VERSION "HNNBNNNYNNNNNNNNNNNNNNNNNNNNNNNNNNNNNNNNNN/4/%%%/4/'%**4NNN///"

NS_ :

BS_:

BU_: AFS_B8 Airbag_B8 Daempfer_B8 Gateway_B8 Getriebe_AL6000 Getriebe_DL5001 Getriebe_VL3002 LWR_B8 Motor_EDC17_003 Motor_EDC17_004 Motor_MED17_B8 Motor_MED9_B8 Motor_SIMOS8_B8 Motor_Slave_B8 Getriebe_AL1000 Motor_MED17_SIMOS8 Motor_EDC17 Gateway_Routing_PAG Gateway_VW EPB_D4 Motor_EDC17_D4 Motor_MED17_003 Hybrid_MSG Hybrid_DQ200 Motor_ME17_BY Motor_MED17_SIMOS8_D4 Motor_EDC17_B8 Getriebe_AL551_951_D4_C7 Getriebe_AL551_Hybrid_D4_C7 Getriebe_DL501_C7 Getriebe_VL381_C7 Motor_MED17_SIMOS8_D4_Hybrid SCU_D4 Gateway_D4C7 Motor_MED17_Q5_Hybrid Fahrwerk STH_D4 Airbag_D4 Gateway_PAG_002 Gateway_VW_T003 Gateway_D4 LEH_Hybrid SCR_C7 BMS_Hybrid Gateway_App_PAG Getriebe_AL1004 Motor_MED17_006 Getriebe_AL5000

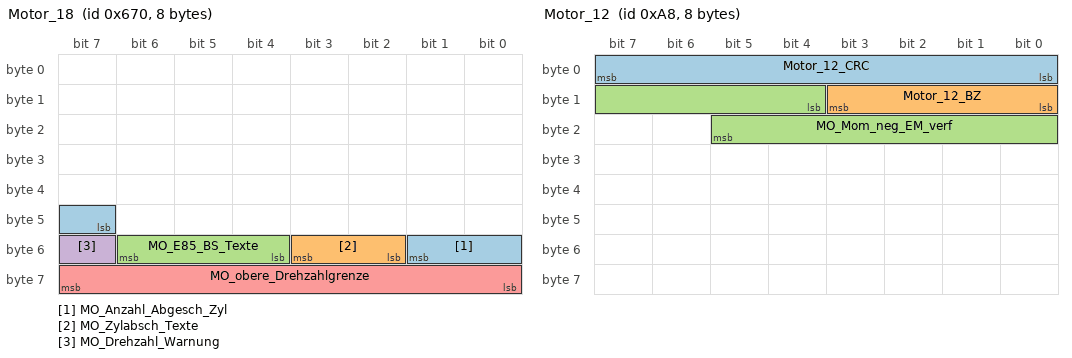
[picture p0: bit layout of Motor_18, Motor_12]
BO_ 1648 Motor_18: 8 Motor_EDC17_D4
 SG_ MO_Anzahl_Abgesch_Zyl : 47|3@1+ (1,0) [0|7] ""  Gateway_D4C7,Getriebe_AL551_951_D4_C7,Getriebe_DL501_C7
 SG_ MO_Zylabsch_Texte : 50|2@1+ (1,0) [0|3] ""  Gateway_D4C7
 SG_ MO_E85_BS_Texte : 52|3@1+ (1,0) [0|7] ""  Gateway_D4C7
 SG_ MO_Drehzahl_Warnung : 55|1@1+ (1,0) [0|1] ""  Gateway_D4C7
 SG_ MO_obere_Drehzahlgrenze : 56|8@1+ (50,0) [50|12750] "Unit_MinutInver"  Gateway_D4C7

BO_ 168 Motor_12: 8 Motor_MED17_Q5_Hybrid
 SG_ Motor_12_CRC : 0|8@1+ (1,0) [0|255] ""  Gateway_B8
 SG_ Motor_12_BZ : 8|4@1+ (1,0) [0|15] ""  Gateway_B8
 SG_ MO_Mom_neg_EM_verf : 12|10@1+ (1,0) [0|1021] "Unit_NewtoMeter"  Gateway_B8

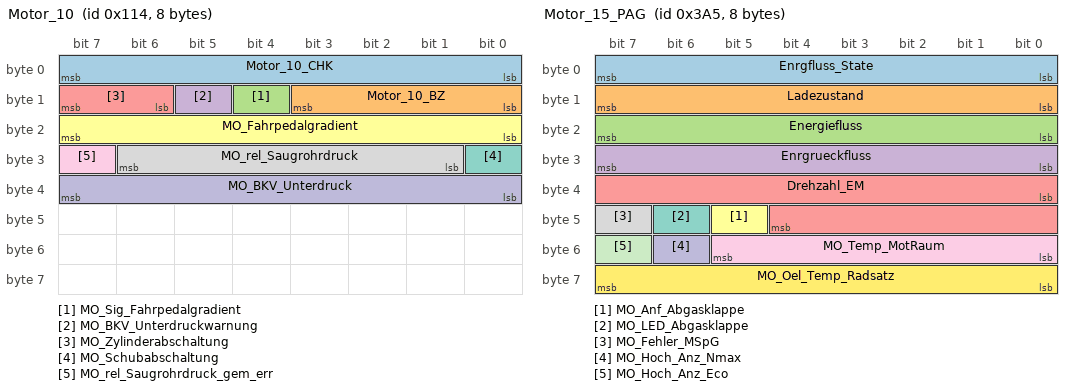
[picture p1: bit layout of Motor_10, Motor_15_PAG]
BO_ 276 Motor_10: 8 Motor_EDC17
 SG_ Motor_10_CHK : 0|8@1+ (1,0) [0|255] ""  Gateway_Routing_PAG,Gateway_VW
 SG_ Motor_10_BZ : 8|4@1+ (1,0) [0|15] ""  Gateway_Routing_PAG,Gateway_VW
 SG_ MO_Sig_Fahrpedalgradient : 12|1@1+ (1,0) [0|1] ""  Gateway_Routing_PAG,Gateway_VW
 SG_ MO_BKV_Unterdruckwarnung : 13|1@1+ (1,0) [0|1] ""  Gateway_Routing_PAG,Gateway_VW
 SG_ MO_Zylinderabschaltung : 14|2@1+ (1,0) [0|3] ""  Gateway_Routing_PAG,Gateway_VW
 SG_ MO_Fahrpedalgradient : 16|8@1+ (25,0) [0|6350] "Unit_PerCentPerSecon"  Gateway_Routing_PAG,Gateway_VW
 SG_ MO_Schubabschaltung : 24|1@1+ (1,0) [0|1] ""  Gateway_Routing_PAG,Gateway_VW
 SG_ MO_rel_Saugrohrdruck : 25|6@1+ (18,0) [0|1116] "Unit_MilliBar"  Gateway_Routing_PAG,Gateway_VW
 SG_ MO_rel_Saugrohrdruck_gem_err : 31|1@1+ (1,0) [0|1] ""  Gateway_Routing_PAG,Gateway_VW
 SG_ MO_BKV_Unterdruck : 32|8@1+ (4,0) [0|1012] "Unit_MilliBar"  Gateway_Routing_PAG,Gateway_VW

BO_ 933 Motor_15_PAG: 8 Motor_EDC17
 SG_ Enrgfluss_State : 0|8@1+ (1,0) [0|254] ""  Gateway_Routing_PAG
 SG_ Ladezustand : 8|8@1+ (1,0) [0|100] "Unit_PerCent"  Gateway_Routing_PAG
 SG_ Energiefluss : 16|8@1+ (1,-128) [-100|100] "Unit_PerCent"  Gateway_Routing_PAG
 SG_ Enrgrueckfluss : 24|8@1+ (0.2,0) [0|50.8] ""  Gateway_Routing_PAG
 SG_ Drehzahl_EM : 32|13@1+ (1,0) [0|8000] ""  Gateway_Routing_PAG
 SG_ MO_Anf_Abgasklappe : 45|1@1+ (1,0) [0|1] ""  Gateway_Routing_PAG
 SG_ MO_LED_Abgasklappe : 46|1@1+ (1,0) [0|1] ""  Gateway_Routing_PAG
 SG_ MO_Fehler_MSpG : 47|1@1+ (1,0) [0|1] ""  Gateway_Routing_PAG
 SG_ MO_Temp_MotRaum : 48|6@1+ (3,-48) [-48|141] "Unit_DegreCelsi"  Gateway_Routing_PAG
 SG_ MO_Hoch_Anz_Nmax : 54|1@1+ (1,0) [0|1] ""  Gateway_Routing_PAG
 SG_ MO_Hoch_Anz_Eco : 55|1@1+ (1,0) [0|1] ""  Gateway_Routing_PAG
 SG_ MO_Oel_Temp_Radsatz : 56|8@1+ (1,-60) [-60|193] "Unit_DegreCelsi"  Gateway_Routing_PAG

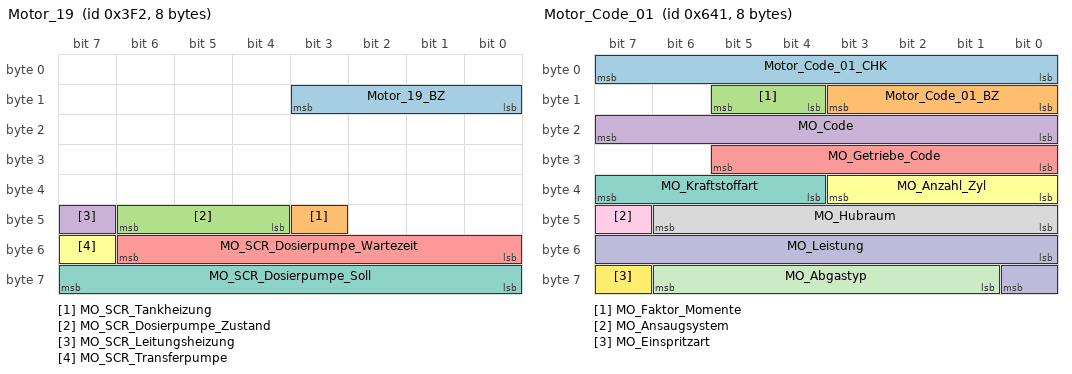
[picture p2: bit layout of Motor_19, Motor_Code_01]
BO_ 1010 Motor_19: 8 Motor_EDC17_D4
 SG_ Motor_19_BZ : 8|4@1+ (1,0) [0|15] ""  SCR_C7
 SG_ MO_SCR_Tankheizung : 43|1@1+ (1,0) [0|1] ""  SCR_C7
 SG_ MO_SCR_Dosierpumpe_Zustand : 44|3@1+ (1,0) [0|7] ""  SCR_C7
 SG_ MO_SCR_Leitungsheizung : 47|1@1+ (1,0) [0|1] ""  SCR_C7
 SG_ MO_SCR_Dosierpumpe_Wartezeit : 48|7@1+ (1,0) [0|120] "Unit_Secon"  SCR_C7
 SG_ MO_SCR_Transferpumpe : 55|1@1+ (1,0) [0|1] ""  SCR_C7
 SG_ MO_SCR_Dosierpumpe_Soll : 56|8@1+ (0.4,0) [0|100] "Unit_PerCent"  SCR_C7

BO_ 1601 Motor_Code_01: 8 Motor_EDC17_003
 SG_ Motor_Code_01_CHK : 0|8@1+ (1,0) [0|255] ""  Daempfer_B8,Gateway_B8,Getriebe_AL6000,Getriebe_DL5001,Getriebe_VL3002
 SG_ Motor_Code_01_BZ : 8|4@1+ (1,0) [0|15] ""  Daempfer_B8,Gateway_B8,Getriebe_AL6000,Getriebe_DL5001,Getriebe_VL3002
 SG_ MO_Faktor_Momente : 12|2@1+ (1,0) [0|3] ""  Daempfer_B8,Gateway_B8,Getriebe_AL6000,Getriebe_DL5001,Getriebe_VL3002
 SG_ MO_Code : 16|8@1+ (1,0) [0|255] ""  Gateway_B8,Getriebe_AL6000,Getriebe_DL5001,Getriebe_VL3002
 SG_ MO_Getriebe_Code : 24|6@1+ (1,0) [0|63] ""  Gateway_B8,Getriebe_AL6000,Getriebe_DL5001,Getriebe_VL3002
 SG_ MO_Anzahl_Zyl : 32|4@1+ (1,0) [0|15] ""  Gateway_B8
 SG_ MO_Kraftstoffart : 36|4@1+ (1,0) [0|15] ""  Gateway_B8
 SG_ MO_Hubraum : 40|7@1+ (0.1,0) [0|12.7] "l"  Gateway_B8
 SG_ MO_Ansaugsystem : 47|1@1+ (1,0) [0|1] ""  Gateway_B8
 SG_ MO_Leistung : 48|9@1+ (1,0) [0|511] "kW"  Gateway_B8
 SG_ MO_Abgastyp : 57|6@1+ (1,0) [0|63] ""  Gateway_B8,Getriebe_AL6000
 SG_ MO_Einspritzart : 63|1@1+ (1,0) [0|1] ""  Gateway_B8

BO_ 157 Motor_Hybrid_01: 8 Motor_MED17_SIMOS8
 SG_ Motor_Hybrid_01_CHK : 0|8@1+ (1,0) [0|255] ""  Getriebe_AL1000
 SG_ Motor_Hybrid_01_BZ : 8|4@1+ (1,0) [0|15] ""  BMS_Hybrid,Getriebe_AL1000
 SG_ MO_HYB_IstStatusK0 : 12|2@1+ (1,0) [0|3] ""  Getriebe_AL1000
 SG_ MO_HYB_max_ind_VM_Mom : 16|10@1+ (1,0) [0|1021] "Unit_NewtoMeter"  Getriebe_AL1000
 SG_ MO_HYB_Zielzustand : 26|3@1+ (1,0) [0|7] ""  BMS_Hybrid,Gateway_App_PAG,Getriebe_AL1000
 SG_ MO_HYB_Startmodus : 29|3@1+ (1,0) [0|7] ""  Getriebe_AL1000
 SG_ MO_HYB_Startmodus_PQ3x : 32|1@1+ (1,0) [0|1] "" Vector__XXX
 SG_ MO_HYB_Stoppmodus : 33|1@1+ (1,0) [0|1] "" Vector__XXX
 SG_ MO_HYB_VM_Mom_oE : 40|10@1+ (1,-100) [-100|922] "Unit_NewtoMeter"  Getriebe_AL1000
 SG_ MO_HYB_VM_aktiv : 50|1@1+ (1,0) [0|1] ""  Gateway_Routing_PAG,Getriebe_AL1000
 SG_ MO_HYB_Schaltverhinderung : 51|1@1+ (1,0) [0|1] ""  Getriebe_AL1000
 SG_ MO_HYB_Selektor_Momverlauf_EM M : 53|3@1+ (1,0) [0|7] ""  Getriebe_AL1000
 SG_ MO_HYB_Momverlauf_Rek m1 : 56|8@1+ (2,0) [0|510] "Unit_NewtoMeter"  Getriebe_AL1000
 SG_ MO_HYB_KnickDZ_Rek m2 : 56|8@1+ (12.5,0) [0|3150] "Unit_MinutInver"  Getriebe_AL1000
 SG_ MO_HYB_Momverlauf_EM m3 : 56|8@1+ (2,0) [0|510] "Unit_NewtoMeter"  Getriebe_AL1000
 SG_ MO_HYB_KnickDZ_EM m4 : 56|8@1+ (12.5,0) [0|3150] "Unit_MinutInver"  Getriebe_AL1000

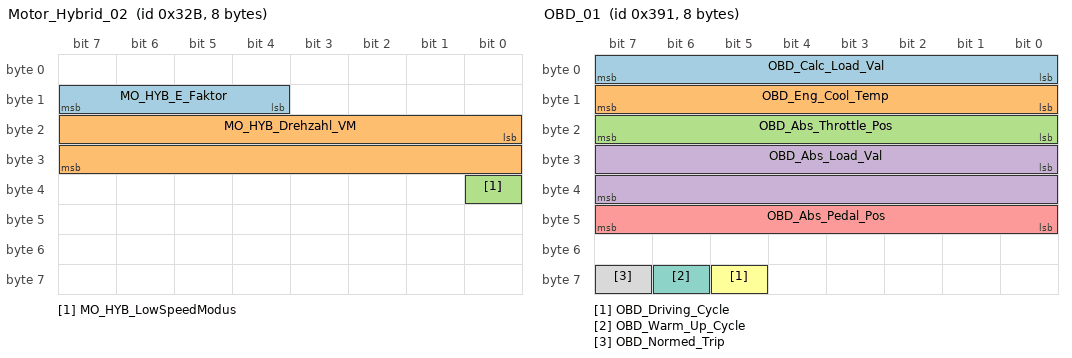
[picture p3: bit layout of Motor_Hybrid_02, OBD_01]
BO_ 811 Motor_Hybrid_02: 8 Motor_MED17_006
 SG_ MO_HYB_E_Faktor : 12|4@1+ (1,0) [0|15] ""  Getriebe_AL1004
 SG_ MO_HYB_Drehzahl_VM : 16|16@1+ (0.25,0) [0|16256] "Unit_MinutInver"  Getriebe_AL1004
 SG_ MO_HYB_LowSpeedModus : 32|1@1+ (1,0) [0|1] ""  Getriebe_AL1004

BO_ 1090 MotorSlave_01: 1 Motor_Slave_B8
 SG_ MOS_KD_Fehler : 0|1@1+ (1,0) [0|1] ""  Gateway_B8

BO_ 1728 NMH_Gateway: 7 Gateway_B8
 SG_ NMH_GW_Start_1 : 0|1@1+ (1,0) [0|1] ""  Getriebe_AL6000,Getriebe_DL5001,Getriebe_VL3002,Motor_EDC17_003,Motor_EDC17_004,Motor_MED17_B8,Motor_MED9_B8,Motor_SIMOS8_B8
 SG_ NMH_GW_Start_2 : 1|1@1+ (1,0) [0|1] "" Vector__XXX
 SG_ NMH_GW_Normal_Mode_1 : 2|1@1+ (1,0) [0|1] "" Vector__XXX
 SG_ NMH_GW_Normal_Mode_2 : 3|1@1+ (1,0) [0|1] "" Vector__XXX
 SG_ NMH_GW_Car_WakeUp : 6|1@1+ (1,0) [0|1] "" Vector__XXX
 SG_ NMH_GW_Per_WakeUp : 8|5@1+ (1,0) [0|31] "" Vector__XXX
 SG_ NMH_GW_Fkt_WakeUp : 13|3@1+ (1,0) [0|7] "" Vector__XXX
 SG_ NMH_GW_NM_aktiv_Klemme_15 : 16|1@1+ (1,0) [0|1] "" Vector__XXX
 SG_ NMH_GW_NM_aktiv_Diagnose : 17|1@1+ (1,0) [0|1] "" Vector__XXX
 SG_ NMH_GW_NM_aktiv_Start : 18|1@1+ (1,0) [0|1] "" Vector__XXX
 SG_ NMH_GW_NM_aktiv_BDM : 19|1@1+ (1,0) [0|1] "" Vector__XXX
 SG_ NMH_GW_NM_aktiv_Warnblinken : 20|1@1+ (1,0) [0|1] "" Vector__XXX
 SG_ NMH_GW_NM_aktiv_ESP : 21|1@1+ (1,0) [0|1] "" Vector__XXX
 SG_ NMH_GW_Abschaltstufe_3 : 24|1@1+ (1,0) [0|1] "" Vector__XXX
 SG_ NMH_GW_SG_Fehlerdauer : 25|1@1+ (1,0) [0|1] "" Vector__XXX
 SG_ NMH_GW_STH_Wakeup : 26|1@1+ (1,0) [0|1] "" Vector__XXX
 SG_ NMH_GW_TimeOut_Fehler : 33|1@1+ (1,0) [0|1] "" Vector__XXX
 SG_ NMH_GW_CAN_Diag_deaktiv : 34|1@1+ (1,0) [0|1] "" Vector__XXX
 SG_ NMH_GW_KompSchutz : 35|1@1+ (1,0) [0|1] "" Vector__XXX
 SG_ NMH_GW_Mute_Mode : 36|1@1+ (1,0) [0|1] "" Vector__XXX
 SG_ NMH_GW_Transport_Mode : 37|1@1+ (1,0) [0|1] "" Vector__XXX
 SG_ NMH_GW_Abschaltstufe_aktiv : 38|1@1+ (1,0) [0|1] "" Vector__XXX
 SG_ NMH_GW_Eindraht_Fehler : 39|1@1+ (1,0) [0|1] "" Vector__XXX
 SG_ NMH_GW_ACAN : 40|1@1+ (1,0) [0|1] "" Vector__XXX
 SG_ NMH_GW_KombiCAN : 41|1@1+ (1,0) [0|1] "" Vector__XXX
 SG_ NMH_GW_KomfortCAN : 42|1@1+ (1,0) [0|1] "" Vector__XXX
 SG_ NMH_GW_Infotainment : 43|1@1+ (1,0) [0|1] "" Vector__XXX
 SG_ NMH_GW_WakeUp_CAN_Bus : 48|3@1+ (1,0) [0|7] "" Vector__XXX

BO_ 1730 NMH_Getriebe: 7 Getriebe_AL6000
 SG_ NMH_GE_Start_1 : 0|1@1+ (1,0) [0|1] ""  Motor_EDC17_003,Motor_EDC17_004,Motor_MED17_B8,Motor_MED9_B8,Motor_SIMOS8_B8
 SG_ NMH_GE_Start_2 : 1|1@1+ (1,0) [0|1] "" Vector__XXX
 SG_ NMH_GE_Normal_Mode_1 : 2|1@1+ (1,0) [0|1] "" Vector__XXX
 SG_ NMH_GE_Normal_Mode_2 : 3|1@1+ (1,0) [0|1] "" Vector__XXX
 SG_ NMH_GE_Car_WakeUp : 6|1@1+ (1,0) [0|1] ""  Gateway_B8
 SG_ NMH_GE_Per_WakeUp : 8|5@1+ (1,0) [0|31] "" Vector__XXX
 SG_ NMH_GE_Fkt_WakeUp : 13|3@1+ (1,0) [0|7] "" Vector__XXX
 SG_ NMH_GE_NM_aktiv_Klemme_15 : 16|1@1+ (1,0) [0|1] "" Vector__XXX
 SG_ NMH_GE_NM_aktiv_Diagnose : 17|1@1+ (1,0) [0|1] "" Vector__XXX
 SG_ NMH_GE_NM_aktiv_Start : 18|1@1+ (1,0) [0|1] "" Vector__XXX
 SG_ NMH_GE_kein_NL : 24|1@1+ (1,0) [0|1] "" Vector__XXX
 SG_ NMH_GE_NL_Daten_EEPROM : 25|1@1+ (1,0) [0|1] "" Vector__XXX
 SG_ NMH_GE_NL_Drucksens : 26|1@1+ (1,0) [0|1] "" Vector__XXX
 SG_ NMH_GE_NL_Abtrieb : 27|1@1+ (1,0) [0|1] "" Vector__XXX
 SG_ NMH_GE_NL_Waehlhebel : 28|1@1+ (1,0) [0|1] "" Vector__XXX
 SG_ NMH_GE_NL_Wegfahrsperre : 29|1@1+ (1,0) [0|1] "" Vector__XXX
 SG_ NMH_GE_TimeOut_Fehler : 33|1@1+ (1,0) [0|1] "" Vector__XXX
 SG_ NMH_GE_CAN_Diag_deaktiv : 34|1@1+ (1,0) [0|1] "" Vector__XXX
 SG_ NMH_GE_KompSchutz : 35|1@1+ (1,0) [0|1] "" Vector__XXX
 SG_ NMH_GE_Mute_Mode : 36|1@1+ (1,0) [0|1] "" Vector__XXX
 SG_ NMH_GE_Transport_Mode : 37|1@1+ (1,0) [0|1] "" Vector__XXX
 SG_ NMH_GE_Abschaltstufe_aktiv : 38|1@1+ (1,0) [0|1] "" Vector__XXX
 SG_ NMH_GE_Eindraht_Fehler : 39|1@1+ (1,0) [0|1] "" Vector__XXX

BO_ 1729 NMH_Motor: 7 Motor_EDC17_B8
 SG_ NMH_MO_Start_1 : 0|1@1+ (1,0) [0|1] ""  Getriebe_AL6000,Getriebe_DL5001,Getriebe_VL3002,Motor_EDC17_B8,Motor_MED17_003,Motor_MED9_B8
 SG_ NMH_MO_Start_2 : 1|1@1+ (1,0) [0|1] "" Vector__XXX
 SG_ NMH_MO_Normal_Mode_1 : 2|1@1+ (1,0) [0|1] "" Vector__XXX
 SG_ NMH_MO_Normal_Mode_2 : 3|1@1+ (1,0) [0|1] "" Vector__XXX
 SG_ NMH_MO_Car_WakeUp : 6|1@1+ (1,0) [0|1] ""  Gateway_B8
 SG_ NMH_MO_Per_WakeUp : 8|5@1+ (1,0) [0|31] "" Vector__XXX
 SG_ NMH_MO_Fkt_WakeUp : 13|3@1+ (1,0) [0|7] "" Vector__XXX
 SG_ NMH_MO_NM_aktiv_Klemme_15 : 16|1@1+ (1,0) [0|1] "" Vector__XXX
 SG_ NMH_MO_NM_aktiv_Diagnose : 17|1@1+ (1,0) [0|1] "" Vector__XXX
 SG_ NMH_MO_NM_aktiv_Start : 18|1@1+ (1,0) [0|1] "" Vector__XXX
 SG_ NMH_MO_NM_aktiv_EKP_Vorlauf : 19|1@1+ (1,0) [0|1] "" Vector__XXX
 SG_ NMH_MO_NM_aktiv_STH_Betrieb : 20|1@1+ (1,0) [0|1] "" Vector__XXX
 SG_ NMH_MO_NM_aktiv_HV_Abschaltung : 21|1@1+ (1,0) [0|1] "" Vector__XXX
 SG_ NMH_MO_kein_NL : 24|1@1+ (1,0) [0|1] "" Vector__XXX
 SG_ NMH_MO_NL_Kuehlerluefter : 25|1@1+ (1,0) [0|1] "" Vector__XXX
 SG_ NMH_MO_NL_Diagnose : 26|1@1+ (1,0) [0|1] "" Vector__XXX
 SG_ NMH_MO_NL_WFS : 27|1@1+ (1,0) [0|1] "" Vector__XXX
 SG_ NMH_MO_NL_EEPROM : 28|1@1+ (1,0) [0|1] "" Vector__XXX
 SG_ NMH_MO_NL_Sonstige : 29|1@1+ (1,0) [0|1] "" Vector__XXX
 SG_ NMH_MO_TimeOut_Fehler : 33|1@1+ (1,0) [0|1] "" Vector__XXX
 SG_ NMH_MO_CAN_Diag_deaktiv : 34|1@1+ (1,0) [0|1] "" Vector__XXX
 SG_ NMH_MO_KompSchutz : 35|1@1+ (1,0) [0|1] "" Vector__XXX
 SG_ NMH_MO_Mute_Mode : 36|1@1+ (1,0) [0|1] "" Vector__XXX
 SG_ NMH_MO_Transport_Mode : 37|1@1+ (1,0) [0|1] "" Vector__XXX
 SG_ NMH_MO_Abschaltstufe_aktiv : 38|1@1+ (1,0) [0|1] "" Vector__XXX
 SG_ NMH_MO_Eindraht_Fehler : 39|1@1+ (1,0) [0|1] "" Vector__XXX
 SG_ NMH_MO_Lokalaktiv : 48|1@1+ (1,0) [0|1] ""  Gateway_B8
 SG_ NMH_MO_Subsystemaktiv : 49|1@1+ (1,0) [0|1] ""  Gateway_B8

BO_ 913 OBD_01: 8 Motor_EDC17_003
 SG_ OBD_Calc_Load_Val : 0|8@1+ (0.39215686275,0) [0|99.6061] "%"  Getriebe_AL6000,Getriebe_DL5001,Getriebe_VL3002
 SG_ OBD_Eng_Cool_Temp : 8|8@1+ (1,-40) [-40|214] "°C"  Getriebe_AL6000,Getriebe_DL5001,Getriebe_VL3002
 SG_ OBD_Abs_Throttle_Pos : 16|8@1+ (0.39215686275,0) [0|99.6061] "%"  Getriebe_AL6000,Getriebe_DL5001,Getriebe_VL3002
 SG_ OBD_Abs_Load_Val : 24|16@1+ (0.39215686275,0) [0|25699.1581] "%"  Getriebe_AL6000,Getriebe_DL5001,Getriebe_VL3002
 SG_ OBD_Abs_Pedal_Pos : 40|8@1+ (0.39215686275,0) [0|99.6061] "%"  Getriebe_AL6000,Getriebe_DL5001,Getriebe_VL3002
 SG_ OBD_Driving_Cycle : 61|1@1+ (1,0) [0|1] ""  Getriebe_AL6000,Getriebe_DL5001,Getriebe_VL3002
 SG_ OBD_Warm_Up_Cycle : 62|1@1+ (1,0) [0|1] ""  Gateway_B8,Getriebe_AL6000,Getriebe_DL5001,Getriebe_VL3002
 SG_ OBD_Normed_Trip : 63|1@1+ (1,0) [0|1] ""  Getriebe_AL6000,Getriebe_DL5001,Getriebe_VL3002

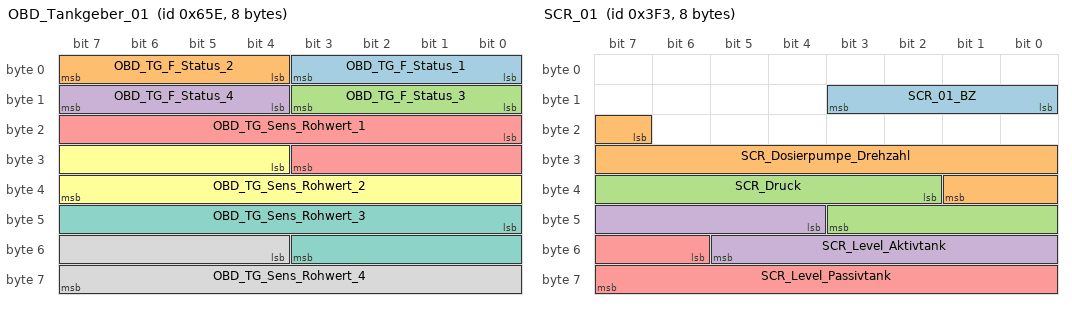
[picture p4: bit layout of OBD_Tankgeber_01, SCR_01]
BO_ 1630 OBD_Tankgeber_01: 8 Gateway_B8
 SG_ OBD_TG_F_Status_1 : 0|4@1+ (1,0) [0|15] ""  Motor_EDC17_003,Motor_EDC17_004,Motor_MED17_B8,Motor_MED9_B8,Motor_SIMOS8_B8
 SG_ OBD_TG_F_Status_2 : 4|4@1+ (1,0) [0|15] ""  Motor_EDC17_003,Motor_EDC17_004,Motor_MED17_B8,Motor_MED9_B8,Motor_SIMOS8_B8
 SG_ OBD_TG_F_Status_3 : 8|4@1+ (1,0) [0|15] ""  Motor_EDC17_003,Motor_EDC17_004,Motor_MED17_B8,Motor_MED9_B8,Motor_SIMOS8_B8
 SG_ OBD_TG_F_Status_4 : 12|4@1+ (1,0) [0|15] ""  Motor_EDC17_003,Motor_EDC17_004,Motor_MED17_B8,Motor_MED9_B8,Motor_SIMOS8_B8
 SG_ OBD_TG_Sens_Rohwert_1 : 16|12@1+ (0.5,0) [0|2047.5] "Ohm"  Motor_EDC17_003,Motor_EDC17_004,Motor_MED17_B8,Motor_MED9_B8,Motor_SIMOS8_B8
 SG_ OBD_TG_Sens_Rohwert_2 : 28|12@1+ (0.5,0) [0|2047.5] "Ohm"  Motor_EDC17_003,Motor_EDC17_004,Motor_MED17_B8,Motor_MED9_B8,Motor_SIMOS8_B8
 SG_ OBD_TG_Sens_Rohwert_3 : 40|12@1+ (0.5,0) [0|2047.5] "Ohm"  Motor_EDC17_003,Motor_EDC17_004,Motor_MED17_B8,Motor_MED9_B8,Motor_SIMOS8_B8
 SG_ OBD_TG_Sens_Rohwert_4 : 52|12@1+ (0.5,0) [0|2047.5] "Ohm"  Motor_EDC17_003,Motor_EDC17_004,Motor_MED17_B8,Motor_MED9_B8,Motor_SIMOS8_B8

BO_ 1011 SCR_01: 8 SCR_C7
 SG_ SCR_01_BZ : 8|4@1+ (1,0) [0|15] ""  Motor_EDC17_D4
 SG_ SCR_Dosierpumpe_Drehzahl : 23|11@1+ (4,-4080) [-4080|4100] "Unit_MinutInver"  Motor_EDC17_D4
 SG_ SCR_Druck : 34|10@1+ (5,0) [0|5000] "Unit_MilliVolt"  Motor_EDC17_D4
 SG_ SCR_Level_Aktivtank : 44|10@1+ (5,0) [0|5000] "Unit_MilliVolt"  Motor_EDC17_D4
 SG_ SCR_Level_Passivtank : 54|10@1+ (5,0) [0|5000] "Unit_MilliVolt"  Motor_EDC17_D4

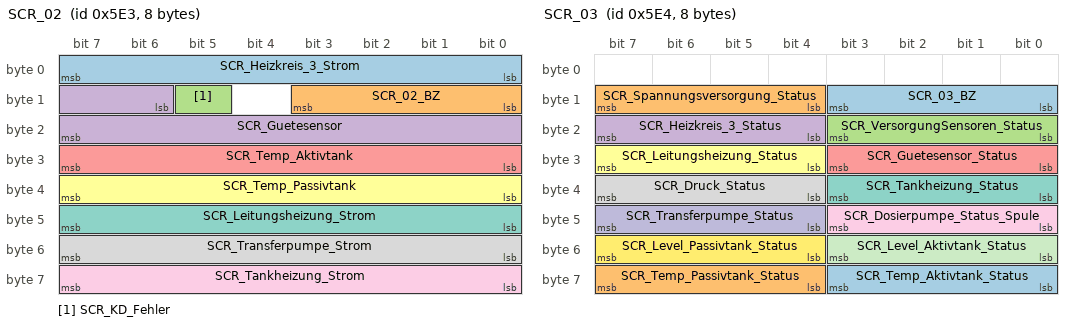
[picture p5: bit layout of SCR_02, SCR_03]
BO_ 1507 SCR_02: 8 SCR_C7
 SG_ SCR_Heizkreis_3_Strom : 0|8@1+ (0.1,0) [0|14] "Unit_Amper"  Motor_EDC17_D4
 SG_ SCR_02_BZ : 8|4@1+ (1,0) [0|15] ""  Motor_EDC17_D4
 SG_ SCR_KD_Fehler : 13|1@1+ (1,0) [0|1] ""  Gateway_D4C7
 SG_ SCR_Guetesensor : 14|10@1+ (5,0) [0|5000] "Unit_MilliVolt"  Motor_EDC17_D4
 SG_ SCR_Temp_Aktivtank : 24|8@1+ (20,0) [0|5000] "Unit_MilliVolt"  Motor_EDC17_D4
 SG_ SCR_Temp_Passivtank : 32|8@1+ (20,0) [0|5000] "Unit_MilliVolt"  Motor_EDC17_D4
 SG_ SCR_Leitungsheizung_Strom : 40|8@1+ (0.1,0) [0|14] "Unit_Amper"  Motor_EDC17_D4
 SG_ SCR_Transferpumpe_Strom : 48|8@1+ (0.1,0) [0|14] "Unit_Amper"  Motor_EDC17_D4
 SG_ SCR_Tankheizung_Strom : 56|8@1+ (0.1,0) [0|14] "Unit_Amper"  Motor_EDC17_D4

BO_ 1508 SCR_03: 8 SCR_C7
 SG_ SCR_03_BZ : 8|4@1+ (1,0) [0|15] ""  Motor_EDC17_D4
 SG_ SCR_Spannungsversorgung_Status : 12|4@1+ (1,0) [0|15] ""  Motor_EDC17_D4
 SG_ SCR_VersorgungSensoren_Status : 16|4@1+ (1,0) [0|15] ""  Motor_EDC17_D4
 SG_ SCR_Heizkreis_3_Status : 20|4@1+ (1,0) [0|15] ""  Motor_EDC17_D4
 SG_ SCR_Guetesensor_Status : 24|4@1+ (1,0) [0|15] ""  Motor_EDC17_D4
 SG_ SCR_Leitungsheizung_Status : 28|4@1+ (1,0) [0|15] ""  Motor_EDC17_D4
 SG_ SCR_Tankheizung_Status : 32|4@1+ (1,0) [0|15] ""  Motor_EDC17_D4
 SG_ SCR_Druck_Status : 36|4@1+ (1,0) [0|15] ""  Motor_EDC17_D4
 SG_ SCR_Dosierpumpe_Status_Spule : 40|4@1+ (1,0) [0|15] ""  Motor_EDC17_D4
 SG_ SCR_Transferpumpe_Status : 44|4@1+ (1,0) [0|15] ""  Motor_EDC17_D4
 SG_ SCR_Level_Aktivtank_Status : 48|4@1+ (1,0) [0|15] ""  Motor_EDC17_D4
 SG_ SCR_Level_Passivtank_Status : 52|4@1+ (1,0) [0|15] ""  Motor_EDC17_D4
 SG_ SCR_Temp_Aktivtank_Status : 56|4@1+ (1,0) [0|15] ""  Motor_EDC17_D4
 SG_ SCR_Temp_Passivtank_Status : 60|4@1+ (1,0) [0|15] ""  Motor_EDC17_D4

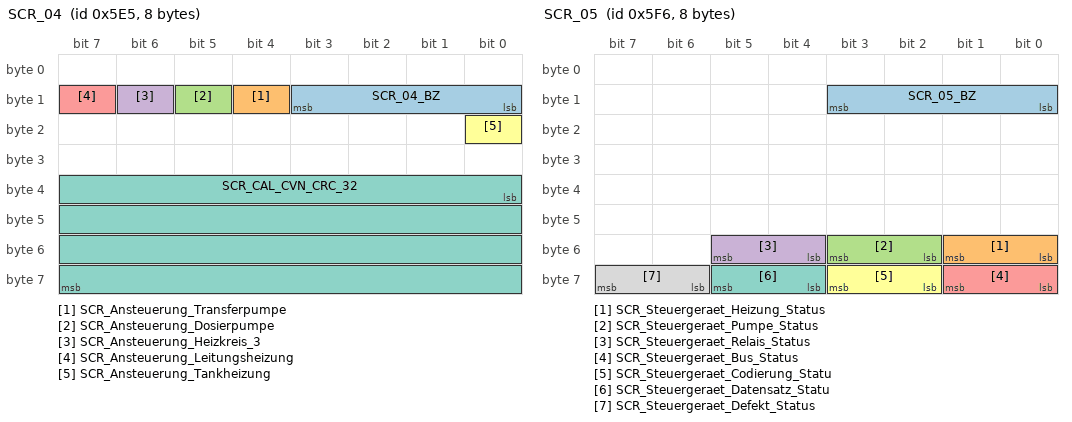
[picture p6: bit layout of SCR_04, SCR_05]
BO_ 1509 SCR_04: 8 SCR_C7
 SG_ SCR_04_BZ : 8|4@1+ (1,0) [0|15] ""  Motor_EDC17_D4
 SG_ SCR_Ansteuerung_Transferpumpe : 12|1@1+ (1,0) [0|1] ""  Motor_EDC17_D4
 SG_ SCR_Ansteuerung_Dosierpumpe : 13|1@1+ (1,0) [0|1] ""  Motor_EDC17_D4
 SG_ SCR_Ansteuerung_Heizkreis_3 : 14|1@1+ (1,0) [0|1] ""  Motor_EDC17_D4
 SG_ SCR_Ansteuerung_Leitungsheizung : 15|1@1+ (1,0) [0|1] ""  Motor_EDC17_D4
 SG_ SCR_Ansteuerung_Tankheizung : 16|1@1+ (1,0) [0|1] ""  Motor_EDC17_D4
 SG_ SCR_CAL_CVN_CRC_32 : 32|32@1+ (1,0) [0|4294967295] ""  Motor_EDC17_D4

BO_ 1526 SCR_05: 8 SCR_C7
 SG_ SCR_05_BZ : 8|4@1+ (1,0) [0|15] ""  Motor_EDC17_D4
 SG_ SCR_Steuergeraet_Heizung_Status : 48|2@1+ (1,0) [0|3] ""  Motor_EDC17_D4
 SG_ SCR_Steuergeraet_Pumpe_Status : 50|2@1+ (1,0) [0|3] ""  Motor_EDC17_D4
 SG_ SCR_Steuergeraet_Relais_Status : 52|2@1+ (1,0) [0|3] ""  Motor_EDC17_D4
 SG_ SCR_Steuergeraet_Bus_Status : 56|2@1+ (1,0) [0|3] ""  Motor_EDC17_D4
 SG_ SCR_Steuergeraet_Codierung_Statu : 58|2@1+ (1,0) [0|3] ""  Motor_EDC17_D4
 SG_ SCR_Steuergeraet_Datensatz_Statu : 60|2@1+ (1,0) [0|3] ""  Motor_EDC17_D4
 SG_ SCR_Steuergeraet_Defekt_Status : 62|2@1+ (1,0) [0|3] ""  Motor_EDC17_D4

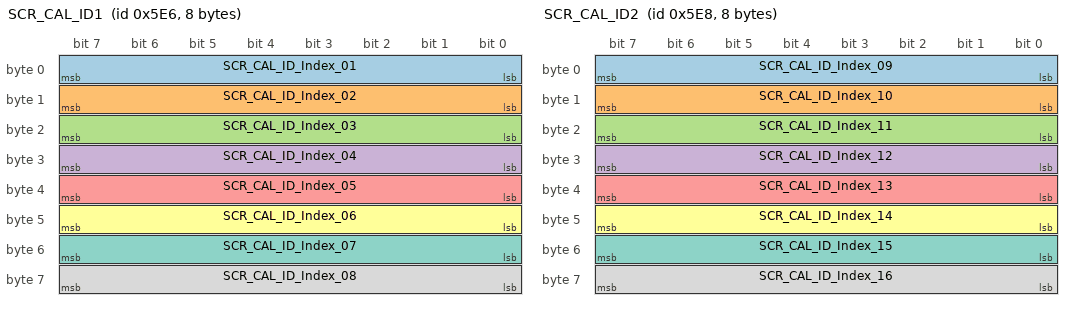
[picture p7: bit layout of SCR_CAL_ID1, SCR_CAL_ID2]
BO_ 1510 SCR_CAL_ID1: 8 SCR_C7
 SG_ SCR_CAL_ID_Index_01 : 0|8@1+ (1,0) [0|255] ""  Motor_EDC17_D4
 SG_ SCR_CAL_ID_Index_02 : 8|8@1+ (1,0) [0|255] ""  Motor_EDC17_D4
 SG_ SCR_CAL_ID_Index_03 : 16|8@1+ (1,0) [0|255] ""  Motor_EDC17_D4
 SG_ SCR_CAL_ID_Index_04 : 24|8@1+ (1,0) [0|255] ""  Motor_EDC17_D4
 SG_ SCR_CAL_ID_Index_05 : 32|8@1+ (1,0) [0|255] ""  Motor_EDC17_D4
 SG_ SCR_CAL_ID_Index_06 : 40|8@1+ (1,0) [0|255] ""  Motor_EDC17_D4
 SG_ SCR_CAL_ID_Index_07 : 48|8@1+ (1,0) [0|255] ""  Motor_EDC17_D4
 SG_ SCR_CAL_ID_Index_08 : 56|8@1+ (1,0) [0|255] ""  Motor_EDC17_D4

BO_ 1512 SCR_CAL_ID2: 8 SCR_C7
 SG_ SCR_CAL_ID_Index_09 : 0|8@1+ (1,0) [0|255] ""  Motor_EDC17_D4
 SG_ SCR_CAL_ID_Index_10 : 8|8@1+ (1,0) [0|255] ""  Motor_EDC17_D4
 SG_ SCR_CAL_ID_Index_11 : 16|8@1+ (1,0) [0|255] ""  Motor_EDC17_D4
 SG_ SCR_CAL_ID_Index_12 : 24|8@1+ (1,0) [0|255] ""  Motor_EDC17_D4
 SG_ SCR_CAL_ID_Index_13 : 32|8@1+ (1,0) [0|255] ""  Motor_EDC17_D4
 SG_ SCR_CAL_ID_Index_14 : 40|8@1+ (1,0) [0|255] ""  Motor_EDC17_D4
 SG_ SCR_CAL_ID_Index_15 : 48|8@1+ (1,0) [0|255] ""  Motor_EDC17_D4
 SG_ SCR_CAL_ID_Index_16 : 56|8@1+ (1,0) [0|255] ""  Motor_EDC17_D4

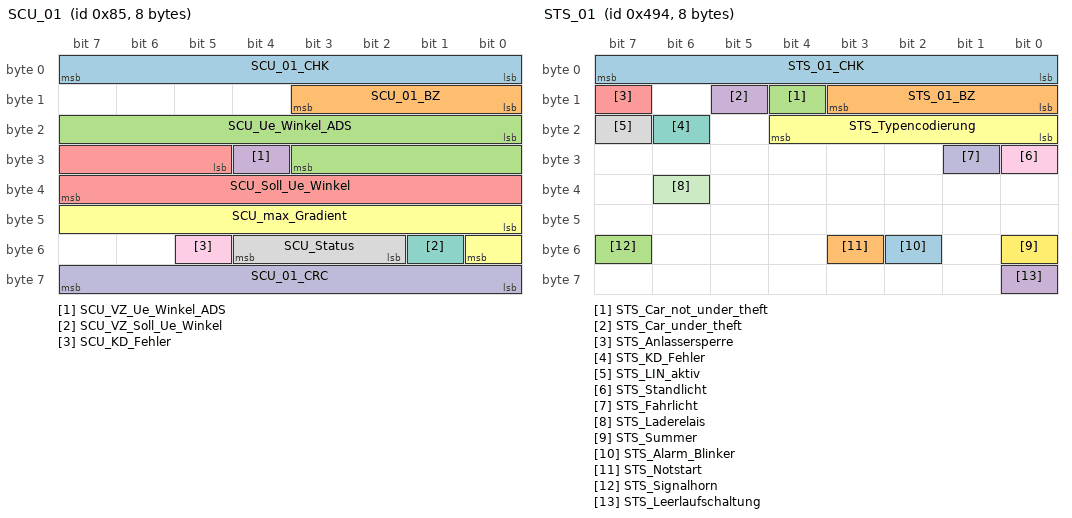
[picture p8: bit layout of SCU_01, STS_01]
BO_ 133 SCU_01: 8 Gateway_B8
 SG_ SCU_01_CHK : 0|8@1+ (1,0) [0|255] ""  Daempfer_B8,Motor_EDC17_003,Motor_EDC17_004,Motor_MED17_B8,Motor_MED9_B8,Motor_SIMOS8_B8
 SG_ SCU_01_BZ : 8|4@1+ (1,0) [0|15] ""  Daempfer_B8,Motor_EDC17_003,Motor_EDC17_004,Motor_MED17_B8,Motor_MED9_B8,Motor_SIMOS8_B8
 SG_ SCU_Ue_Winkel_ADS : 16|12@1+ (0.1,0) [0|409.3] "Grad"  AFS_B8,Daempfer_B8,Motor_EDC17_003,Motor_EDC17_004,Motor_MED17_B8,Motor_MED9_B8,Motor_SIMOS8_B8
 SG_ SCU_VZ_Ue_Winkel_ADS : 28|1@1+ (1,0) [0|1] ""  AFS_B8,Daempfer_B8,Motor_EDC17_003,Motor_EDC17_004,Motor_MED17_B8,Motor_MED9_B8,Motor_SIMOS8_B8
 SG_ SCU_Soll_Ue_Winkel : 29|11@1+ (0.1,0) [0|204.5] "Grad"  AFS_B8
 SG_ SCU_max_Gradient : 40|9@1+ (1,0) [0|510] "" Vector__XXX
 SG_ SCU_VZ_Soll_Ue_Winkel : 49|1@1+ (1,0) [0|1] ""  AFS_B8
 SG_ SCU_Status : 50|3@1+ (1,0) [0|7] ""  AFS_B8,Daempfer_B8,Motor_EDC17_003,Motor_EDC17_004,Motor_MED17_B8,Motor_MED9_B8,Motor_SIMOS8_B8
 SG_ SCU_KD_Fehler : 53|1@1+ (1,0) [0|1] "" Vector__XXX
 SG_ SCU_01_CRC : 56|8@1+ (1,0) [0|255] "" Vector__XXX

BO_ 1313 STH_01: 8 Gateway_B8
 SG_ STH_Funk_ein : 0|1@1+ (1,0) [0|1] "" Vector__XXX
 SG_ STH_Funk_aus : 1|1@1+ (1,0) [0|1] "" Vector__XXX
 SG_ STH_Zusatzheizung : 2|1@1+ (1,0) [0|1] "" Vector__XXX
 SG_ STH_LED : 3|1@1+ (1,0) [0|1] "" Vector__XXX
 SG_ STH_Pumpe_ein : 4|1@1+ (1,0) [0|1] "" Vector__XXX
 SG_ STH_Geblaese : 5|1@1+ (1,0) [0|1] "" Vector__XXX
 SG_ STH_EKP_Anst : 6|1@1+ (1,0) [0|1] ""  Motor_EDC17_003,Motor_EDC17_004,Motor_MED17_B8,Motor_SIMOS8_B8
 SG_ STH_Ventiloeffnungszeit : 8|6@1+ (1,0) [0|63] "min"  Motor_EDC17_003,Motor_EDC17_004,Motor_MED17_B8,Motor_SIMOS8_B8
 SG_ STH_Ventil_Status : 14|1@1+ (1,0) [0|1] "" Vector__XXX
 SG_ STH_Fehler_ElWaPu : 15|1@1+ (1,0) [0|1] ""  Motor_EDC17_D4,Motor_ME17_BY,Motor_MED17_SIMOS8_D4,Motor_MED17_SIMOS8_D4_Hybrid
 SG_ STH_Waermeeintrag : 16|6@1+ (1,0) [0|63] ""  Motor_EDC17_003,Motor_EDC17_004,Motor_MED17_B8,Motor_SIMOS8_B8
 SG_ STH_Pumpen_Anf_extern : 22|1@1+ (1,0) [0|1] "" Vector__XXX
 SG_ STH_KVS : 24|13@1+ (1,0) [0|8191] "ml" Vector__XXX
 SG_ STH_Fehlerstatus : 37|3@1+ (1,0) [0|7] "" Vector__XXX
 SG_ STH_Heizleistung : 40|8@1+ (1,0) [0|255] "" Vector__XXX
 SG_ STH_Wassertemp : 48|8@1+ (0.75,-40) [-40|142.25] "°C" Vector__XXX
 SG_ STH_Motorvorwaermung : 59|1@1+ (1,0) [0|1] ""  Motor_EDC17_003,Motor_EDC17_004,Motor_MED17_B8,Motor_SIMOS8_B8
 SG_ STH_Servicemode : 60|1@1+ (1,0) [0|1] "" Vector__XXX
 SG_ STH_war_aktiv : 61|1@1+ (1,0) [0|1] ""  Motor_EDC17_003,Motor_EDC17_004,Motor_MED17_B8,Motor_SIMOS8_B8
 SG_ STH_KVS_Ueberlauf : 62|1@1+ (1,0) [0|1] "" Vector__XXX
 SG_ STH_KD_Fehler : 63|1@1+ (1,0) [0|1] "" Vector__XXX

BO_ 1172 STS_01: 8 Gateway_D4
 SG_ STS_01_CHK : 0|8@1+ (1,0) [0|255] ""  Motor_EDC17_D4,Motor_MED17_SIMOS8_D4
 SG_ STS_01_BZ : 8|4@1+ (1,0) [0|15] ""  Motor_EDC17_D4,Motor_MED17_SIMOS8_D4
 SG_ STS_Car_not_under_theft : 12|1@1+ (1,0) [0|1] "" Vector__XXX
 SG_ STS_Car_under_theft : 13|1@1+ (1,0) [0|1] "" Vector__XXX
 SG_ STS_Anlassersperre : 15|1@1+ (1,0) [0|1] "" Vector__XXX
 SG_ STS_Typencodierung : 16|5@1+ (1,0) [0|31] "" Vector__XXX
 SG_ STS_KD_Fehler : 22|1@1+ (1,0) [0|1] "" Vector__XXX
 SG_ STS_LIN_aktiv : 23|1@1+ (1,0) [0|1] "" Vector__XXX
 SG_ STS_Standlicht : 24|1@1+ (1,0) [0|1] "" Vector__XXX
 SG_ STS_Fahrlicht : 25|1@1+ (1,0) [0|1] "" Vector__XXX
 SG_ STS_Laderelais : 38|1@1+ (1,0) [0|1] "" Vector__XXX
 SG_ STS_Summer : 48|1@1+ (1,0) [0|1] "" Vector__XXX
 SG_ STS_Alarm_Blinker : 50|1@1+ (1,0) [0|1] "" Vector__XXX
 SG_ STS_Notstart : 51|1@1+ (1,0) [0|1] "" Vector__XXX
 SG_ STS_Signalhorn : 55|1@1+ (1,0) [0|1] "" Vector__XXX
 SG_ STS_Leerlaufschaltung : 56|1@1+ (1,0) [0|1] ""  Motor_EDC17_D4,Motor_MED17_SIMOS8_D4

BO_ 1413 Systeminfo_01: 8 Gateway_B8
 SG_ SI_Int_CAN_gespiegelt : 0|1@1+ (1,0) [0|1] "" Vector__XXX
 SG_ SI_CAN_Komfort_Sleep : 1|1@1+ (1,0) [0|1] "" Vector__XXX
 SG_ SI_CAN_Dashboard_Sleep : 2|1@1+ (1,0) [0|1] "" Vector__XXX
 SG_ SI_CAN_Antrieb_Sleep : 3|1@1+ (1,0) [0|1] "" Vector__XXX
 SG_ SI_Infotainment_Sleep : 4|1@1+ (1,0) [0|1] "" Vector__XXX
 SG_ SI_CAN_Extended_Sleep : 5|1@1+ (1,0) [0|1] "" Vector__XXX
 SG_ SI_Fahrwerk_Sleep : 6|1@1+ (1,0) [0|1] "" Vector__XXX
 SG_ SI_Diagnose_Aktiv : 7|1@1+ (1,0) [0|1] "" Vector__XXX
 SG_ SI_QRS_Mode : 8|1@1+ (1,0) [0|1] ""  Getriebe_AL551_951_D4_C7
 SG_ SI_T_Mode : 9|1@1+ (1,0) [0|1] ""  Getriebe_AL551_951_D4_C7,Motor_EDC17_D4,Motor_ME17_BY,Motor_MED17_SIMOS8_D4
 SG_ SI_NWDF : 10|1@1+ (1,0) [0|1] "" Vector__XXX
 SG_ SI_NWDF_gueltig : 11|1@1+ (1,0) [0|1] "" Vector__XXX
 SG_ SI_Sammelfehler : 12|1@1+ (1,0) [0|1] "" Vector__XXX
 SG_ GW_KD_Fehler : 13|1@1+ (1,0) [0|1] "" Vector__XXX
 SG_ SI_CAN_Fahrwerk_Sleep : 14|1@1+ (1,0) [0|1] "" Vector__XXX
 SG_ SI_MOST_Status : 15|1@1+ (1,0) [0|1] "" Vector__XXX
 SG_ SI_Sammel_SG_Fehler : 56|6@1+ (1,0) [0|60] "" Vector__XXX
 SG_ SI_MO_WU : 63|1@1+ (1,0) [0|1] "" Vector__XXX

BO_ 1300 TPD_Airbag_02: 8 Gateway_B8
 SG_ TPD_Airbag_Data_2 : 0|64@1+ (1,0) [0|1] ""  Airbag_B8

BO_ 1196 TPD_Daempfer_01: 8 Gateway_B8
 SG_ TPD_Daempfer_Data_1 : 0|64@1+ (1,0) [0|1] ""  Daempfer_B8

BO_ 1215 TPD_Gateway_01: 8 Airbag_B8
 SG_ TPD_Gateway_Data_1 : 0|64@1+ (1,0) [0|1] ""  Gateway_B8

BO_ 1303 TPD_Gateway_02: 8 Airbag_B8
 SG_ TPD_Gateway_Data_2 : 0|64@1+ (1,0) [0|1] ""  Gateway_B8

BO_ 1186 TPD_Getriebe_01: 8 Gateway_B8
 SG_ TPD_Getriebe_Data_1 : 0|64@1+ (1,0) [0|1] ""  Getriebe_AL6000,Getriebe_DL5001,Getriebe_VL3002

BO_ 1190 TPD_LWR_AFS_01: 8 Gateway_B8
 SG_ TPD_LWR_AFS_Data_1 : 0|64@1+ (1,0) [0|1] ""  AFS_B8,LWR_B8

BO_ 1185 TPD_Motor_01: 8 Gateway_B8
 SG_ TPD_Motor_Data_1 : 0|64@1+ (1,0) [0|1] ""  Motor_EDC17_003,Motor_EDC17_004,Motor_MED17_B8,Motor_MED9_B8,Motor_SIMOS8_B8

BO_ 1205 TPD_MotorS_01: 8 Gateway_B8
 SG_ TPD_MotorS_Data_1 : 0|64@1+ (1,0) [0|1] ""  Motor_Slave_B8

BO_ 768 TPD_Tester_01: 8 AFS_B8
 SG_ TPD_Tester_Data_1 : 0|64@1+ (1,0) [0|1] ""  Gateway_B8

BO_ 769 TPD_Tester_02: 8 AFS_B8
 SG_ TPD_Tester_Data_2 : 0|64@1+ (1,0) [0|1] ""  Gateway_B8

BO_ 770 TPD_Tester_03: 8 AFS_B8
 SG_ TPD_Tester_Data_3 : 0|64@1+ (1,0) [0|1] ""  Gateway_B8

BO_ 771 TPD_Tester_04: 8 AFS_B8
 SG_ TPD_Tester_Data_4 : 0|64@1+ (1,0) [0|1] ""  Gateway_B8

BO_ 772 TPD_Tester_05: 8 AFS_B8
 SG_ TPD_Tester_Data_5 : 0|64@1+ (1,0) [0|1] ""  Gateway_B8

BO_ 773 TPD_Tester_06: 8 AFS_B8
 SG_ TPD_Tester_Data_6 : 0|64@1+ (1,0) [0|1] ""  Gateway_B8

BO_ 774 TPD_Tester_07: 8 AFS_B8
 SG_ TPD_Tester_Data_7 : 0|64@1+ (1,0) [0|1] ""  Gateway_B8

BO_ 775 TPD_Tester_08: 8 AFS_B8
 SG_ TPD_Tester_Data_8 : 0|64@1+ (1,0) [0|1] ""  Gateway_B8

BO_ 517 TPS_Airbag: 7 Airbag_B8
 SG_ TPS_Airbag_Data : 0|56@1+ (1,0) [0|1] ""  Gateway_B8

BO_ 524 TPS_Daempfer: 7 Daempfer_B8
 SG_ TPS_Daempfer_Data : 0|56@1+ (1,0) [0|1] ""  Gateway_B8

BO_ 543 TPS_Gateway: 7 Gateway_B8
 SG_ TPS_Gateway_Data : 0|56@1+ (1,0) [0|1] ""  Airbag_B8

BO_ 514 TPS_Getriebe: 7 Getriebe_AL6000
 SG_ TPS_Getriebe_Data : 0|56@1+ (1,0) [0|1] ""  Gateway_B8

BO_ 518 TPS_LWR_AFS: 7 AFS_B8
 SG_ TPS_LWR_AFS_Data : 0|56@1+ (1,0) [0|1] ""  Gateway_B8

BO_ 513 TPS_Motor: 7 Motor_EDC17_003
 SG_ TPS_Motor_Data : 0|56@1+ (1,0) [0|1] ""  Gateway_B8

BO_ 533 TPS_MotorS: 7 Motor_Slave_B8
 SG_ TPS_MotorS_Data : 0|56@1+ (1,0) [0|1] ""  Gateway_B8

BO_ 512 TPS_Tester: 7 Gateway_B8
 SG_ TPS_Tester_Data : 0|56@1+ (1,0) [0|1] ""  AFS_B8,Airbag_B8,Daempfer_B8,Getriebe_AL6000,Getriebe_DL5001,Getriebe_VL3002,LWR_B8,Motor_EDC17_003,Motor_EDC17_004,Motor_MED17_B8,Motor_MED9_B8,Motor_SIMOS8_B8,Motor_Slave_B8

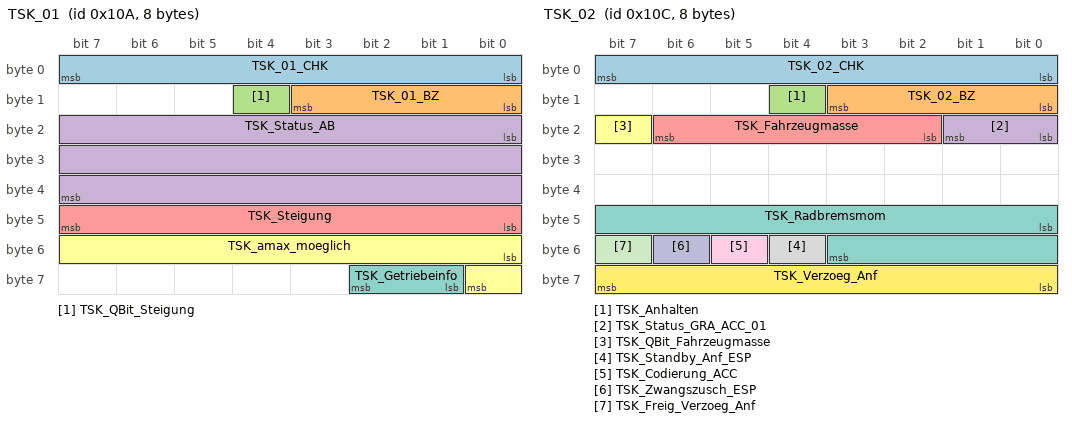
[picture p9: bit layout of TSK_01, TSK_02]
BO_ 266 TSK_01: 8 Motor_EDC17_003
 SG_ TSK_01_CHK : 0|8@1+ (1,0) [0|255] ""  Gateway_B8,Getriebe_AL6000,Getriebe_DL5001,Getriebe_VL3002
 SG_ TSK_01_BZ : 8|4@1+ (1,0) [0|15] ""  Gateway_B8,Getriebe_AL6000,Getriebe_DL5001,Getriebe_VL3002
 SG_ TSK_QBit_Steigung : 12|1@1+ (1,0) [0|1] ""  Gateway_B8,Getriebe_AL6000,Getriebe_DL5001,Getriebe_VL3002
 SG_ TSK_Status_AB : 16|24@1+ (1,0) [0|16777215] ""  Gateway_B8
 SG_ TSK_Steigung : 40|8@1+ (0.8,-101.6) [-101.6|101.6] "%"  Gateway_B8,Getriebe_AL6000,Getriebe_DL5001,Getriebe_VL3002
 SG_ TSK_amax_moeglich : 48|9@1+ (0.024,-2.016) [-2.01601|10.22399] "m/s2"  Gateway_B8
 SG_ TSK_Getriebeinfo : 57|2@1+ (1,0) [0|3] ""  Gateway_B8

BO_ 268 TSK_02: 8 Motor_EDC17_003
 SG_ TSK_02_CHK : 0|8@1+ (1,0) [0|255] ""  Daempfer_B8,Gateway_B8,Getriebe_AL6000,Getriebe_DL5001,Getriebe_VL3002
 SG_ TSK_02_BZ : 8|4@1+ (1,0) [0|15] ""  Daempfer_B8,Gateway_B8,Getriebe_AL6000,Getriebe_DL5001,Getriebe_VL3002
 SG_ TSK_Anhalten : 12|1@1+ (1,0) [0|1] ""  Gateway_B8
 SG_ TSK_Status_GRA_ACC_01 : 16|2@1+ (1,0) [0|3] ""  Gateway_B8
 SG_ TSK_Fahrzeugmasse : 18|5@1+ (200,500) [500|6500] "kg"  Gateway_B8,Getriebe_AL6000,Getriebe_DL5001,Getriebe_VL3002
 SG_ TSK_QBit_Fahrzeugmasse : 23|1@1+ (1,0) [0|1] ""  Gateway_B8,Getriebe_AL6000,Getriebe_DL5001,Getriebe_VL3002
 SG_ TSK_Radbremsmom : 40|12@1+ (8,0) [0|32752] "Nm"  Gateway_B8
 SG_ TSK_Standby_Anf_ESP : 52|1@1+ (1,0) [0|1] ""  Gateway_B8
 SG_ TSK_Codierung_ACC : 53|1@1+ (1,0) [0|1] ""  Gateway_B8
 SG_ TSK_Zwangszusch_ESP : 54|1@1+ (1,0) [0|1] ""  Gateway_B8
 SG_ TSK_Freig_Verzoeg_Anf : 55|1@1+ (1,0) [0|1] ""  Daempfer_B8,Gateway_B8,Getriebe_VL3002
 SG_ TSK_Verzoeg_Anf : 56|8@1+ (0.024,-3.984) [-3.984|2.112] "m/s2"  Daempfer_B8,Gateway_B8

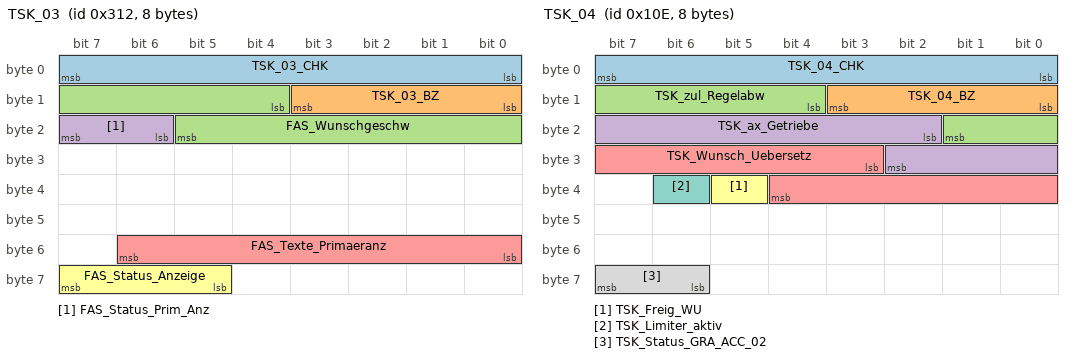
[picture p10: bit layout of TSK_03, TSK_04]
BO_ 786 TSK_03: 8 Motor_EDC17_003
 SG_ TSK_03_CHK : 0|8@1+ (1,0) [0|255] ""  Gateway_B8
 SG_ TSK_03_BZ : 8|4@1+ (1,0) [0|15] ""  Gateway_B8
 SG_ FAS_Wunschgeschw : 12|10@1+ (0.32,0) [0|326.72] "km/h"  Gateway_B8
 SG_ FAS_Status_Prim_Anz : 22|2@1+ (1,0) [0|3] ""  Gateway_B8
 SG_ FAS_Texte_Primaeranz : 48|7@1+ (1,0) [0|127] ""  Gateway_B8
 SG_ FAS_Status_Anzeige : 61|3@1+ (1,0) [0|7] ""  Gateway_B8

BO_ 270 TSK_04: 8 Motor_EDC17_D4
 SG_ TSK_04_CHK : 0|8@1+ (1,0) [0|255] ""  Getriebe_AL5000,Getriebe_DL5001,Getriebe_VL3002
 SG_ TSK_04_BZ : 8|4@1+ (1,0) [0|15] ""  Getriebe_AL5000,Getriebe_DL5001,Getriebe_VL3002
 SG_ TSK_zul_Regelabw : 12|6@1+ (0.024,0) [0|1.512] "Unit_MeterPerSeconSquar"  Getriebe_AL5000,Getriebe_DL5001,Getriebe_VL3002
 SG_ TSK_ax_Getriebe : 18|9@1+ (0.024,-2.016) [-2.016|10.224] "Unit_MeterPerSeconSquar"  Getriebe_AL5000,Getriebe_DL5001,Getriebe_VL3002
 SG_ TSK_Wunsch_Uebersetz : 27|10@1+ (0.0245,0) [0.0245|25.0635] ""  Getriebe_AL5000,Getriebe_DL5001,Getriebe_VL3002
 SG_ TSK_Freig_WU : 37|1@1+ (1,0) [0|1] ""  Getriebe_AL5000,Getriebe_DL5001,Getriebe_VL3002
 SG_ TSK_Limiter_aktiv : 38|1@1+ (1,0) [0|1] ""  Getriebe_AL5000,Getriebe_DL5001,Getriebe_VL3002
 SG_ TSK_Status_GRA_ACC_02 : 62|2@1+ (1,0) [0|3] ""  Getriebe_AL5000,Getriebe_DL5001,Getriebe_VL3002

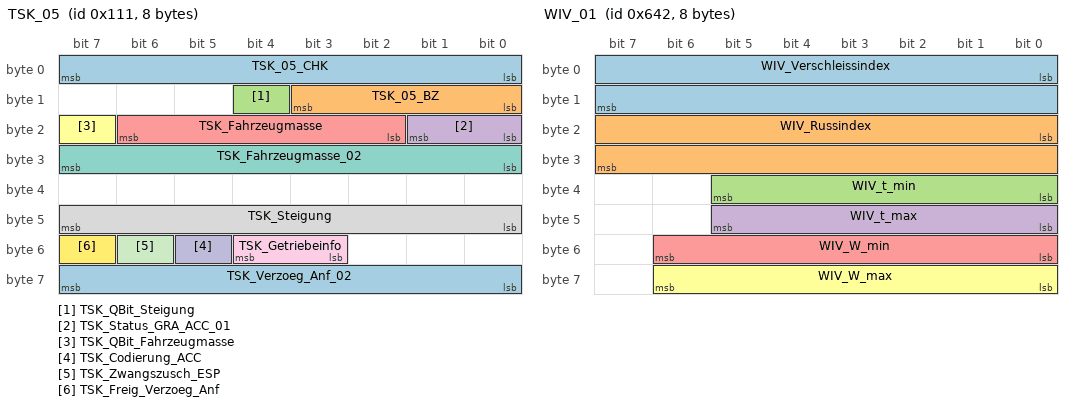
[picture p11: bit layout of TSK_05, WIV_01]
BO_ 273 TSK_05: 8 Motor_EDC17_D4
 SG_ TSK_05_CHK : 0|8@1+ (1,0) [0|255] ""  EPB_D4,Gateway_D4,Getriebe_AL5000,Getriebe_DL5001,Getriebe_VL3002
 SG_ TSK_05_BZ : 8|4@1+ (1,0) [0|15] ""  EPB_D4,Gateway_D4,Getriebe_AL5000,Getriebe_DL5001,Getriebe_VL3002
 SG_ TSK_QBit_Steigung : 12|1@1+ (1,0) [0|1] ""  Gateway_D4,Getriebe_AL5000,Getriebe_DL5001,Getriebe_VL3002
 SG_ TSK_Status_GRA_ACC_01 : 16|2@1+ (1,0) [0|3] ""  Gateway_D4
 SG_ TSK_Fahrzeugmasse : 18|5@1+ (200,500) [500|6500] "Unit_KiloGram"  Gateway_D4
 SG_ TSK_QBit_Fahrzeugmasse : 23|1@1+ (1,0) [0|1] ""  Gateway_D4,Getriebe_AL5000,Getriebe_DL5001,Getriebe_VL3002
 SG_ TSK_Fahrzeugmasse_02 : 24|8@1+ (32,0) [0|8128] "Unit_KiloGram"  Gateway_D4,Getriebe_AL5000,Getriebe_DL5001,Getriebe_VL3002
 SG_ TSK_Steigung : 40|8@1+ (0.8,-101.6) [-101.6|101.6] "Unit_PerCent"  Gateway_D4,Getriebe_AL5000,Getriebe_DL5001,Getriebe_VL3002
 SG_ TSK_Getriebeinfo : 51|2@1+ (1,0) [0|3] ""  Gateway_D4
 SG_ TSK_Codierung_ACC : 53|1@1+ (1,0) [0|1] ""  EPB_D4,Gateway_D4,Getriebe_AL5000,Getriebe_DL5001,Getriebe_VL3002
 SG_ TSK_Zwangszusch_ESP : 54|1@1+ (1,0) [0|1] ""  Gateway_D4
 SG_ TSK_Freig_Verzoeg_Anf : 55|1@1+ (1,0) [0|1] ""  Gateway_D4,Getriebe_AL5000,Getriebe_DL5001,Getriebe_VL3002
 SG_ TSK_Verzoeg_Anf_02 : 56|8@1+ (0.024,-3.984) [-3.984|2.136] "Unit_MeterPerSeconSquar"  Gateway_D4

BO_ 1716 VIN_01: 8 Gateway_B8
 SG_ VIN_01_MUX M : 0|2@1+ (1,0) [0|3] ""  Airbag_B8,Daempfer_B8
 SG_ KS_Geheimnis_1 m0 : 8|8@1+ (1,0) [0|255] ""  Airbag_B8
 SG_ VIN_4 m1 : 8|8@1+ (1,0) [0|255] ""  Airbag_B8,Daempfer_B8
 SG_ VIN_11 m2 : 8|8@1+ (1,0) [0|255] ""  Airbag_B8,Daempfer_B8
 SG_ KS_Geheimnis_2 m0 : 16|8@1+ (1,0) [0|255] ""  Airbag_B8
 SG_ VIN_5 m1 : 16|8@1+ (1,0) [0|255] ""  Airbag_B8,Daempfer_B8
 SG_ VIN_12 m2 : 16|8@1+ (1,0) [0|255] ""  Airbag_B8,Daempfer_B8
 SG_ KS_Geheimnis_3 m0 : 24|8@1+ (1,0) [0|255] ""  Airbag_B8
 SG_ VIN_6 m1 : 24|8@1+ (1,0) [0|255] ""  Airbag_B8,Daempfer_B8
 SG_ VIN_13 m2 : 24|8@1+ (1,0) [0|255] ""  Airbag_B8,Daempfer_B8
 SG_ KS_Geheimnis_4 m0 : 32|8@1+ (1,0) [0|255] ""  Airbag_B8
 SG_ VIN_7 m1 : 32|8@1+ (1,0) [0|255] ""  Airbag_B8,Daempfer_B8
 SG_ VIN_14 m2 : 32|8@1+ (1,0) [0|255] ""  Airbag_B8,Daempfer_B8
 SG_ VIN_1 m0 : 40|8@1+ (1,0) [0|255] ""  Airbag_B8,Daempfer_B8
 SG_ VIN_8 m1 : 40|8@1+ (1,0) [0|255] ""  Airbag_B8,Daempfer_B8
 SG_ VIN_15 m2 : 40|8@1+ (1,0) [0|255] ""  Airbag_B8,Daempfer_B8
 SG_ VIN_2 m0 : 48|8@1+ (1,0) [0|255] ""  Airbag_B8,Daempfer_B8
 SG_ VIN_9 m1 : 48|8@1+ (1,0) [0|255] ""  Airbag_B8,Daempfer_B8
 SG_ VIN_16 m2 : 48|8@1+ (1,0) [0|255] ""  Airbag_B8,Daempfer_B8
 SG_ VIN_3 m0 : 56|8@1+ (1,0) [0|255] ""  Airbag_B8,Daempfer_B8
 SG_ VIN_10 m1 : 56|8@1+ (1,0) [0|255] ""  Airbag_B8,Daempfer_B8
 SG_ VIN_17 m2 : 56|8@1+ (1,0) [0|255] ""  Airbag_B8,Daempfer_B8

BO_ 912 WBA_01: 4 Getriebe_AL6000
 SG_ WBA_Senderkennung M : 0|1@1+ (1,0) [0|1] ""  Gateway_B8
 SG_ WBA_Effizienzmodus : 5|1@1+ (1,0) [0|1] ""  Gateway_D4C7
 SG_ WBA_Getriebevariante : 1|4@1+ (1,0) [0|15] ""  Gateway_B8
 SG_ WBA_Fahrstufe m0 : 8|4@1+ (1,0) [0|15] ""  Gateway_B8
 SG_ WBA_Istgang m1 : 8|4@1+ (1,0) [0|15] ""  Gateway_B8
 SG_ WBA_eing_Gang m0 : 12|4@1+ (1,0) [0|15] ""  Gateway_B8
 SG_ WBA_Sollgang m1 : 12|4@1+ (1,0) [0|15] ""  Gateway_B8
 SG_ WBA_Blinken : 16|1@1+ (1,0) [0|1] ""  Gateway_B8
 SG_ WBA_Lampe_Shift_Lock m0 : 17|1@1+ (1,0) [0|1] ""  Gateway_B8
 SG_ WBA_Schaltempf_verfbar m1 : 18|1@1+ (1,0) [0|1] ""  Gateway_B8

BO_ 915 WBA_02: 8 Getriebe_AL551_951_D4_C7
 SG_ WBA_02_CHK : 0|8@1+ (1,0) [0|255] ""  Gateway_D4C7
 SG_ WBA_02_BZ : 8|4@1+ (1,0) [0|15] ""  Gateway_D4C7
 SG_ WBA_Senderkennung M : 12|1@1+ (1,0) [0|1] ""  Gateway_D4C7
 SG_ WBA_Lampe_Shift_Lock m0 : 13|1@1+ (1,0) [0|1] ""  Gateway_D4C7
 SG_ WBA_Schaltempf_verfbar m1 : 13|1@1+ (1,0) [0|1] ""  Gateway_D4C7
 SG_ WBA_Effizienzmodus : 14|1@1+ (1,0) [0|1] ""  Gateway_D4C7
 SG_ WBA_Blinken m0 : 16|1@1+ (1,0) [0|1] ""  Gateway_D4C7
 SG_ WBA_Getriebevariante m0 : 17|4@1+ (1,0) [0|15] ""  Gateway_D4C7
 SG_ WBA_GE_Warnung m0 : 21|3@1+ (1,0) [0|7] ""  Gateway_D4C7
 SG_ WBA_Fahrstufe m0 : 24|4@1+ (1,0) [0|15] ""  Gateway_D4C7
 SG_ WBA_Istgang m1 : 24|4@1+ (1,0) [0|15] ""  Gateway_D4C7
 SG_ WBA_eing_Gang m0 : 28|4@1+ (1,0) [0|15] ""  Gateway_D4C7
 SG_ WBA_Sollgang m1 : 28|4@1+ (1,0) [0|15] ""  Gateway_D4C7
 SG_ WBA_GE_Texte m0 : 32|3@1+ (1,0) [0|7] ""  Gateway_D4C7
 SG_ WBA_Schaltschema_Aktiv m0 : 35|1@1+ (1,0) [0|1] ""  Gateway_D4C7
 SG_ WH_Warnung m0 : 36|3@1+ (1,0) [0|7] ""  Gateway_D4C7

BO_ 1602 WIV_01: 8 Motor_EDC17_003
 SG_ WIV_Verschleissindex : 0|16@1+ (2E-008,0) [0|0] ""  Gateway_B8
 SG_ WIV_Russindex : 16|16@1+ (2E-008,0) [0|0] ""  Gateway_B8
 SG_ WIV_t_min : 32|6@1+ (1,0) [0|63] "month"  Gateway_B8
 SG_ WIV_t_max : 40|6@1+ (1,0) [0|63] "month"  Gateway_B8
 SG_ WIV_W_min : 48|7@1+ (1000,0) [0|127000] "km"  Gateway_B8
 SG_ WIV_W_max : 56|7@1+ (1000,0) [0|127000] "km"  Gateway_B8

BO_ 2617009149 XCP_Daempfer_CRO_01: 8 Vector__XXX
 SG_ XCP_Daempfer_CRO_01_Data : 0|64@1+ (1,0) [0|4294967295] ""  Daempfer_B8

BO_ 2617009150 XCP_Daempfer_DTO_01: 8 Daempfer_B8
 SG_ XCP_Daempfer_DTO_01_Data : 0|64@1+ (1,0) [0|4294967295] "" Vector__XXX

BO_TX_BU_ 1601 : Motor_EDC17_003,Motor_EDC17_004,Motor_MED17_B8,Motor_MED9_B8,Motor_SIMOS8_B8;
BO_TX_BU_ 1730 : Getriebe_AL6000,Getriebe_DL5001,Getriebe_VL3002;
BO_TX_BU_ 1729 : Motor_EDC17_003,Motor_EDC17_004,Motor_MED17_B8,Motor_MED9_B8,Motor_SIMOS8_B8;
BO_TX_BU_ 913 : Motor_EDC17_003,Motor_EDC17_004,Motor_MED17_B8,Motor_MED9_B8,Motor_SIMOS8_B8;
BO_TX_BU_ 768 : AFS_B8,Airbag_B8,Daempfer_B8,Getriebe_AL6000,Getriebe_DL5001,Getriebe_VL3002,LWR_B8,Motor_EDC17_003,Motor_EDC17_004,Motor_MED17_B8,Motor_MED9_B8,Motor_SIMOS8_B8,Motor_Slave_B8;
BO_TX_BU_ 769 : AFS_B8,Airbag_B8,Daempfer_B8,Getriebe_AL6000,Getriebe_DL5001,Getriebe_VL3002,LWR_B8,Motor_EDC17_003,Motor_EDC17_004,Motor_MED17_B8,Motor_MED9_B8,Motor_SIMOS8_B8,Motor_Slave_B8;
BO_TX_BU_ 770 : AFS_B8,Airbag_B8,Daempfer_B8,Getriebe_AL6000,Getriebe_DL5001,Getriebe_VL3002,LWR_B8,Motor_EDC17_003,Motor_EDC17_004,Motor_MED17_B8,Motor_MED9_B8,Motor_SIMOS8_B8,Motor_Slave_B8;
BO_TX_BU_ 771 : AFS_B8,Airbag_B8,Daempfer_B8,Getriebe_AL6000,Getriebe_DL5001,Getriebe_VL3002,LWR_B8,Motor_EDC17_003,Motor_EDC17_004,Motor_MED17_B8,Motor_MED9_B8,Motor_SIMOS8_B8,Motor_Slave_B8;
BO_TX_BU_ 772 : AFS_B8,Airbag_B8,Daempfer_B8,Getriebe_AL6000,Getriebe_DL5001,Getriebe_VL3002,LWR_B8,Motor_EDC17_003,Motor_EDC17_004,Motor_MED17_B8,Motor_MED9_B8,Motor_SIMOS8_B8,Motor_Slave_B8;
BO_TX_BU_ 773 : AFS_B8,Airbag_B8,Daempfer_B8,Getriebe_AL6000,Getriebe_DL5001,Getriebe_VL3002,LWR_B8,Motor_EDC17_003,Motor_EDC17_004,Motor_MED17_B8,Motor_MED9_B8,Motor_SIMOS8_B8,Motor_Slave_B8;
BO_TX_BU_ 774 : AFS_B8,Airbag_B8,Daempfer_B8,Getriebe_AL6000,Getriebe_DL5001,Getriebe_VL3002,LWR_B8,Motor_EDC17_003,Motor_EDC17_004,Motor_MED17_B8,Motor_MED9_B8,Motor_SIMOS8_B8,Motor_Slave_B8;
BO_TX_BU_ 775 : AFS_B8,Airbag_B8,Daempfer_B8,Getriebe_AL6000,Getriebe_DL5001,Getriebe_VL3002,LWR_B8,Motor_EDC17_003,Motor_EDC17_004,Motor_MED17_B8,Motor_MED9_B8,Motor_SIMOS8_B8,Motor_Slave_B8;
BO_TX_BU_ 514 : Getriebe_AL6000,Getriebe_DL5001,Getriebe_VL3002;
BO_TX_BU_ 518 : AFS_B8,LWR_B8;
BO_TX_BU_ 513 : Motor_EDC17_003,Motor_EDC17_004,Motor_MED17_B8,Motor_MED9_B8,Motor_SIMOS8_B8;
BO_TX_BU_ 266 : Motor_EDC17_003,Motor_EDC17_004,Motor_MED17_B8,Motor_MED9_B8,Motor_SIMOS8_B8;
BO_TX_BU_ 268 : Motor_EDC17_003,Motor_EDC17_004,Motor_MED17_B8,Motor_MED9_B8,Motor_SIMOS8_B8;
BO_TX_BU_ 786 : Motor_EDC17_003,Motor_EDC17_004,Motor_MED17_B8,Motor_MED9_B8,Motor_SIMOS8_B8;
BO_TX_BU_ 270 : Motor_EDC17_003,Motor_EDC17_004,Motor_MED17_B8,Motor_MED9_B8,Motor_SIMOS8_B8;
BO_TX_BU_ 912 : Getriebe_AL6000,Getriebe_DL5001,Getriebe_VL3002,Motor_EDC17_003,Motor_EDC17_004,Motor_MED17_B8,Motor_MED9_B8,Motor_SIMOS8_B8;
BO_TX_BU_ 1602 : Motor_EDC17_003,Motor_EDC17_004,Motor_MED17_B8,Motor_MED9_B8,Motor_SIMOS8_B8;
CM_ SG_ 1601 Motor_Code_01_CHK "Bildung der CHK:

XOR Byte2 XOR Byte 3 ... XOR Byte n  XOR CHK-Endwert  = CHK

Ab B8 ist CHK-Endwert abhängig vom CAN-ID: CHK-Endwert = MSB XOR LSB
MSB: High-Byte des Identifiers der CAN-Botschaft
LSB: Low-Byte des Identifiers der CAN-Botschaft

";
CM_ SG_ 1601 MO_Faktor_Momente "Dieses Bit schaltet den Wertebereich aller Momente vom Motor, Getriebe, TSK, ESP ... um! Die Momente besitzen somit einen variablen Wertebereich, weil sich durch den Faktor die Momente sowohl in Auflösung als auch Maximalwerten ändert.

Defaultwert ist ";
CM_ SG_ 1601 MO_Code "Motorcodierinformation für Getriebe. Überwachung auf Falschverbau.






";
CM_ SG_ 1601 MO_Getriebe_Code "Getriebecodierung des Motors

0x0 - 0x1 = tbd.
0x3 = tbd.
0x5 - 0x9 = tbd.
0xB - 0xE = tbd.
0x10 - 3F =tbd.";
CM_ SG_ 1601 MO_Kraftstoffart "0x5 - 0xF = tbd. ";
CM_ SG_ 1601 MO_Abgastyp "Bit 0:

0x0 = kein EOBD
0x1 = EOBD

Bit 1:

0x0 = kein OBD (US-Norm)
0x1 = OBD (US-Norm)

0x4 -0x3f=tdb.
";
CM_ SG_ 1728 NMH_GW_Start_1 "Zustand Start (<--Sleep)";
CM_ SG_ 1728 NMH_GW_Start_2 "Zustand Start (<--Prepare to Sleep)";
CM_ SG_ 1728 NMH_GW_Normal_Mode_1 "Zustand Normal Mode (<-- Start)";
CM_ SG_ 1728 NMH_GW_Normal_Mode_2 "Zustand Normal Mode (<-- Ready to Sleep)";
CM_ SG_ 1728 NMH_GW_Car_WakeUp "Car WakeUp optional";
CM_ SG_ 1728 NMH_GW_Per_WakeUp "Weckursache Peripherie
";
CM_ SG_ 1728 NMH_GW_Fkt_WakeUp "Weckursache Funktion (Softwarefunktion hat geweckt)
0 = wenn Peripheriewakeup
1 = BDM BEM
2 = Car Wakeup empfangen: Das Bussegment wurde aufgrund einer CarWakeup Anforderung geweckt. Das GW hat zuvor eine NWM-Botschaft auf einem Bus mit aktiviertem Car";
CM_ SG_ 1728 NMH_GW_NM_aktiv_Klemme_15 "Kl.15 EIN (Nachlaufursache, nicht 'Ready To Sleep')";
CM_ SG_ 1728 NMH_GW_NM_aktiv_Diagnose "Diagnose bei Kl 15 aus (Nachlaufursache, nicht 'Ready To Sleep')";
CM_ SG_ 1728 NMH_GW_NM_aktiv_Start "Mindestaktivzeit Zustand 'Start' (Nachlaufursache, nicht 'Ready To Sleep')";
CM_ SG_ 1728 NMH_GW_NM_aktiv_BDM "BDM-Kommunikation (Nachlaufursache, nicht 'Ready To Sleep')
";
CM_ SG_ 1728 NMH_GW_NM_aktiv_Warnblinken "Warnblinken (NM-Nachlaufursache, nicht 'Ready To Sleep')
";
CM_ SG_ 1728 NMH_GW_NM_aktiv_ESP "ESP aktiv (Wakeup/Sleep-Konzept)
(NM-Nachlaufursache, nicht 'Ready To Sleep')
";
CM_ SG_ 1728 NMH_GW_Abschaltstufe_3 "Abschaltstufe 3 (BEM)
(SG-interner Nachlauf vor CAN-Wakeup)
";
CM_ SG_ 1728 NMH_GW_SG_Fehlerdauer "Steuergeraetefehlerdauer (BEM)
(SG-interner Nachlauf vor CAN-Wakeup)
";
CM_ SG_ 1728 NMH_GW_STH_Wakeup "Standheizungswakeup (BEM)
(SG-interner Nachlauf vor CAN-Wakeup)";
CM_ SG_ 1728 NMH_GW_TimeOut_Fehler "Aktiver Timeout Fehlerspeichereintrag";
CM_ SG_ 1728 NMH_GW_CAN_Diag_deaktiv "CAN Bus bezogene Eigendiagnose deaktiviert (Überspannung, Unterspannung, Hochlaufphase, ...) ";
CM_ SG_ 1728 NMH_GW_KompSchutz "Funktionseinschränung aufgrund Komponentenschutz aktiv";
CM_ SG_ 1728 NMH_GW_Mute_Mode "Funktionseinschränung aufgrund Mute Mode aktiv, nur VW";
CM_ SG_ 1728 NMH_GW_Transport_Mode "Funktionseinschränung aufgrund Transport Mode aktiv";
CM_ SG_ 1728 NMH_GW_Abschaltstufe_aktiv "Funktionsabschaltung wegen Abschaltschaltstufe";
CM_ SG_ 1728 NMH_GW_Eindraht_Fehler "Erkennung Eindrahtfehler";
CM_ SG_ 1728 NMH_GW_ACAN "Antriebs-CAN aktiv (Wakeup/Sleep Konzept)
(NM-Nachlaufursache, nicht 'Ready To Sleep')
";
CM_ SG_ 1728 NMH_GW_KombiCAN "Kombi/Fahrwerks-CAN aktiv (Wakeup/Sleep Konzept)
(NM-Nachlaufursache, nicht 'Ready To Sleep')
";
CM_ SG_ 1728 NMH_GW_KomfortCAN "Komfort-CAN aktiv (Wakeup/Sleep Konzept)
(NM-Nachlaufursache, nicht 'Ready To Sleep')

";
CM_ SG_ 1728 NMH_GW_Infotainment "Infotainment aktiv (CAN oder MOST), Wakeup/Sleep-Konzept
(NM-Nachlaufursache, nicht 'Ready To Sleep')
";
CM_ SG_ 1728 NMH_GW_WakeUp_CAN_Bus "Weckendes Bussegment (Welcher CAN hat geweckt bzw. CarWakeup angefordert?)

";
CM_ SG_ 1730 NMH_GE_Start_1 "Zustand Start (<--Sleep)";
CM_ SG_ 1730 NMH_GE_Start_2 "Zustand Start (<--Prepare to Sleep)";
CM_ SG_ 1730 NMH_GE_Normal_Mode_1 "Zustand Normal Mode (<-- Start)";
CM_ SG_ 1730 NMH_GE_Normal_Mode_2 "Zustand Normal Mode (<-- Ready to Sleep)";
CM_ SG_ 1730 NMH_GE_Car_WakeUp "Car WakeUp optional";
CM_ SG_ 1730 NMH_GE_Per_WakeUp "Weckurasche Peripherie
";
CM_ SG_ 1730 NMH_GE_Fkt_WakeUp "Weckursache Funktion

";
CM_ SG_ 1730 NMH_GE_NM_aktiv_Klemme_15 "Klemme 15 ein (NM-Nachlaufursache, nicht 'Ready To Sleep')
";
CM_ SG_ 1730 NMH_GE_NM_aktiv_Diagnose "Diagnose bei Kl 15 aus (Nachlaufursache, nicht 'Ready To Sleep')";
CM_ SG_ 1730 NMH_GE_NM_aktiv_Start "Mindestaktivzeit Zustand 'Start' (Nachlaufursache, nicht 'Ready To Sleep')";
CM_ SG_ 1730 NMH_GE_kein_NL "kein lokaler / SG interner Nachlauf vor Wakeup";
CM_ SG_ 1730 NMH_GE_NL_Daten_EEPROM "EEPROM Datenspeicherung (lokaler / SG interner Nachlauf vor Wakeup)";
CM_ SG_ 1730 NMH_GE_NL_Drucksens "lokaler / SG interner Nachlauf: Wird gesetzt falls Druck auf einer der beiden Drucksensoren über applizierbarer Schwelle (bedeutet Motor läuft) vor CAN-Wakeup - nur VL Getriebe";
CM_ SG_ 1730 NMH_GE_NL_Abtrieb "lokaler / SG interner Nachlauf: Wird gesetzt falls Abtriebsdrehzahl größer applizierbarer Schwelle (bedeutet Fahrzeug bewegt sich) vor CAN-Wakeup - nicht DL Getriebe";
CM_ SG_ 1730 NMH_GE_NL_Waehlhebel "lokaler / SG interner Nachlauf: Wird gesetzt falls Wählhebel nicht in P oder N vor CAN-Wakeup - nur AL Getriebe";
CM_ SG_ 1730 NMH_GE_NL_Wegfahrsperre "lokaler / SG interner Nachlauf: Wird gesetzt falls Wegfahrsperre Nachlauf vor CAN-Wakeup aktiv - nur AL Getriebe";
CM_ SG_ 1730 NMH_GE_TimeOut_Fehler "Aktiver Timeout Fehlerspeichereintrag  ";
CM_ SG_ 1730 NMH_GE_CAN_Diag_deaktiv "CAN Bus bezogene Eigendiagnose deaktiviert (Überspannung, Unterspannung, Hochlaufphase, ...) ";
CM_ SG_ 1730 NMH_GE_KompSchutz "Funktionseinschränung aufgrund Komponentenschutz aktiv";
CM_ SG_ 1730 NMH_GE_Mute_Mode "Funktionseinschränung aufgrund Mute Mode aktiv, nur VW";
CM_ SG_ 1730 NMH_GE_Transport_Mode "Funktionseinschränung aufgrund Transport Mode aktiv";
CM_ SG_ 1730 NMH_GE_Abschaltstufe_aktiv "Funktionsabschaltung wegen Abschaltschaltstufe";
CM_ SG_ 1730 NMH_GE_Eindraht_Fehler "Erkennung Eindrahtfehler";
CM_ SG_ 1729 NMH_MO_Start_1 "Zustand Start (<--Sleep)";
CM_ SG_ 1729 NMH_MO_Start_2 "Zustand Start (<--Prepare to Sleep)";
CM_ SG_ 1729 NMH_MO_Normal_Mode_1 "Zustand Normal Mode (<-- Start)";
CM_ SG_ 1729 NMH_MO_Normal_Mode_2 "Zustand Normal Mode (<-- Ready to Sleep)";
CM_ SG_ 1729 NMH_MO_Car_WakeUp "Car WakeUp optional";
CM_ SG_ 1729 NMH_MO_Per_WakeUp "Weckursache Peripherie
";
CM_ SG_ 1729 NMH_MO_Fkt_WakeUp "Weckursache Funktion
";
CM_ SG_ 1729 NMH_MO_NM_aktiv_Klemme_15 "Klemme 15 ein (NM-Nachlaufursache, nicht 'Ready To Sleep')";
CM_ SG_ 1729 NMH_MO_NM_aktiv_Diagnose "Diagnose bei Kl 15 aus (NM-Nachlaufursache, nicht 'Ready To Sleep')
";
CM_ SG_ 1729 NMH_MO_NM_aktiv_Start "Mindestaktivzeit Zustand 'Start' (NM-Nachlaufursache, nicht 'Ready To Sleep')";
CM_ SG_ 1729 NMH_MO_NM_aktiv_EKP_Vorlauf "EKP-Vorlauf (z. Zt. nicht bei Diesel)
(NM-Nachlaufursache, nicht 'Ready To Sleep')
";
CM_ SG_ 1729 NMH_MO_NM_aktiv_STH_Betrieb "STH-Betrieb (NM-Nachlaufursache, nicht 'Ready To Sleep')
";
CM_ SG_ 1729 NMH_MO_NM_aktiv_HV_Abschaltung "Hybrid-Manager deaktiviert alle Hochvolt-Verbraucher für stromloses Öffnen der Batterieschütze
(Nachlaufursache, nicht 'Ready To Sleep')";
CM_ SG_ 1729 NMH_MO_kein_NL "kein lokaler / SG interner Nachlauf vor Wakeup";
CM_ SG_ 1729 NMH_MO_NL_Kuehlerluefter "Kühlerlüfter Steuerung / Zusatzwasserpumpe (lokaler / SG interner Nachlauf vor Wakeup)";
CM_ SG_ 1729 NMH_MO_NL_Diagnose "Diagnosefunktionen (lokaler / SG interner Nachlauf vor Wakeup)";
CM_ SG_ 1729 NMH_MO_NL_WFS "Wegfahrsperre (lokaler / SG interner Nachlauf vor Wakeup)";
CM_ SG_ 1729 NMH_MO_NL_EEPROM "EEPROM Zugriffe RAM/ROM Tests (lokaler / SG interner Nachlauf vor Wakeup)";
CM_ SG_ 1729 NMH_MO_NL_Sonstige "Sonstige lokale / SG interne Nachläufe vor Wakeup";
CM_ SG_ 1729 NMH_MO_TimeOut_Fehler "Aktiver Timeout Fehlerspeichereintrag  ";
CM_ SG_ 1729 NMH_MO_CAN_Diag_deaktiv "CAN Bus bezogene Eigendiagnose deaktiviert (Überspannung, Unterspannung, Hochlaufphase, ...) ";
CM_ SG_ 1729 NMH_MO_KompSchutz "Funktionseinschränung aufgrund Komponentenschutz aktiv";
CM_ SG_ 1729 NMH_MO_Mute_Mode "Funktionseinschränung aufgrund Mute Mode aktiv, nur VW";
CM_ SG_ 1729 NMH_MO_Transport_Mode "1 = Funktionseinschränung aufgrund Transport Mode aktiv";
CM_ SG_ 1729 NMH_MO_Abschaltstufe_aktiv "Funktionsabschaltung wegen Abschaltschaltstufe";
CM_ SG_ 1729 NMH_MO_Eindraht_Fehler "Erkennung Eindrahtfehler";
CM_ SG_ 913 OBD_Calc_Load_Val "Calculated Load Value

Übertragung von Meßgrößen an das Getriebesteuergerät für Freeze Frame Abspeicherung bei Getriebefehlern

PID $04 Calculated Load Value; 0 .. 100% mit 100/255 % per bit
";
CM_ SG_ 913 OBD_Eng_Cool_Temp "Engine Coolant Temperature

Übertragung von Meßgrößen an das Getriebesteuergerät für Freeze Frame Abspeicherung bei Getriebefehlern

PID $05 Engine Coolant Temperature; -40 .. +215°C mit 1°C/bit und 40°C Offset";
CM_ SG_ 913 OBD_Abs_Throttle_Pos "Absolute Throttle Position

Übertragung von Meßgrößen an das Getriebesteuergerät für Freeze Frame Abspeicherung bei Getriebefehlern

PID $11 Absolute Throttle Position; 0 .. 100% mit 100/255 %/bit";
CM_ SG_ 913 OBD_Abs_Load_Val "Absolute Load Value

Übertragung von Meßgrößen an das Getriebesteuergerät für Freeze Frame Abspeicherung bei Getriebefehlern

PID $43 Absolute Load Value; 0 .. 25700%  mit 100/255 %/bit";
CM_ SG_ 913 OBD_Abs_Pedal_Pos "Absolute Pedal Position

Übertragung von Meßgrößen an das Getriebesteuergerät für Freeze Frame Abspeicherung bei Getriebefehlern

PID $49 Accelerator Pedal Position D; 0 .. 100% mit 100/255 %/bit";
CM_ SG_ 913 OBD_Warm_Up_Cycle "Mit dem Warm-Up-Cycle wird der zentrale Verlernzähler vom Gateway inkrementiert";
CM_ SG_ 913 OBD_Normed_Trip "Gesetzlich definierte 'Normed Condition' erfüllt, 'General Denominator' darf erhöht werden";
CM_ SG_ 1630 OBD_TG_F_Status_1 "Fehlerstatus Tankfüllstandsgeber (OBD relevanter Sensor für Tankleckdiagnose)";
CM_ SG_ 1630 OBD_TG_F_Status_2 "Fehlerstatus Tankfüllstandsgeber (OBD relevanter Sensor für Tankleckdiagnose)

0x00 = kein Fehler / Init / nicht verbaut
0x01 = KS-
0x02 = KS+ (B8: nicht bedient)
0x03 = OC (Leitungsunterbrechung) (B8: nicht bedient)
0x04 = OOR+ (out of range high) ";
CM_ SG_ 1630 OBD_TG_F_Status_3 "Fehlerstatus Tankfüllstandsgeber (OBD relevanter Sensor für Tankleckdiagnose)

0x00 = kein Fehler / Init / nicht verbaut
0x01 = KS-
0x02 = KS+ (B8: nicht bedient)
0x03 = OC (Leitungsunterbrechung) (B8: nicht bedient)
0x04 = OOR+ (out of range high) ";
CM_ SG_ 1630 OBD_TG_F_Status_4 "Fehlerstatus Tankfüllstandsgeber (OBD relevanter Sensor für Tankleckdiagnose)

0x00 = kein Fehler / Init / nicht verbaut
0x01 = KS-
0x02 = KS+ (B8: nicht bedient)
0x03 = OC (Leitungsunterbrechung) (B8: nicht bedient)
0x04 = OOR+ (out of range high) ";
CM_ SG_ 1630 OBD_TG_Sens_Rohwert_1 "Rohwert des Tankgebers, nur gefiltert (gleitender Mittelwert), Ausgabe im 500ms-Raster";
CM_ SG_ 1630 OBD_TG_Sens_Rohwert_2 "Rohwert des Tankgebers, nur gefiltert (gleitender Mittelwert), Ausgabe im 500ms-Raster";
CM_ SG_ 1630 OBD_TG_Sens_Rohwert_3 "Rohwert des Tankgebers, nur gefiltert (gleitender Mittelwert), Ausgabe im 500ms-Raster";
CM_ SG_ 1630 OBD_TG_Sens_Rohwert_4 "Rohwert des Tankgebers, nur gefiltert (gleitender Mittelwert), Ausgabe im 500ms-Raster";
CM_ SG_ 133 SCU_01_CHK "Bildung der CHK:

XOR Byte2 XOR Byte 3 ... XOR Byte n  XOR CHK-Endwert  = CHK

Ab B8 ist CHK-Endwert abhängig vom CAN-ID: CHK-Endwert = MSB XOR LSB
MSB: High-Byte des Identifiers der CAN-Botschaft
LSB: Low-Byte des Identifiers der CAN-Botschaft";
CM_ SG_ 133 SCU_Ue_Winkel_ADS "Gesamt-Überlagerungs-/ Motorwinkel bezogen auf Ritzelebene";
CM_ SG_ 133 SCU_VZ_Ue_Winkel_ADS "Vorzeichen des Gesamt-Überlagerungswinkels ";
CM_ SG_ 133 SCU_Soll_Ue_Winkel "Teil-Sollwinkel der SCU-Funktionen (variable Lenkübersetzung) bezogen auf das Ritzel";
CM_ SG_ 133 SCU_max_Gradient "Von der Fahrgeschwindigkeit abhängige maximaler Zustellgradient der ESP-Stabilisierungsfunktionen bezogen auf Ritzelebene.
";
CM_ SG_ 133 SCU_VZ_Soll_Ue_Winkel "Vorzeichen des SCU-Teil-Sollwinkels";
CM_ SG_ 133 SCU_Status "Status der SCU

0x5 - 0xF = tbd.
";
CM_ SG_ 133 SCU_01_CRC "CRC8 nach Polynom C2";
CM_ SG_ 1313 STH_LED "Funktionslampe";
CM_ SG_ 1313 STH_EKP_Anst "STH sendet die Anforderung zur Ansteuerung der EKP an den Motor, um Kraftstoffbehälter der STH zu befüllen.";
CM_ SG_ 1313 STH_Ventiloeffnungszeit "Die Standheizung sendet an den Motor die Information darüber wie lange das Magnetventil die Wasserkreisläufe von 'klein' aus 'gross' geschaltet hat. ";
CM_ SG_ 1313 STH_Waermeeintrag "Signal enthält die Brenndauer in 1min-Schritten, über welche die Standheizung gelaufen ist";
CM_ SG_ 1313 STH_KVS "Kraftstoffverbrauch";
CM_ SG_ 1313 STH_Fehlerstatus "0x5 - 0x7 = nicht definiert";
CM_ SG_ 1313 STH_Heizleistung "Heizleistung in %";
CM_ SG_ 1313 STH_Motorvorwaermung "Info an der Motor, dass der Aufheizvorgang mit Motorvorwärmung erfolgt ist";
CM_ SG_ 1313 STH_war_aktiv "Bit beeinhaltet die Info, dass die Standheizung während der letzten halbe Stunde aktiv war.";
CM_ SG_ 1413 SI_Int_CAN_gespiegelt "Nutzdaten eines internen CAN-Netzwerks (z. B. Antrieb) werden  auf den Diagnose-CAN gespiegelt (Mirror-Mode aktiviert)";
CM_ SG_ 1413 SI_CAN_Antrieb_Sleep "CAN-Antrieb-Netzwerk (ACAN) schläft (Status des NM)
";
CM_ SG_ 266 TSK_01_CHK "Bildung der CHK:

XOR Byte2 XOR Byte 3 ... XOR Byte n  XOR CHK-Endwert  = CHK

Ab B8 ist CHK-Endwert abhängig vom CAN-ID: CHK-Endwert = MSB XOR LSB
MSB: High-Byte des Identifiers der CAN-Botschaft
LSB: Low-Byte des Identifiers der CAN-Botschaft";
CM_ SG_ 266 TSK_Status_AB "Aktueller Betriebs-/Fehlerstatus des Antriebsstrangs bzw. der Bremse wird über eine Bitleiste dem ACC mitgeteilt. Abhängig vom gesetzten Bit in diesem Signal wird im ACC bestimmte Reaktion bzgl. Abschaltung, FSP-Eintrag, Kombi-Anzeige und Deaktivierung vo";
CM_ SG_ 266 TSK_Steigung "Steigung in % Berg. Das Signal dient der Anpassung der Sollbeschleunigung vom ACC

Positive Werte > bergauf;
Negative Werte < bergab

Fehler: Die Steigung aufgrund eines Fehlers (mit KD-Fehlereintrag) nicht mehr berechnet werden";
CM_ SG_ 266 TSK_amax_moeglich "Fzg mit Stufenautomat: Maximale mögliche Beschleunigung bei der jetzigen Übersetzung (Übertragungsfunktion), bezogen auf Begrenzungsmoment, Fahrzeugmasse, Fahrwiderstandsindex und Motor Stressfaktor

Fzg mit stufenlosem Getriebe: Maximale mögliche Besch";
CM_ SG_ 268 TSK_02_CHK "Bildung der CHK:

XOR Byte2 XOR Byte 3 ... XOR Byte n  XOR CHK-Endwert  = CHK

Ab B8 ist CHK-Endwert abhängig vom CAN-ID: CHK-Endwert = MSB XOR LSB
MSB: High-Byte des Identifiers der CAN-Botschaft
LSB: Low-Byte des Identifiers der CAN-Botschaft";
CM_ SG_ 268 TSK_Anhalten "Im Falle eines gesetzten Bits wird vom TSK ein Anhalten bis in den Stand gewünscht. Das Bit wird vom ACC nur unterhalb einer applizierbaren Geschwindigkeitsschwelle gesetzt, und vom TSK weitergeleitet. Notwendig für die ACCplus-Funktionalität. Vorhalt für";
CM_ SG_ 268 TSK_Status_GRA_ACC_01 "Die Zustände 0x1 und 0x2 werden vom Motor auch bei ACC gesetzt, wegen Umsetzung des Triebsstrangkoordinators im Motor. ";
CM_ SG_ 268 TSK_Fahrzeugmasse "Fahrzeugmasse in kg. Das Signal dient der Anpassung der Sollbeschleunigung vom ACC

Init (entspricht phys. 500kg)
";
CM_ SG_ 268 TSK_Radbremsmom "Bei der Schnittstelle vom TSK zum ESP soll in Folgeprojekten des B8 und insbesondere bei VW-Projekten die Ansteuerung der Bremse nicht über Sollbeschleunigung sondern Bremsmoment erfolgen.  Es handelt sich genauer um das Summenradbremsmoment, welches die ";
CM_ SG_ 268 TSK_Standby_Anf_ESP "Mit diesem Bit wird das aktive Bremssystem auf eine anstehende TSK-Verzögerungsanforderung vorbereitet (Überfahren Leerweg, Anlegen Bremsbeläge)

Vorhalt für VW, keine Verwendung bei AUDI";
CM_ SG_ 268 TSK_Codierung_ACC "Information über den plausibilisierten Codierungszustand des Triebstrangskoordinators auf ACC.
Nutzung im ESP: Aktivierung der Timeout Überwachung auf ACC_01-Botschaft und Überwachung der zusätzlichen Drucksensoren bei gesetztem Bit.";
CM_ SG_ 268 TSK_Zwangszusch_ESP "Mit diesem Bit wird das ESP/ASR zwangsweise aktiviert. Bei gesetztem Bit ist ein ausgetastetes ESP (oder ASR) wieder aktiviert bzw. wird die Austastung verhindert.";
CM_ SG_ 268 TSK_Freig_Verzoeg_Anf "Freigabe der Verzögerungsanforderung der ACC oder ggf. GRA+ Funktion für ECD Regelung im ESP";
CM_ SG_ 268 TSK_Verzoeg_Anf "Verzögerungsanforderung der ACC oder ggf. GRA+ Funktion für ECD Regelung im ESP";
CM_ SG_ 786 TSK_03_CHK "Bildung der CHK:

XOR Byte2 XOR Byte 3 ... XOR Byte n  XOR CHK-Endwert  = CHK

Ab B8 ist CHK-Endwert abhängig vom CAN-ID: CHK-Endwert = MSB XOR LSB
MSB: High-Byte des Identifiers der CAN-Botschaft
LSB: Low-Byte des Identifiers der CAN-Botschaft";
CM_ SG_ 786 FAS_Wunschgeschw "Zur Anzeige der Wunschgeschwindigkeit im Kombiinstrument";
CM_ SG_ 786 FAS_Status_Prim_Anz "Ansteuerung einer primären Statusanzeige für ACC/GRA in verschiedenen Farben";
CM_ SG_ 786 FAS_Texte_Primaeranz "Weitere Textdefinitionen im DBC-File!

0x43-7F = tbd.";
CM_ SG_ 786 FAS_Status_Anzeige "Analog zum Status nur zur Defintion von Anzeige im Kombi. Hinweis: Wird für die spez. VW-Anzeige (überlappende Anzeigebereiche) verwendet. Vom AUDI-ACC im Rahmen der Modulstrategie zu bedienen.
";
CM_ SG_ 270 TSK_04_CHK "Bildung der CHK:

XOR Byte2 XOR Byte 3 ... XOR Byte n  XOR CHK-Endwert  = CHK

Ab B8 ist CHK-Endwert abhängig vom CAN-ID: CHK-Endwert = MSB XOR LSB
MSB: High-Byte des Identifiers der CAN-Botschaft
LSB: Low-Byte des Identifiers der CAN-Botschaft";
CM_ SG_ 270 TSK_zul_Regelabw "Anforderung der zulässigen Regelabweichung vom Triebstrangkoordinator. Zulässiger Betrag der Abweichung zwischen angeforderter 'TSK_Sollbeschleunigung_Getriebe' und umzusetzender Sollbeschleunigung  im Getriebe. Im TSK wird, abhängig vom Arbeitspunkt die ";
CM_ SG_ 270 TSK_ax_Getriebe "Beschleunigungsanforderung des Beschleunigungsreglers (u. a. für ACC, GRA, Speed Limiter). Das Signal wird vom Getriebe benutzt, um die von GRA/ACC geforderte Sollbeschleunigung in dem verbrauchsgünstigsten Gang einzustellen.";
CM_ SG_ 270 TSK_Wunsch_Uebersetz "Bei ACC/GRA Betrieb bergab teilt der TSK dem Getriebe mit, dass eine Drehzahlerhöhung erwünscht ist, um mehr Schleppmoment und damit verbunden die nötige Verzögerung zu erzeugen, um die Geschwindigkeit konstant zu halten.

Nutzung im VL: das Getriebe v";
CM_ SG_ 270 TSK_Freig_WU "Freigabe des TSK_Übersetzungswunsches bei ACC/GRA Betrieb bergab für die Verstellung nach kurz bzw. Rückschaltung im Getriebe.";
CM_ SG_ 270 TSK_Limiter_aktiv "Information, ob der Höchstgeschwindigkeitsbegrenzer aktiv ist. Beim gesetzten Bit kann das Getriebe hochschalten, unabhängig vom Fahrpedal";
CM_ SG_ 270 TSK_Status_GRA_ACC_02 "Signal redundant zu 'TSK_Status_GRA_ACC_01' in TSK_02, um für das Getriebe die einzulesenden Botschaften zu definieren.

Die Zustände 0x1 und 0x2 werden vom Motor auch bei ACC gesetzt, wegen Umsetzung des Triebsstrangkoordinators im Motor. ";
CM_ SG_ 1716 VIN_01_MUX "Achtung:
Die Botschaft ist nicht linear gemultiplext!!!
Sondern 0,1,0,2,0, usw.";
CM_ SG_ 912 WBA_Senderkennung "Die Botschaft WBA_01 wird vom Automatgetriebe gesendet, bei Handschaltern alternativ vom Motor. Das Getriebe stellt damit die Wählbereichsanzeige dar, der Motor beim Handschalter die Hochschaltaufforderung für den Fahrer im Kombi. Zur Unterscheidung des S";
CM_ SG_ 912 WBA_Getriebevariante "Verwendete Getriebe-Variante im Fahrzeug, Kombi stellt entsprechende WBA dar (bspw. PRNDS). Nur falls WBA_Senderkennung = 00 (GSG).
";
CM_ SG_ 912 WBA_Fahrstufe "Bei Automatgetrieben wird in diesem Signal die aktuelle Fahrstufe (=Wählhebelposition) ausgegeben. Nur falls WBA_Senderkennung = 00 (GSG):

Im Automatik-Betrieb:

0x0 = Zwischenstellung, keine Position  (Normaldarstellung aller Fahrstufen)
0x1 = Getr";
CM_ SG_ 912 WBA_Istgang "Wenn Motor die WBA-Botschaft sendet wird in diesem Signal der aktuelle Gang ausgegeben (= Istgang des Schaltgetriebes). Nur falls WBA_Senderkennung = 01 (MSG).

0x7 - 0xF = tbd.

Anzeige im Kombi:
Sollgang == Istgang         ==> Anzeige Istgang
Soll";
CM_ SG_ 912 WBA_eing_Gang "Das Automatgetriebe gibt den aktuell eingelegten Gang aus. Nur falls WBA_Senderkennung = 00 (GSG)

0xB - 0xF = tbd.

Weiter sind Empfängerseitig mit nächstem SW-Release zu bedienen:
0x9 = 8.Gang
0xA = 9.Gang
Der Sender stellt noch nicht um.
Nach I";
CM_ SG_ 912 WBA_Sollgang "Motor sendet den Sollgang in den der Fahrer schalten soll. Wird im Kombi als Hochschaltempfehlung hervorgehoben. Nur falls WBA_Senderkennung = 01 (MSG)

0x7 - 0xF = tbd.

Anzeige im Kombi:
Sollgang == Istgang          ==> Anzeige Istgang
Sollgang !=";
CM_ SG_ 912 WBA_Blinken "Dieses Bit steuert die Fehlerlampe an oder wird zum Blinken der WBA-Anzeige genutzt - nur falls WBA_Senderkennung = 00 (GSG)
";
CM_ SG_ 912 WBA_Lampe_Shift_Lock "Im Kombi wird Anzeige im Mitteldisplay geschaltet: 'Zum Einlegen einer Fahrstufe bitte Bremse betätigen' - nur falls WBA_Senderkennung = 00 (GSG)

";
CM_ SG_ 912 WBA_Schaltempf_verfbar "Info, ob Schaltempfehlung im Fzg. verfügbar. Statischer Wert, ändert sich für ein Fzg nicht - nur falls WBA_Senderkennung = 01 (MSG)";
CM_ SG_ 1602 WIV_Verschleissindex "Bei Otto Verbrauch, bei Diesel Verschleiss";
CM_ SG_ 1602 WIV_Russindex "Nur für Diesel, Rußwert, bei Otto Wert = 0";
CM_ SG_ 1602 WIV_t_min "Minimales Wartungsintervall für WIV in Monaten";
CM_ SG_ 1602 WIV_t_max "Maximales Wartungsintervall für WIV in Monaten";
CM_ SG_ 1602 WIV_W_min "Minimales Wartungsintervall für WIV in km";
CM_ SG_ 1602 WIV_W_max "Maximales Wartungsintervall für WIV in km";
BA_DEF_ BO_  "GenMsgAutoGenDsp" ENUM  "No","Yes";
BA_DEF_ BO_  "GenMsgAutoGenSnd" ENUM  "No","Yes";
BA_DEF_ BO_  "GenMsgCycleTime" INT 0 65535;
BA_DEF_ BO_  "GenMsgCycleTimeFast" INT 0 65535;
BA_DEF_ BO_  "GenMsgDelayTime" INT 0 100000;
BA_DEF_ BO_  "GenMsgILSupport" ENUM  "No","Yes";
BA_DEF_ BO_  "GenMsgNrOfRepetition" INT 0 100;
BA_DEF_ BO_  "GenMsgSendType" ENUM  "cyclicX","spontanX","cyclicIfActiveX","spontanWithDelay","cyclicAndSpontanX","cyclicAndSpontanWithDelay","spontanWithRepetition","cyclicIfActiveAndSpontanWD","cyclicIfActiveFast","cyclicWithRepeatOnDemand";
BA_DEF_ BO_  "GenMsgStartDelayTime" INT 0 100000;
BA_DEF_ BO_  "NmMessage" ENUM  "No","Yes";
BA_DEF_ BO_  "NmhMessage" ENUM  "No","Yes";
BA_DEF_ BO_  "NWM-Botschaft" ENUM  "No","Yes";
BA_DEF_ BO_  "VAGTP20_API" HEX 0 255;
BA_DEF_ BO_  "VAGTP20_DynConnection" ENUM  "No","Yes";
BA_DEF_ BO_  "VAGTP20_DynSetup" ENUM  "No","Yes";
BA_DEF_ BO_  "VAGTP20_StatConnection" ENUM  "No","Yes";
BA_DEF_ BO_  "Timeoutzeit" INT 0 1000000;
BA_DEF_ BO_  "akt_Dateninh_NM_Betr" ENUM  "No","Yes";
BA_DEF_ SG_  "GenSigAltSetting" STRING ;
BA_DEF_ SG_  "GenSigAssignSetting" STRING ;
BA_DEF_ SG_  "GenSigAutoGenDsp" ENUM  "No","Yes";
BA_DEF_ SG_  "GenSigAutoGenSnd" ENUM  "No","Yes";
BA_DEF_ SG_  "GenSigConditionalSend" STRING ;
BA_DEF_ SG_  "GenSigEnvVarType" ENUM  "int","float","undef";
BA_DEF_ SG_  "GenSigEVName" STRING ;
BA_DEF_ SG_  "GenSigInactiveValue" INT -2147483648 2147483647;
BA_DEF_ SG_  "GenSigPostIfSetting" STRING ;
BA_DEF_ SG_  "GenSigPostSetting" STRING ;
BA_DEF_ SG_  "GenSigPreIfSetting" STRING ;
BA_DEF_ SG_  "GenSigPreSetting" STRING ;
BA_DEF_ SG_  "GenSigSendType" ENUM  "Cyclic","OnWrite","OnWriteWithRepetition","OnChange","OnChangeWithRepetition","IfActive","IfActiveWithRepetition","NoSigSendType";
BA_DEF_ SG_  "GenSigStartValue" INT -2147483648 2147483647;
BA_DEF_ SG_  "NWM-WakeupAllowed" ENUM  "No","Yes";
BA_DEF_ SG_  "NMH-WakeupAllowed" ENUM  "No","Yes";
BA_DEF_ SG_  "GenSigTimeoutMsg_Motor_EDC17_003" HEX 0 2047;
BA_DEF_ SG_  "GenSigTimeoutMsg_Motor_EDC17_004" HEX 0 2047;
BA_DEF_ SG_  "GenSigTimeoutMsg_Motor_MED17_B8" HEX 0 2047;
BA_DEF_ SG_  "GenSigTimeoutMsg_Motor_MED9_B8" HEX 0 2047;
BA_DEF_ SG_  "GenSigTimeoutMsg_Motor_SIMOS8_B8" HEX 0 2047;
BA_DEF_ SG_  "GenSigTimeoutMsg_Daempfer_B8" HEX 0 2047;
BA_DEF_ SG_  "GenSigTimeoutMsg_Gateway_B8" HEX 0 2047;
BA_DEF_ SG_  "GenSigTimeoutMsg_Getriebe_AL6000" HEX 0 2047;
BA_DEF_ SG_  "GenSigTimeoutMsg_Getriebe_DL5001" HEX 0 2047;
BA_DEF_ SG_  "GenSigTimeoutMsg_Getriebe_VL3002" HEX 0 2047;
BA_DEF_ SG_  "GenSigTimeoutMsg_AFS_B8" HEX 0 2047;
BA_DEF_ SG_  "GenSigTimeoutMsg_Motor_Slave_B8" HEX 0 2047;
BA_DEF_ SG_  "GenSigTimeoutMsg_Airbag_B8" HEX 0 2047;
BA_DEF_ SG_  "GenSigTimeoutMsg_LWR_B8" HEX 0 2047;
BA_DEF_ SG_  "GenSigFuncType" ENUM  "NoFunction","MsgCounter","CRC-8","XOR","XOR-2","DatedBit","SW-Kl15","CHK","Constant","Protocol";
BA_DEF_ SG_  "GenSigSwitchedByIgnition" ENUM  "No","Yes";
BA_DEF_ SG_  "Fehlerwert" HEX 0 2147483647;
BA_DEF_ SG_  "GenSigMissingSourceValue" HEX 0 2147483647;
BA_DEF_ SG_  "SystemSignalLongSymbol" STRING ;
BA_DEF_DEF_  "GenMsgAutoGenDsp" "Yes";
BA_DEF_DEF_  "GenMsgAutoGenSnd" "Yes";
BA_DEF_DEF_  "GenMsgCycleTime" 0;
BA_DEF_DEF_  "GenMsgCycleTimeFast" 0;
BA_DEF_DEF_  "GenMsgDelayTime" 0;
BA_DEF_DEF_  "GenMsgILSupport" "";
BA_DEF_DEF_  "GenMsgNrOfRepetition" 0;
BA_DEF_DEF_  "GenMsgSendType" "cyclicX";
BA_DEF_DEF_  "GenMsgStartDelayTime" 0;
BA_DEF_DEF_  "NmMessage" "No";
BA_DEF_DEF_  "NmhMessage" "No";
BA_DEF_DEF_  "NWM-Botschaft" "No";
BA_DEF_DEF_  "VAGTP20_API" 0;
BA_DEF_DEF_  "VAGTP20_DynConnection" "No";
BA_DEF_DEF_  "VAGTP20_DynSetup" "No";
BA_DEF_DEF_  "VAGTP20_StatConnection" "No";
BA_DEF_DEF_  "Timeoutzeit" 0;
BA_DEF_DEF_  "akt_Dateninh_NM_Betr" "";
BA_DEF_DEF_  "GenSigAltSetting" "";
BA_DEF_DEF_  "GenSigAssignSetting" "";
BA_DEF_DEF_  "GenSigAutoGenDsp" "";
BA_DEF_DEF_  "GenSigAutoGenSnd" "";
BA_DEF_DEF_  "GenSigConditionalSend" "";
BA_DEF_DEF_  "GenSigEnvVarType" "undef";
BA_DEF_DEF_  "GenSigEVName" "";
BA_DEF_DEF_  "GenSigInactiveValue" 0;
BA_DEF_DEF_  "GenSigPostIfSetting" "";
BA_DEF_DEF_  "GenSigPostSetting" "";
BA_DEF_DEF_  "GenSigPreIfSetting" "";
BA_DEF_DEF_  "GenSigPreSetting" "";
BA_DEF_DEF_  "GenSigSendType" "Cyclic";
BA_DEF_DEF_  "GenSigStartValue" 0;
BA_DEF_DEF_  "NWM-WakeupAllowed" "";
BA_DEF_DEF_  "NMH-WakeupAllowed" "";
BA_DEF_DEF_  "GenSigTimeoutMsg_Motor_EDC17_003" 0;
BA_DEF_DEF_  "GenSigTimeoutMsg_Motor_EDC17_004" 0;
BA_DEF_DEF_  "GenSigTimeoutMsg_Motor_MED17_B8" 0;
BA_DEF_DEF_  "GenSigTimeoutMsg_Motor_MED9_B8" 0;
BA_DEF_DEF_  "GenSigTimeoutMsg_Motor_SIMOS8_B8" 0;
BA_DEF_DEF_  "GenSigTimeoutMsg_Daempfer_B8" 0;
BA_DEF_DEF_  "GenSigTimeoutMsg_Gateway_B8" 0;
BA_DEF_DEF_  "GenSigTimeoutMsg_Getriebe_AL6000" 0;
BA_DEF_DEF_  "GenSigTimeoutMsg_Getriebe_DL5001" 0;
BA_DEF_DEF_  "GenSigTimeoutMsg_Getriebe_VL3002" 0;
BA_DEF_DEF_  "GenSigTimeoutMsg_AFS_B8" 0;
BA_DEF_DEF_  "GenSigTimeoutMsg_Motor_Slave_B8" 0;
BA_DEF_DEF_  "GenSigTimeoutMsg_Airbag_B8" 0;
BA_DEF_DEF_  "GenSigTimeoutMsg_LWR_B8" 0;
BA_DEF_DEF_  "GenSigFuncType" "";
BA_DEF_DEF_  "GenSigSwitchedByIgnition" "";
BA_DEF_DEF_  "Fehlerwert" 0;
BA_DEF_DEF_  "GenSigMissingSourceValue" 0;
BA_DEF_DEF_  "SystemSignalLongSymbol" "";
BA_ "GenMsgCycleTime" BO_ 1601 1000;
BA_ "GenMsgILSupport" BO_ 1601 1;
BA_ "akt_Dateninh_NM_Betr" BO_ 1601 1;
BA_ "GenMsgCycleTime" BO_ 1090 100;
BA_ "GenMsgILSupport" BO_ 1090 1;
BA_ "akt_Dateninh_NM_Betr" BO_ 1090 1;
BA_ "GenMsgCycleTime" BO_ 1728 100;
BA_ "GenMsgILSupport" BO_ 1728 0;
BA_ "NmhMessage" BO_ 1728 1;
BA_ "akt_Dateninh_NM_Betr" BO_ 1728 1;
BA_ "GenMsgCycleTime" BO_ 1730 100;
BA_ "GenMsgILSupport" BO_ 1730 0;
BA_ "NmhMessage" BO_ 1730 1;
BA_ "akt_Dateninh_NM_Betr" BO_ 1730 1;
BA_ "GenMsgCycleTime" BO_ 1729 100;
BA_ "GenMsgILSupport" BO_ 1729 0;
BA_ "NmhMessage" BO_ 1729 1;
BA_ "akt_Dateninh_NM_Betr" BO_ 1729 1;
BA_ "GenMsgCycleTime" BO_ 913 100;
BA_ "GenMsgILSupport" BO_ 913 1;
BA_ "akt_Dateninh_NM_Betr" BO_ 913 1;
BA_ "GenMsgCycleTime" BO_ 1630 500;
BA_ "GenMsgILSupport" BO_ 1630 1;
BA_ "akt_Dateninh_NM_Betr" BO_ 1630 1;
BA_ "GenMsgCycleTime" BO_ 133 10;
BA_ "GenMsgILSupport" BO_ 133 1;
BA_ "Timeoutzeit" BO_ 133 500;
BA_ "akt_Dateninh_NM_Betr" BO_ 133 0;
BA_ "GenMsgCycleTime" BO_ 1313 200;
BA_ "GenMsgDelayTime" BO_ 1313 50;
BA_ "GenMsgILSupport" BO_ 1313 1;
BA_ "akt_Dateninh_NM_Betr" BO_ 1313 1;
BA_ "GenMsgCycleTime" BO_ 1413 1000;
BA_ "GenMsgDelayTime" BO_ 1413 200;
BA_ "GenMsgILSupport" BO_ 1413 1;
BA_ "GenMsgSendType" BO_ 1413 5;
BA_ "akt_Dateninh_NM_Betr" BO_ 1413 1;
BA_ "GenMsgCycleTime" BO_ 1300 1;
BA_ "GenMsgILSupport" BO_ 1300 0;
BA_ "GenMsgSendType" BO_ 1300 1;
BA_ "VAGTP20_DynConnection" BO_ 1300 1;
BA_ "akt_Dateninh_NM_Betr" BO_ 1300 1;
BA_ "GenMsgCycleTime" BO_ 1196 1;
BA_ "GenMsgILSupport" BO_ 1196 0;
BA_ "GenMsgSendType" BO_ 1196 1;
BA_ "VAGTP20_DynConnection" BO_ 1196 1;
BA_ "akt_Dateninh_NM_Betr" BO_ 1196 1;
BA_ "GenMsgCycleTime" BO_ 1215 1;
BA_ "GenMsgILSupport" BO_ 1215 0;
BA_ "GenMsgSendType" BO_ 1215 1;
BA_ "VAGTP20_DynConnection" BO_ 1215 1;
BA_ "akt_Dateninh_NM_Betr" BO_ 1215 1;
BA_ "GenMsgCycleTime" BO_ 1303 1;
BA_ "GenMsgILSupport" BO_ 1303 0;
BA_ "GenMsgSendType" BO_ 1303 1;
BA_ "VAGTP20_DynConnection" BO_ 1303 1;
BA_ "akt_Dateninh_NM_Betr" BO_ 1303 1;
BA_ "GenMsgCycleTime" BO_ 1186 1;
BA_ "GenMsgILSupport" BO_ 1186 0;
BA_ "GenMsgSendType" BO_ 1186 1;
BA_ "VAGTP20_DynConnection" BO_ 1186 1;
BA_ "akt_Dateninh_NM_Betr" BO_ 1186 1;
BA_ "GenMsgCycleTime" BO_ 1190 1;
BA_ "GenMsgILSupport" BO_ 1190 0;
BA_ "GenMsgSendType" BO_ 1190 1;
BA_ "VAGTP20_DynConnection" BO_ 1190 1;
BA_ "akt_Dateninh_NM_Betr" BO_ 1190 1;
BA_ "GenMsgCycleTime" BO_ 1185 1;
BA_ "GenMsgILSupport" BO_ 1185 0;
BA_ "GenMsgSendType" BO_ 1185 1;
BA_ "VAGTP20_DynConnection" BO_ 1185 1;
BA_ "akt_Dateninh_NM_Betr" BO_ 1185 1;
BA_ "GenMsgCycleTime" BO_ 1205 1;
BA_ "GenMsgILSupport" BO_ 1205 0;
BA_ "GenMsgSendType" BO_ 1205 1;
BA_ "VAGTP20_DynConnection" BO_ 1205 1;
BA_ "akt_Dateninh_NM_Betr" BO_ 1205 1;
BA_ "GenMsgAutoGenDsp" BO_ 768 0;
BA_ "GenMsgAutoGenSnd" BO_ 768 0;
BA_ "GenMsgCycleTime" BO_ 768 1;
BA_ "GenMsgILSupport" BO_ 768 0;
BA_ "GenMsgSendType" BO_ 768 1;
BA_ "VAGTP20_DynConnection" BO_ 768 1;
BA_ "akt_Dateninh_NM_Betr" BO_ 768 1;
BA_ "GenMsgAutoGenDsp" BO_ 769 0;
BA_ "GenMsgAutoGenSnd" BO_ 769 0;
BA_ "GenMsgCycleTime" BO_ 769 1;
BA_ "GenMsgILSupport" BO_ 769 0;
BA_ "GenMsgSendType" BO_ 769 1;
BA_ "VAGTP20_DynConnection" BO_ 769 1;
BA_ "akt_Dateninh_NM_Betr" BO_ 769 1;
BA_ "GenMsgAutoGenDsp" BO_ 770 0;
BA_ "GenMsgAutoGenSnd" BO_ 770 0;
BA_ "GenMsgCycleTime" BO_ 770 1;
BA_ "GenMsgILSupport" BO_ 770 0;
BA_ "GenMsgSendType" BO_ 770 1;
BA_ "VAGTP20_DynConnection" BO_ 770 1;
BA_ "akt_Dateninh_NM_Betr" BO_ 770 1;
BA_ "GenMsgAutoGenDsp" BO_ 771 0;
BA_ "GenMsgAutoGenSnd" BO_ 771 0;
BA_ "GenMsgCycleTime" BO_ 771 1;
BA_ "GenMsgILSupport" BO_ 771 0;
BA_ "GenMsgSendType" BO_ 771 1;
BA_ "VAGTP20_DynConnection" BO_ 771 1;
BA_ "akt_Dateninh_NM_Betr" BO_ 771 1;
BA_ "GenMsgAutoGenDsp" BO_ 772 0;
BA_ "GenMsgAutoGenSnd" BO_ 772 0;
BA_ "GenMsgCycleTime" BO_ 772 1;
BA_ "GenMsgILSupport" BO_ 772 0;
BA_ "GenMsgSendType" BO_ 772 1;
BA_ "VAGTP20_DynConnection" BO_ 772 1;
BA_ "akt_Dateninh_NM_Betr" BO_ 772 1;
BA_ "GenMsgAutoGenDsp" BO_ 773 0;
BA_ "GenMsgAutoGenSnd" BO_ 773 0;
BA_ "GenMsgCycleTime" BO_ 773 1;
BA_ "GenMsgILSupport" BO_ 773 0;
BA_ "GenMsgSendType" BO_ 773 1;
BA_ "VAGTP20_DynConnection" BO_ 773 1;
BA_ "akt_Dateninh_NM_Betr" BO_ 773 1;
BA_ "GenMsgAutoGenDsp" BO_ 774 0;
BA_ "GenMsgAutoGenSnd" BO_ 774 0;
BA_ "GenMsgCycleTime" BO_ 774 1;
BA_ "GenMsgILSupport" BO_ 774 0;
BA_ "GenMsgSendType" BO_ 774 1;
BA_ "VAGTP20_DynConnection" BO_ 774 1;
BA_ "akt_Dateninh_NM_Betr" BO_ 774 1;
BA_ "GenMsgAutoGenDsp" BO_ 775 0;
BA_ "GenMsgAutoGenSnd" BO_ 775 0;
BA_ "GenMsgCycleTime" BO_ 775 1;
BA_ "GenMsgILSupport" BO_ 775 0;
BA_ "GenMsgSendType" BO_ 775 1;
BA_ "VAGTP20_DynConnection" BO_ 775 1;
BA_ "akt_Dateninh_NM_Betr" BO_ 775 1;
BA_ "GenMsgILSupport" BO_ 517 0;
BA_ "GenMsgSendType" BO_ 517 1;
BA_ "VAGTP20_DynSetup" BO_ 517 1;
BA_ "akt_Dateninh_NM_Betr" BO_ 517 1;
BA_ "GenMsgILSupport" BO_ 524 0;
BA_ "GenMsgSendType" BO_ 524 1;
BA_ "VAGTP20_DynSetup" BO_ 524 1;
BA_ "akt_Dateninh_NM_Betr" BO_ 524 1;
BA_ "GenMsgILSupport" BO_ 543 0;
BA_ "GenMsgSendType" BO_ 543 1;
BA_ "VAGTP20_DynSetup" BO_ 543 1;
BA_ "akt_Dateninh_NM_Betr" BO_ 543 1;
BA_ "GenMsgILSupport" BO_ 514 0;
BA_ "GenMsgSendType" BO_ 514 1;
BA_ "VAGTP20_DynSetup" BO_ 514 1;
BA_ "akt_Dateninh_NM_Betr" BO_ 514 1;
BA_ "GenMsgILSupport" BO_ 518 0;
BA_ "GenMsgSendType" BO_ 518 1;
BA_ "VAGTP20_DynSetup" BO_ 518 1;
BA_ "akt_Dateninh_NM_Betr" BO_ 518 1;
BA_ "GenMsgILSupport" BO_ 513 0;
BA_ "GenMsgSendType" BO_ 513 1;
BA_ "VAGTP20_DynSetup" BO_ 513 1;
BA_ "akt_Dateninh_NM_Betr" BO_ 513 1;
BA_ "GenMsgILSupport" BO_ 533 0;
BA_ "GenMsgSendType" BO_ 533 1;
BA_ "VAGTP20_DynSetup" BO_ 533 1;
BA_ "akt_Dateninh_NM_Betr" BO_ 533 1;
BA_ "GenMsgILSupport" BO_ 512 0;
BA_ "GenMsgSendType" BO_ 512 1;
BA_ "VAGTP20_DynSetup" BO_ 512 1;
BA_ "akt_Dateninh_NM_Betr" BO_ 512 1;
BA_ "GenMsgCycleTime" BO_ 266 20;
BA_ "GenMsgILSupport" BO_ 266 1;
BA_ "akt_Dateninh_NM_Betr" BO_ 266 1;
BA_ "GenMsgCycleTime" BO_ 268 20;
BA_ "GenMsgILSupport" BO_ 268 1;
BA_ "akt_Dateninh_NM_Betr" BO_ 268 1;
BA_ "GenMsgCycleTime" BO_ 786 50;
BA_ "GenMsgILSupport" BO_ 786 1;
BA_ "GenMsgSendType" BO_ 786 5;
BA_ "akt_Dateninh_NM_Betr" BO_ 786 1;
BA_ "GenMsgCycleTime" BO_ 270 20;
BA_ "GenMsgILSupport" BO_ 270 1;
BA_ "akt_Dateninh_NM_Betr" BO_ 270 1;
BA_ "GenMsgCycleTime" BO_ 1716 1000;
BA_ "GenMsgILSupport" BO_ 1716 1;
BA_ "akt_Dateninh_NM_Betr" BO_ 1716 1;
BA_ "GenMsgCycleTime" BO_ 912 100;
BA_ "GenMsgILSupport" BO_ 912 1;
BA_ "GenMsgSendType" BO_ 912 5;
BA_ "akt_Dateninh_NM_Betr" BO_ 912 1;
BA_ "GenMsgCycleTime" BO_ 1602 2000;
BA_ "GenMsgILSupport" BO_ 1602 1;
BA_ "GenMsgSendType" BO_ 1602 5;
BA_ "akt_Dateninh_NM_Betr" BO_ 1602 1;
BA_ "GenMsgILSupport" BO_ 2617009149 0;
BA_ "GenMsgSendType" BO_ 2617009149 7;
BA_ "akt_Dateninh_NM_Betr" BO_ 2617009149 1;
BA_ "GenMsgILSupport" BO_ 2617009150 0;
BA_ "GenMsgSendType" BO_ 2617009150 7;
BA_ "akt_Dateninh_NM_Betr" BO_ 2617009150 1;
BA_ "GenSigAutoGenDsp" SG_ 1601 Motor_Code_01_CHK 1;
BA_ "GenSigAutoGenSnd" SG_ 1601 Motor_Code_01_CHK 1;
BA_ "GenSigEnvVarType" SG_ 1601 Motor_Code_01_CHK 0;
BA_ "GenSigSendType" SG_ 1601 Motor_Code_01_CHK 7;
BA_ "NWM-WakeupAllowed" SG_ 1601 Motor_Code_01_CHK 0;
BA_ "NMH-WakeupAllowed" SG_ 1601 Motor_Code_01_CHK 0;
BA_ "GenSigTimeoutMsg_Daempfer_B8" SG_ 1601 Motor_Code_01_CHK 1601;
BA_ "GenSigTimeoutMsg_Gateway_B8" SG_ 1601 Motor_Code_01_CHK 1601;
BA_ "GenSigTimeoutMsg_Getriebe_AL6000" SG_ 1601 Motor_Code_01_CHK 1601;
BA_ "GenSigTimeoutMsg_Getriebe_DL5001" SG_ 1601 Motor_Code_01_CHK 1601;
BA_ "GenSigTimeoutMsg_Getriebe_VL3002" SG_ 1601 Motor_Code_01_CHK 1601;
BA_ "GenSigAutoGenDsp" SG_ 1601 Motor_Code_01_BZ 1;
BA_ "GenSigAutoGenSnd" SG_ 1601 Motor_Code_01_BZ 1;
BA_ "GenSigEnvVarType" SG_ 1601 Motor_Code_01_BZ 0;
BA_ "GenSigSendType" SG_ 1601 Motor_Code_01_BZ 7;
BA_ "NWM-WakeupAllowed" SG_ 1601 Motor_Code_01_BZ 0;
BA_ "NMH-WakeupAllowed" SG_ 1601 Motor_Code_01_BZ 0;
BA_ "GenSigTimeoutMsg_Daempfer_B8" SG_ 1601 Motor_Code_01_BZ 1601;
BA_ "GenSigTimeoutMsg_Gateway_B8" SG_ 1601 Motor_Code_01_BZ 1601;
BA_ "GenSigTimeoutMsg_Getriebe_AL6000" SG_ 1601 Motor_Code_01_BZ 1601;
BA_ "GenSigTimeoutMsg_Getriebe_DL5001" SG_ 1601 Motor_Code_01_BZ 1601;
BA_ "GenSigTimeoutMsg_Getriebe_VL3002" SG_ 1601 Motor_Code_01_BZ 1601;
BA_ "GenSigAutoGenDsp" SG_ 1601 MO_Faktor_Momente 1;
BA_ "GenSigAutoGenSnd" SG_ 1601 MO_Faktor_Momente 1;
BA_ "GenSigEnvVarType" SG_ 1601 MO_Faktor_Momente 0;
BA_ "GenSigSendType" SG_ 1601 MO_Faktor_Momente 7;
BA_ "NWM-WakeupAllowed" SG_ 1601 MO_Faktor_Momente 0;
BA_ "NMH-WakeupAllowed" SG_ 1601 MO_Faktor_Momente 0;
BA_ "GenSigTimeoutMsg_Daempfer_B8" SG_ 1601 MO_Faktor_Momente 1601;
BA_ "GenSigTimeoutMsg_Gateway_B8" SG_ 1601 MO_Faktor_Momente 1601;
BA_ "GenSigTimeoutMsg_Getriebe_AL6000" SG_ 1601 MO_Faktor_Momente 1601;
BA_ "GenSigTimeoutMsg_Getriebe_DL5001" SG_ 1601 MO_Faktor_Momente 1601;
BA_ "GenSigTimeoutMsg_Getriebe_VL3002" SG_ 1601 MO_Faktor_Momente 1601;
BA_ "GenSigAutoGenDsp" SG_ 1601 MO_Code 1;
BA_ "GenSigAutoGenSnd" SG_ 1601 MO_Code 1;
BA_ "GenSigEnvVarType" SG_ 1601 MO_Code 0;
BA_ "GenSigSendType" SG_ 1601 MO_Code 7;
BA_ "NWM-WakeupAllowed" SG_ 1601 MO_Code 0;
BA_ "NMH-WakeupAllowed" SG_ 1601 MO_Code 0;
BA_ "GenSigTimeoutMsg_Gateway_B8" SG_ 1601 MO_Code 1601;
BA_ "GenSigTimeoutMsg_Getriebe_AL6000" SG_ 1601 MO_Code 1601;
BA_ "GenSigTimeoutMsg_Getriebe_DL5001" SG_ 1601 MO_Code 1601;
BA_ "GenSigTimeoutMsg_Getriebe_VL3002" SG_ 1601 MO_Code 1601;
BA_ "GenSigAutoGenDsp" SG_ 1601 MO_Getriebe_Code 1;
BA_ "GenSigAutoGenSnd" SG_ 1601 MO_Getriebe_Code 1;
BA_ "GenSigEnvVarType" SG_ 1601 MO_Getriebe_Code 0;
BA_ "GenSigSendType" SG_ 1601 MO_Getriebe_Code 7;
BA_ "NWM-WakeupAllowed" SG_ 1601 MO_Getriebe_Code 0;
BA_ "NMH-WakeupAllowed" SG_ 1601 MO_Getriebe_Code 0;
BA_ "GenSigTimeoutMsg_Gateway_B8" SG_ 1601 MO_Getriebe_Code 1601;
BA_ "GenSigTimeoutMsg_Getriebe_AL6000" SG_ 1601 MO_Getriebe_Code 1601;
BA_ "GenSigTimeoutMsg_Getriebe_DL5001" SG_ 1601 MO_Getriebe_Code 1601;
BA_ "GenSigTimeoutMsg_Getriebe_VL3002" SG_ 1601 MO_Getriebe_Code 1601;
BA_ "GenSigAutoGenDsp" SG_ 1601 MO_Anzahl_Zyl 1;
BA_ "GenSigAutoGenSnd" SG_ 1601 MO_Anzahl_Zyl 1;
BA_ "GenSigEnvVarType" SG_ 1601 MO_Anzahl_Zyl 0;
BA_ "GenSigSendType" SG_ 1601 MO_Anzahl_Zyl 7;
BA_ "NWM-WakeupAllowed" SG_ 1601 MO_Anzahl_Zyl 0;
BA_ "NMH-WakeupAllowed" SG_ 1601 MO_Anzahl_Zyl 0;
BA_ "GenSigTimeoutMsg_Gateway_B8" SG_ 1601 MO_Anzahl_Zyl 1601;
BA_ "GenSigAutoGenDsp" SG_ 1601 MO_Kraftstoffart 1;
BA_ "GenSigAutoGenSnd" SG_ 1601 MO_Kraftstoffart 1;
BA_ "GenSigEnvVarType" SG_ 1601 MO_Kraftstoffart 0;
BA_ "GenSigSendType" SG_ 1601 MO_Kraftstoffart 7;
BA_ "NWM-WakeupAllowed" SG_ 1601 MO_Kraftstoffart 0;
BA_ "NMH-WakeupAllowed" SG_ 1601 MO_Kraftstoffart 0;
BA_ "GenSigTimeoutMsg_Gateway_B8" SG_ 1601 MO_Kraftstoffart 1601;
BA_ "GenSigAutoGenDsp" SG_ 1601 MO_Hubraum 1;
BA_ "GenSigAutoGenSnd" SG_ 1601 MO_Hubraum 1;
BA_ "GenSigEnvVarType" SG_ 1601 MO_Hubraum 0;
BA_ "GenSigSendType" SG_ 1601 MO_Hubraum 7;
BA_ "NWM-WakeupAllowed" SG_ 1601 MO_Hubraum 0;
BA_ "NMH-WakeupAllowed" SG_ 1601 MO_Hubraum 0;
BA_ "GenSigTimeoutMsg_Gateway_B8" SG_ 1601 MO_Hubraum 1601;
BA_ "GenSigAutoGenDsp" SG_ 1601 MO_Ansaugsystem 1;
BA_ "GenSigAutoGenSnd" SG_ 1601 MO_Ansaugsystem 1;
BA_ "GenSigEnvVarType" SG_ 1601 MO_Ansaugsystem 0;
BA_ "GenSigSendType" SG_ 1601 MO_Ansaugsystem 7;
BA_ "NWM-WakeupAllowed" SG_ 1601 MO_Ansaugsystem 0;
BA_ "NMH-WakeupAllowed" SG_ 1601 MO_Ansaugsystem 0;
BA_ "GenSigTimeoutMsg_Gateway_B8" SG_ 1601 MO_Ansaugsystem 1601;
BA_ "GenSigAutoGenDsp" SG_ 1601 MO_Leistung 1;
BA_ "GenSigAutoGenSnd" SG_ 1601 MO_Leistung 1;
BA_ "GenSigEnvVarType" SG_ 1601 MO_Leistung 1;
BA_ "GenSigSendType" SG_ 1601 MO_Leistung 7;
BA_ "NWM-WakeupAllowed" SG_ 1601 MO_Leistung 0;
BA_ "NMH-WakeupAllowed" SG_ 1601 MO_Leistung 0;
BA_ "GenSigTimeoutMsg_Gateway_B8" SG_ 1601 MO_Leistung 1601;
BA_ "GenSigAutoGenDsp" SG_ 1601 MO_Abgastyp 1;
BA_ "GenSigAutoGenSnd" SG_ 1601 MO_Abgastyp 1;
BA_ "GenSigEnvVarType" SG_ 1601 MO_Abgastyp 1;
BA_ "GenSigSendType" SG_ 1601 MO_Abgastyp 7;
BA_ "NWM-WakeupAllowed" SG_ 1601 MO_Abgastyp 0;
BA_ "NMH-WakeupAllowed" SG_ 1601 MO_Abgastyp 0;
BA_ "GenSigTimeoutMsg_Gateway_B8" SG_ 1601 MO_Abgastyp 1601;
BA_ "GenSigTimeoutMsg_Getriebe_AL6000" SG_ 1601 MO_Abgastyp 1601;
BA_ "GenSigAutoGenDsp" SG_ 1601 MO_Einspritzart 1;
BA_ "GenSigAutoGenSnd" SG_ 1601 MO_Einspritzart 1;
BA_ "GenSigEnvVarType" SG_ 1601 MO_Einspritzart 0;
BA_ "GenSigSendType" SG_ 1601 MO_Einspritzart 7;
BA_ "NWM-WakeupAllowed" SG_ 1601 MO_Einspritzart 0;
BA_ "NMH-WakeupAllowed" SG_ 1601 MO_Einspritzart 0;
BA_ "GenSigTimeoutMsg_Gateway_B8" SG_ 1601 MO_Einspritzart 1601;
BA_ "GenSigAutoGenDsp" SG_ 1090 MOS_KD_Fehler 1;
BA_ "GenSigAutoGenSnd" SG_ 1090 MOS_KD_Fehler 1;
BA_ "GenSigEnvVarType" SG_ 1090 MOS_KD_Fehler 0;
BA_ "GenSigSendType" SG_ 1090 MOS_KD_Fehler 7;
BA_ "NWM-WakeupAllowed" SG_ 1090 MOS_KD_Fehler 0;
BA_ "NMH-WakeupAllowed" SG_ 1090 MOS_KD_Fehler 0;
BA_ "GenSigTimeoutMsg_Gateway_B8" SG_ 1090 MOS_KD_Fehler 1090;
BA_ "GenSigAutoGenDsp" SG_ 1728 NMH_GW_Start_1 1;
BA_ "GenSigAutoGenSnd" SG_ 1728 NMH_GW_Start_1 1;
BA_ "GenSigEnvVarType" SG_ 1728 NMH_GW_Start_1 0;
BA_ "GenSigSendType" SG_ 1728 NMH_GW_Start_1 7;
BA_ "GenSigStartValue" SG_ 1728 NMH_GW_Start_1 1;
BA_ "NWM-WakeupAllowed" SG_ 1728 NMH_GW_Start_1 0;
BA_ "NMH-WakeupAllowed" SG_ 1728 NMH_GW_Start_1 0;
BA_ "GenSigTimeoutMsg_Getriebe_AL6000" SG_ 1728 NMH_GW_Start_1 1728;
BA_ "GenSigTimeoutMsg_Getriebe_DL5001" SG_ 1728 NMH_GW_Start_1 1728;
BA_ "GenSigTimeoutMsg_Getriebe_VL3002" SG_ 1728 NMH_GW_Start_1 1728;
BA_ "GenSigTimeoutMsg_Motor_EDC17_003" SG_ 1728 NMH_GW_Start_1 1728;
BA_ "GenSigTimeoutMsg_Motor_EDC17_004" SG_ 1728 NMH_GW_Start_1 1728;
BA_ "GenSigTimeoutMsg_Motor_MED17_B8" SG_ 1728 NMH_GW_Start_1 1728;
BA_ "GenSigTimeoutMsg_Motor_MED9_B8" SG_ 1728 NMH_GW_Start_1 1728;
BA_ "GenSigTimeoutMsg_Motor_SIMOS8_B8" SG_ 1728 NMH_GW_Start_1 1728;
BA_ "GenSigAutoGenDsp" SG_ 1728 NMH_GW_Start_2 1;
BA_ "GenSigAutoGenSnd" SG_ 1728 NMH_GW_Start_2 1;
BA_ "GenSigEnvVarType" SG_ 1728 NMH_GW_Start_2 0;
BA_ "GenSigSendType" SG_ 1728 NMH_GW_Start_2 7;
BA_ "NWM-WakeupAllowed" SG_ 1728 NMH_GW_Start_2 0;
BA_ "NMH-WakeupAllowed" SG_ 1728 NMH_GW_Start_2 0;
BA_ "GenSigAutoGenDsp" SG_ 1728 NMH_GW_Normal_Mode_1 1;
BA_ "GenSigAutoGenSnd" SG_ 1728 NMH_GW_Normal_Mode_1 1;
BA_ "GenSigEnvVarType" SG_ 1728 NMH_GW_Normal_Mode_1 0;
BA_ "GenSigSendType" SG_ 1728 NMH_GW_Normal_Mode_1 7;
BA_ "NWM-WakeupAllowed" SG_ 1728 NMH_GW_Normal_Mode_1 0;
BA_ "NMH-WakeupAllowed" SG_ 1728 NMH_GW_Normal_Mode_1 0;
BA_ "GenSigAutoGenDsp" SG_ 1728 NMH_GW_Normal_Mode_2 1;
BA_ "GenSigAutoGenSnd" SG_ 1728 NMH_GW_Normal_Mode_2 1;
BA_ "GenSigEnvVarType" SG_ 1728 NMH_GW_Normal_Mode_2 0;
BA_ "GenSigSendType" SG_ 1728 NMH_GW_Normal_Mode_2 7;
BA_ "NWM-WakeupAllowed" SG_ 1728 NMH_GW_Normal_Mode_2 0;
BA_ "NMH-WakeupAllowed" SG_ 1728 NMH_GW_Normal_Mode_2 0;
BA_ "GenSigAutoGenDsp" SG_ 1728 NMH_GW_Car_WakeUp 1;
BA_ "GenSigAutoGenSnd" SG_ 1728 NMH_GW_Car_WakeUp 1;
BA_ "GenSigEnvVarType" SG_ 1728 NMH_GW_Car_WakeUp 0;
BA_ "GenSigSendType" SG_ 1728 NMH_GW_Car_WakeUp 7;
BA_ "NWM-WakeupAllowed" SG_ 1728 NMH_GW_Car_WakeUp 0;
BA_ "NMH-WakeupAllowed" SG_ 1728 NMH_GW_Car_WakeUp 0;
BA_ "GenSigAutoGenDsp" SG_ 1728 NMH_GW_Per_WakeUp 1;
BA_ "GenSigAutoGenSnd" SG_ 1728 NMH_GW_Per_WakeUp 1;
BA_ "GenSigEnvVarType" SG_ 1728 NMH_GW_Per_WakeUp 0;
BA_ "GenSigSendType" SG_ 1728 NMH_GW_Per_WakeUp 7;
BA_ "NWM-WakeupAllowed" SG_ 1728 NMH_GW_Per_WakeUp 1;
BA_ "NMH-WakeupAllowed" SG_ 1728 NMH_GW_Per_WakeUp 0;
BA_ "GenSigAutoGenDsp" SG_ 1728 NMH_GW_Fkt_WakeUp 1;
BA_ "GenSigAutoGenSnd" SG_ 1728 NMH_GW_Fkt_WakeUp 1;
BA_ "GenSigEnvVarType" SG_ 1728 NMH_GW_Fkt_WakeUp 0;
BA_ "GenSigSendType" SG_ 1728 NMH_GW_Fkt_WakeUp 7;
BA_ "NWM-WakeupAllowed" SG_ 1728 NMH_GW_Fkt_WakeUp 1;
BA_ "NMH-WakeupAllowed" SG_ 1728 NMH_GW_Fkt_WakeUp 0;
BA_ "GenSigAutoGenDsp" SG_ 1728 NMH_GW_NM_aktiv_Klemme_15 1;
BA_ "GenSigAutoGenSnd" SG_ 1728 NMH_GW_NM_aktiv_Klemme_15 1;
BA_ "GenSigEnvVarType" SG_ 1728 NMH_GW_NM_aktiv_Klemme_15 0;
BA_ "GenSigSendType" SG_ 1728 NMH_GW_NM_aktiv_Klemme_15 7;
BA_ "NWM-WakeupAllowed" SG_ 1728 NMH_GW_NM_aktiv_Klemme_15 0;
BA_ "NMH-WakeupAllowed" SG_ 1728 NMH_GW_NM_aktiv_Klemme_15 0;
BA_ "GenSigAutoGenDsp" SG_ 1728 NMH_GW_NM_aktiv_Diagnose 1;
BA_ "GenSigAutoGenSnd" SG_ 1728 NMH_GW_NM_aktiv_Diagnose 1;
BA_ "GenSigEnvVarType" SG_ 1728 NMH_GW_NM_aktiv_Diagnose 0;
BA_ "GenSigSendType" SG_ 1728 NMH_GW_NM_aktiv_Diagnose 7;
BA_ "NWM-WakeupAllowed" SG_ 1728 NMH_GW_NM_aktiv_Diagnose 0;
BA_ "NMH-WakeupAllowed" SG_ 1728 NMH_GW_NM_aktiv_Diagnose 0;
BA_ "GenSigAutoGenDsp" SG_ 1728 NMH_GW_NM_aktiv_Start 1;
BA_ "GenSigAutoGenSnd" SG_ 1728 NMH_GW_NM_aktiv_Start 1;
BA_ "GenSigEnvVarType" SG_ 1728 NMH_GW_NM_aktiv_Start 0;
BA_ "GenSigSendType" SG_ 1728 NMH_GW_NM_aktiv_Start 7;
BA_ "NWM-WakeupAllowed" SG_ 1728 NMH_GW_NM_aktiv_Start 0;
BA_ "NMH-WakeupAllowed" SG_ 1728 NMH_GW_NM_aktiv_Start 0;
BA_ "GenSigAutoGenDsp" SG_ 1728 NMH_GW_NM_aktiv_BDM 1;
BA_ "GenSigAutoGenSnd" SG_ 1728 NMH_GW_NM_aktiv_BDM 1;
BA_ "GenSigSendType" SG_ 1728 NMH_GW_NM_aktiv_BDM 7;
BA_ "NWM-WakeupAllowed" SG_ 1728 NMH_GW_NM_aktiv_BDM 0;
BA_ "NMH-WakeupAllowed" SG_ 1728 NMH_GW_NM_aktiv_BDM 0;
BA_ "GenSigAutoGenDsp" SG_ 1728 NMH_GW_NM_aktiv_Warnblinken 1;
BA_ "GenSigAutoGenSnd" SG_ 1728 NMH_GW_NM_aktiv_Warnblinken 1;
BA_ "GenSigSendType" SG_ 1728 NMH_GW_NM_aktiv_Warnblinken 7;
BA_ "NWM-WakeupAllowed" SG_ 1728 NMH_GW_NM_aktiv_Warnblinken 0;
BA_ "NMH-WakeupAllowed" SG_ 1728 NMH_GW_NM_aktiv_Warnblinken 0;
BA_ "GenSigAutoGenDsp" SG_ 1728 NMH_GW_NM_aktiv_ESP 1;
BA_ "GenSigAutoGenSnd" SG_ 1728 NMH_GW_NM_aktiv_ESP 1;
BA_ "GenSigSendType" SG_ 1728 NMH_GW_NM_aktiv_ESP 7;
BA_ "NWM-WakeupAllowed" SG_ 1728 NMH_GW_NM_aktiv_ESP 0;
BA_ "NMH-WakeupAllowed" SG_ 1728 NMH_GW_NM_aktiv_ESP 0;
BA_ "GenSigAutoGenDsp" SG_ 1728 NMH_GW_Abschaltstufe_3 1;
BA_ "GenSigAutoGenSnd" SG_ 1728 NMH_GW_Abschaltstufe_3 1;
BA_ "GenSigSendType" SG_ 1728 NMH_GW_Abschaltstufe_3 7;
BA_ "NWM-WakeupAllowed" SG_ 1728 NMH_GW_Abschaltstufe_3 0;
BA_ "NMH-WakeupAllowed" SG_ 1728 NMH_GW_Abschaltstufe_3 0;
BA_ "GenSigAutoGenDsp" SG_ 1728 NMH_GW_SG_Fehlerdauer 1;
BA_ "GenSigAutoGenSnd" SG_ 1728 NMH_GW_SG_Fehlerdauer 1;
BA_ "GenSigSendType" SG_ 1728 NMH_GW_SG_Fehlerdauer 7;
BA_ "NWM-WakeupAllowed" SG_ 1728 NMH_GW_SG_Fehlerdauer 0;
BA_ "NMH-WakeupAllowed" SG_ 1728 NMH_GW_SG_Fehlerdauer 0;
BA_ "GenSigAutoGenDsp" SG_ 1728 NMH_GW_STH_Wakeup 1;
BA_ "GenSigAutoGenSnd" SG_ 1728 NMH_GW_STH_Wakeup 1;
BA_ "GenSigSendType" SG_ 1728 NMH_GW_STH_Wakeup 7;
BA_ "NWM-WakeupAllowed" SG_ 1728 NMH_GW_STH_Wakeup 0;
BA_ "NMH-WakeupAllowed" SG_ 1728 NMH_GW_STH_Wakeup 0;
BA_ "GenSigAutoGenDsp" SG_ 1728 NMH_GW_TimeOut_Fehler 1;
BA_ "GenSigAutoGenSnd" SG_ 1728 NMH_GW_TimeOut_Fehler 1;
BA_ "GenSigEnvVarType" SG_ 1728 NMH_GW_TimeOut_Fehler 0;
BA_ "GenSigSendType" SG_ 1728 NMH_GW_TimeOut_Fehler 7;
BA_ "NWM-WakeupAllowed" SG_ 1728 NMH_GW_TimeOut_Fehler 0;
BA_ "NMH-WakeupAllowed" SG_ 1728 NMH_GW_TimeOut_Fehler 0;
BA_ "GenSigAutoGenDsp" SG_ 1728 NMH_GW_CAN_Diag_deaktiv 1;
BA_ "GenSigAutoGenSnd" SG_ 1728 NMH_GW_CAN_Diag_deaktiv 1;
BA_ "GenSigEnvVarType" SG_ 1728 NMH_GW_CAN_Diag_deaktiv 0;
BA_ "GenSigSendType" SG_ 1728 NMH_GW_CAN_Diag_deaktiv 7;
BA_ "NWM-WakeupAllowed" SG_ 1728 NMH_GW_CAN_Diag_deaktiv 0;
BA_ "NMH-WakeupAllowed" SG_ 1728 NMH_GW_CAN_Diag_deaktiv 0;
BA_ "GenSigAutoGenDsp" SG_ 1728 NMH_GW_KompSchutz 1;
BA_ "GenSigAutoGenSnd" SG_ 1728 NMH_GW_KompSchutz 1;
BA_ "GenSigEnvVarType" SG_ 1728 NMH_GW_KompSchutz 0;
BA_ "GenSigSendType" SG_ 1728 NMH_GW_KompSchutz 7;
BA_ "NWM-WakeupAllowed" SG_ 1728 NMH_GW_KompSchutz 0;
BA_ "NMH-WakeupAllowed" SG_ 1728 NMH_GW_KompSchutz 0;
BA_ "GenSigAutoGenDsp" SG_ 1728 NMH_GW_Mute_Mode 1;
BA_ "GenSigAutoGenSnd" SG_ 1728 NMH_GW_Mute_Mode 1;
BA_ "GenSigEnvVarType" SG_ 1728 NMH_GW_Mute_Mode 0;
BA_ "GenSigSendType" SG_ 1728 NMH_GW_Mute_Mode 7;
BA_ "NWM-WakeupAllowed" SG_ 1728 NMH_GW_Mute_Mode 0;
BA_ "NMH-WakeupAllowed" SG_ 1728 NMH_GW_Mute_Mode 0;
BA_ "GenSigAutoGenDsp" SG_ 1728 NMH_GW_Transport_Mode 1;
BA_ "GenSigAutoGenSnd" SG_ 1728 NMH_GW_Transport_Mode 1;
BA_ "GenSigEnvVarType" SG_ 1728 NMH_GW_Transport_Mode 0;
BA_ "GenSigSendType" SG_ 1728 NMH_GW_Transport_Mode 7;
BA_ "NWM-WakeupAllowed" SG_ 1728 NMH_GW_Transport_Mode 0;
BA_ "NMH-WakeupAllowed" SG_ 1728 NMH_GW_Transport_Mode 0;
BA_ "GenSigAutoGenDsp" SG_ 1728 NMH_GW_Abschaltstufe_aktiv 1;
BA_ "GenSigAutoGenSnd" SG_ 1728 NMH_GW_Abschaltstufe_aktiv 1;
BA_ "GenSigEnvVarType" SG_ 1728 NMH_GW_Abschaltstufe_aktiv 0;
BA_ "GenSigSendType" SG_ 1728 NMH_GW_Abschaltstufe_aktiv 7;
BA_ "NWM-WakeupAllowed" SG_ 1728 NMH_GW_Abschaltstufe_aktiv 0;
BA_ "NMH-WakeupAllowed" SG_ 1728 NMH_GW_Abschaltstufe_aktiv 0;
BA_ "GenSigAutoGenDsp" SG_ 1728 NMH_GW_Eindraht_Fehler 1;
BA_ "GenSigAutoGenSnd" SG_ 1728 NMH_GW_Eindraht_Fehler 1;
BA_ "GenSigEnvVarType" SG_ 1728 NMH_GW_Eindraht_Fehler 0;
BA_ "GenSigSendType" SG_ 1728 NMH_GW_Eindraht_Fehler 7;
BA_ "NWM-WakeupAllowed" SG_ 1728 NMH_GW_Eindraht_Fehler 0;
BA_ "NMH-WakeupAllowed" SG_ 1728 NMH_GW_Eindraht_Fehler 0;
BA_ "GenSigAutoGenDsp" SG_ 1728 NMH_GW_ACAN 1;
BA_ "GenSigAutoGenSnd" SG_ 1728 NMH_GW_ACAN 1;
BA_ "GenSigSendType" SG_ 1728 NMH_GW_ACAN 7;
BA_ "NWM-WakeupAllowed" SG_ 1728 NMH_GW_ACAN 0;
BA_ "NMH-WakeupAllowed" SG_ 1728 NMH_GW_ACAN 0;
BA_ "GenSigAutoGenDsp" SG_ 1728 NMH_GW_KombiCAN 1;
BA_ "GenSigAutoGenSnd" SG_ 1728 NMH_GW_KombiCAN 1;
BA_ "GenSigSendType" SG_ 1728 NMH_GW_KombiCAN 7;
BA_ "NWM-WakeupAllowed" SG_ 1728 NMH_GW_KombiCAN 0;
BA_ "NMH-WakeupAllowed" SG_ 1728 NMH_GW_KombiCAN 0;
BA_ "GenSigAutoGenDsp" SG_ 1728 NMH_GW_KomfortCAN 1;
BA_ "GenSigAutoGenSnd" SG_ 1728 NMH_GW_KomfortCAN 1;
BA_ "GenSigSendType" SG_ 1728 NMH_GW_KomfortCAN 7;
BA_ "NWM-WakeupAllowed" SG_ 1728 NMH_GW_KomfortCAN 0;
BA_ "NMH-WakeupAllowed" SG_ 1728 NMH_GW_KomfortCAN 0;
BA_ "GenSigAutoGenDsp" SG_ 1728 NMH_GW_Infotainment 1;
BA_ "GenSigAutoGenSnd" SG_ 1728 NMH_GW_Infotainment 1;
BA_ "GenSigSendType" SG_ 1728 NMH_GW_Infotainment 7;
BA_ "NWM-WakeupAllowed" SG_ 1728 NMH_GW_Infotainment 0;
BA_ "NMH-WakeupAllowed" SG_ 1728 NMH_GW_Infotainment 0;
BA_ "GenSigAutoGenDsp" SG_ 1728 NMH_GW_WakeUp_CAN_Bus 1;
BA_ "GenSigAutoGenSnd" SG_ 1728 NMH_GW_WakeUp_CAN_Bus 1;
BA_ "GenSigSendType" SG_ 1728 NMH_GW_WakeUp_CAN_Bus 7;
BA_ "NWM-WakeupAllowed" SG_ 1728 NMH_GW_WakeUp_CAN_Bus 0;
BA_ "NMH-WakeupAllowed" SG_ 1728 NMH_GW_WakeUp_CAN_Bus 0;
BA_ "GenSigAutoGenDsp" SG_ 1730 NMH_GE_Start_1 1;
BA_ "GenSigAutoGenSnd" SG_ 1730 NMH_GE_Start_1 1;
BA_ "GenSigEnvVarType" SG_ 1730 NMH_GE_Start_1 0;
BA_ "GenSigSendType" SG_ 1730 NMH_GE_Start_1 7;
BA_ "GenSigStartValue" SG_ 1730 NMH_GE_Start_1 1;
BA_ "NWM-WakeupAllowed" SG_ 1730 NMH_GE_Start_1 0;
BA_ "NMH-WakeupAllowed" SG_ 1730 NMH_GE_Start_1 0;
BA_ "GenSigTimeoutMsg_Motor_EDC17_003" SG_ 1730 NMH_GE_Start_1 1730;
BA_ "GenSigTimeoutMsg_Motor_EDC17_004" SG_ 1730 NMH_GE_Start_1 1730;
BA_ "GenSigTimeoutMsg_Motor_MED17_B8" SG_ 1730 NMH_GE_Start_1 1730;
BA_ "GenSigTimeoutMsg_Motor_MED9_B8" SG_ 1730 NMH_GE_Start_1 1730;
BA_ "GenSigTimeoutMsg_Motor_SIMOS8_B8" SG_ 1730 NMH_GE_Start_1 1730;
BA_ "GenSigAutoGenDsp" SG_ 1730 NMH_GE_Start_2 1;
BA_ "GenSigAutoGenSnd" SG_ 1730 NMH_GE_Start_2 1;
BA_ "GenSigEnvVarType" SG_ 1730 NMH_GE_Start_2 0;
BA_ "GenSigSendType" SG_ 1730 NMH_GE_Start_2 7;
BA_ "NWM-WakeupAllowed" SG_ 1730 NMH_GE_Start_2 0;
BA_ "NMH-WakeupAllowed" SG_ 1730 NMH_GE_Start_2 0;
BA_ "GenSigAutoGenDsp" SG_ 1730 NMH_GE_Normal_Mode_1 1;
BA_ "GenSigAutoGenSnd" SG_ 1730 NMH_GE_Normal_Mode_1 1;
BA_ "GenSigEnvVarType" SG_ 1730 NMH_GE_Normal_Mode_1 0;
BA_ "GenSigSendType" SG_ 1730 NMH_GE_Normal_Mode_1 7;
BA_ "NWM-WakeupAllowed" SG_ 1730 NMH_GE_Normal_Mode_1 0;
BA_ "NMH-WakeupAllowed" SG_ 1730 NMH_GE_Normal_Mode_1 0;
BA_ "GenSigAutoGenDsp" SG_ 1730 NMH_GE_Normal_Mode_2 1;
BA_ "GenSigAutoGenSnd" SG_ 1730 NMH_GE_Normal_Mode_2 1;
BA_ "GenSigEnvVarType" SG_ 1730 NMH_GE_Normal_Mode_2 0;
BA_ "GenSigSendType" SG_ 1730 NMH_GE_Normal_Mode_2 7;
BA_ "NWM-WakeupAllowed" SG_ 1730 NMH_GE_Normal_Mode_2 0;
BA_ "NMH-WakeupAllowed" SG_ 1730 NMH_GE_Normal_Mode_2 0;
BA_ "GenSigAutoGenDsp" SG_ 1730 NMH_GE_Car_WakeUp 1;
BA_ "GenSigAutoGenSnd" SG_ 1730 NMH_GE_Car_WakeUp 1;
BA_ "GenSigEnvVarType" SG_ 1730 NMH_GE_Car_WakeUp 0;
BA_ "GenSigSendType" SG_ 1730 NMH_GE_Car_WakeUp 7;
BA_ "NWM-WakeupAllowed" SG_ 1730 NMH_GE_Car_WakeUp 0;
BA_ "NMH-WakeupAllowed" SG_ 1730 NMH_GE_Car_WakeUp 0;
BA_ "GenSigTimeoutMsg_Gateway_B8" SG_ 1730 NMH_GE_Car_WakeUp 1730;
BA_ "GenSigAutoGenDsp" SG_ 1730 NMH_GE_Per_WakeUp 1;
BA_ "GenSigAutoGenSnd" SG_ 1730 NMH_GE_Per_WakeUp 1;
BA_ "GenSigEnvVarType" SG_ 1730 NMH_GE_Per_WakeUp 0;
BA_ "GenSigSendType" SG_ 1730 NMH_GE_Per_WakeUp 7;
BA_ "NWM-WakeupAllowed" SG_ 1730 NMH_GE_Per_WakeUp 1;
BA_ "NMH-WakeupAllowed" SG_ 1730 NMH_GE_Per_WakeUp 0;
BA_ "GenSigAutoGenDsp" SG_ 1730 NMH_GE_Fkt_WakeUp 1;
BA_ "GenSigAutoGenSnd" SG_ 1730 NMH_GE_Fkt_WakeUp 1;
BA_ "GenSigEnvVarType" SG_ 1730 NMH_GE_Fkt_WakeUp 0;
BA_ "GenSigSendType" SG_ 1730 NMH_GE_Fkt_WakeUp 7;
BA_ "NWM-WakeupAllowed" SG_ 1730 NMH_GE_Fkt_WakeUp 1;
BA_ "NMH-WakeupAllowed" SG_ 1730 NMH_GE_Fkt_WakeUp 0;
BA_ "GenSigAutoGenDsp" SG_ 1730 NMH_GE_NM_aktiv_Klemme_15 1;
BA_ "GenSigAutoGenSnd" SG_ 1730 NMH_GE_NM_aktiv_Klemme_15 1;
BA_ "GenSigEnvVarType" SG_ 1730 NMH_GE_NM_aktiv_Klemme_15 0;
BA_ "GenSigSendType" SG_ 1730 NMH_GE_NM_aktiv_Klemme_15 7;
BA_ "NWM-WakeupAllowed" SG_ 1730 NMH_GE_NM_aktiv_Klemme_15 0;
BA_ "NMH-WakeupAllowed" SG_ 1730 NMH_GE_NM_aktiv_Klemme_15 0;
BA_ "GenSigAutoGenDsp" SG_ 1730 NMH_GE_NM_aktiv_Diagnose 1;
BA_ "GenSigAutoGenSnd" SG_ 1730 NMH_GE_NM_aktiv_Diagnose 1;
BA_ "GenSigEnvVarType" SG_ 1730 NMH_GE_NM_aktiv_Diagnose 0;
BA_ "GenSigSendType" SG_ 1730 NMH_GE_NM_aktiv_Diagnose 7;
BA_ "NWM-WakeupAllowed" SG_ 1730 NMH_GE_NM_aktiv_Diagnose 0;
BA_ "NMH-WakeupAllowed" SG_ 1730 NMH_GE_NM_aktiv_Diagnose 0;
BA_ "GenSigAutoGenDsp" SG_ 1730 NMH_GE_NM_aktiv_Start 1;
BA_ "GenSigAutoGenSnd" SG_ 1730 NMH_GE_NM_aktiv_Start 1;
BA_ "GenSigEnvVarType" SG_ 1730 NMH_GE_NM_aktiv_Start 0;
BA_ "GenSigSendType" SG_ 1730 NMH_GE_NM_aktiv_Start 7;
BA_ "NWM-WakeupAllowed" SG_ 1730 NMH_GE_NM_aktiv_Start 0;
BA_ "NMH-WakeupAllowed" SG_ 1730 NMH_GE_NM_aktiv_Start 0;
BA_ "GenSigAutoGenDsp" SG_ 1730 NMH_GE_kein_NL 1;
BA_ "GenSigAutoGenSnd" SG_ 1730 NMH_GE_kein_NL 1;
BA_ "GenSigSendType" SG_ 1730 NMH_GE_kein_NL 7;
BA_ "NWM-WakeupAllowed" SG_ 1730 NMH_GE_kein_NL 0;
BA_ "NMH-WakeupAllowed" SG_ 1730 NMH_GE_kein_NL 0;
BA_ "GenSigAutoGenDsp" SG_ 1730 NMH_GE_NL_Daten_EEPROM 1;
BA_ "GenSigAutoGenSnd" SG_ 1730 NMH_GE_NL_Daten_EEPROM 1;
BA_ "GenSigSendType" SG_ 1730 NMH_GE_NL_Daten_EEPROM 7;
BA_ "NWM-WakeupAllowed" SG_ 1730 NMH_GE_NL_Daten_EEPROM 0;
BA_ "NMH-WakeupAllowed" SG_ 1730 NMH_GE_NL_Daten_EEPROM 0;
BA_ "GenSigAutoGenDsp" SG_ 1730 NMH_GE_NL_Drucksens 1;
BA_ "GenSigAutoGenSnd" SG_ 1730 NMH_GE_NL_Drucksens 1;
BA_ "GenSigSendType" SG_ 1730 NMH_GE_NL_Drucksens 7;
BA_ "NWM-WakeupAllowed" SG_ 1730 NMH_GE_NL_Drucksens 0;
BA_ "NMH-WakeupAllowed" SG_ 1730 NMH_GE_NL_Drucksens 0;
BA_ "GenSigAutoGenDsp" SG_ 1730 NMH_GE_NL_Abtrieb 1;
BA_ "GenSigAutoGenSnd" SG_ 1730 NMH_GE_NL_Abtrieb 1;
BA_ "GenSigSendType" SG_ 1730 NMH_GE_NL_Abtrieb 7;
BA_ "NWM-WakeupAllowed" SG_ 1730 NMH_GE_NL_Abtrieb 0;
BA_ "NMH-WakeupAllowed" SG_ 1730 NMH_GE_NL_Abtrieb 0;
BA_ "GenSigAutoGenDsp" SG_ 1730 NMH_GE_NL_Waehlhebel 1;
BA_ "GenSigAutoGenSnd" SG_ 1730 NMH_GE_NL_Waehlhebel 1;
BA_ "GenSigSendType" SG_ 1730 NMH_GE_NL_Waehlhebel 7;
BA_ "NWM-WakeupAllowed" SG_ 1730 NMH_GE_NL_Waehlhebel 0;
BA_ "NMH-WakeupAllowed" SG_ 1730 NMH_GE_NL_Waehlhebel 0;
BA_ "GenSigAutoGenDsp" SG_ 1730 NMH_GE_NL_Wegfahrsperre 1;
BA_ "GenSigAutoGenSnd" SG_ 1730 NMH_GE_NL_Wegfahrsperre 1;
BA_ "GenSigSendType" SG_ 1730 NMH_GE_NL_Wegfahrsperre 7;
BA_ "NWM-WakeupAllowed" SG_ 1730 NMH_GE_NL_Wegfahrsperre 0;
BA_ "NMH-WakeupAllowed" SG_ 1730 NMH_GE_NL_Wegfahrsperre 0;
BA_ "GenSigAutoGenDsp" SG_ 1730 NMH_GE_TimeOut_Fehler 1;
BA_ "GenSigAutoGenSnd" SG_ 1730 NMH_GE_TimeOut_Fehler 1;
BA_ "GenSigEnvVarType" SG_ 1730 NMH_GE_TimeOut_Fehler 0;
BA_ "GenSigSendType" SG_ 1730 NMH_GE_TimeOut_Fehler 7;
BA_ "NWM-WakeupAllowed" SG_ 1730 NMH_GE_TimeOut_Fehler 0;
BA_ "NMH-WakeupAllowed" SG_ 1730 NMH_GE_TimeOut_Fehler 0;
BA_ "GenSigAutoGenDsp" SG_ 1730 NMH_GE_CAN_Diag_deaktiv 1;
BA_ "GenSigAutoGenSnd" SG_ 1730 NMH_GE_CAN_Diag_deaktiv 1;
BA_ "GenSigEnvVarType" SG_ 1730 NMH_GE_CAN_Diag_deaktiv 0;
BA_ "GenSigSendType" SG_ 1730 NMH_GE_CAN_Diag_deaktiv 7;
BA_ "NWM-WakeupAllowed" SG_ 1730 NMH_GE_CAN_Diag_deaktiv 0;
BA_ "NMH-WakeupAllowed" SG_ 1730 NMH_GE_CAN_Diag_deaktiv 0;
BA_ "GenSigAutoGenDsp" SG_ 1730 NMH_GE_KompSchutz 1;
BA_ "GenSigAutoGenSnd" SG_ 1730 NMH_GE_KompSchutz 1;
BA_ "GenSigEnvVarType" SG_ 1730 NMH_GE_KompSchutz 0;
BA_ "GenSigSendType" SG_ 1730 NMH_GE_KompSchutz 7;
BA_ "NWM-WakeupAllowed" SG_ 1730 NMH_GE_KompSchutz 0;
BA_ "NMH-WakeupAllowed" SG_ 1730 NMH_GE_KompSchutz 0;
BA_ "GenSigAutoGenDsp" SG_ 1730 NMH_GE_Mute_Mode 1;
BA_ "GenSigAutoGenSnd" SG_ 1730 NMH_GE_Mute_Mode 1;
BA_ "GenSigEnvVarType" SG_ 1730 NMH_GE_Mute_Mode 0;
BA_ "GenSigSendType" SG_ 1730 NMH_GE_Mute_Mode 7;
BA_ "NWM-WakeupAllowed" SG_ 1730 NMH_GE_Mute_Mode 0;
BA_ "NMH-WakeupAllowed" SG_ 1730 NMH_GE_Mute_Mode 0;
BA_ "GenSigAutoGenDsp" SG_ 1730 NMH_GE_Transport_Mode 1;
BA_ "GenSigAutoGenSnd" SG_ 1730 NMH_GE_Transport_Mode 1;
BA_ "GenSigEnvVarType" SG_ 1730 NMH_GE_Transport_Mode 0;
BA_ "GenSigSendType" SG_ 1730 NMH_GE_Transport_Mode 7;
BA_ "NWM-WakeupAllowed" SG_ 1730 NMH_GE_Transport_Mode 0;
BA_ "NMH-WakeupAllowed" SG_ 1730 NMH_GE_Transport_Mode 0;
BA_ "GenSigAutoGenDsp" SG_ 1730 NMH_GE_Abschaltstufe_aktiv 1;
BA_ "GenSigAutoGenSnd" SG_ 1730 NMH_GE_Abschaltstufe_aktiv 1;
BA_ "GenSigEnvVarType" SG_ 1730 NMH_GE_Abschaltstufe_aktiv 0;
BA_ "GenSigSendType" SG_ 1730 NMH_GE_Abschaltstufe_aktiv 7;
BA_ "NWM-WakeupAllowed" SG_ 1730 NMH_GE_Abschaltstufe_aktiv 0;
BA_ "NMH-WakeupAllowed" SG_ 1730 NMH_GE_Abschaltstufe_aktiv 0;
BA_ "GenSigAutoGenDsp" SG_ 1730 NMH_GE_Eindraht_Fehler 1;
BA_ "GenSigAutoGenSnd" SG_ 1730 NMH_GE_Eindraht_Fehler 1;
BA_ "GenSigEnvVarType" SG_ 1730 NMH_GE_Eindraht_Fehler 0;
BA_ "GenSigSendType" SG_ 1730 NMH_GE_Eindraht_Fehler 7;
BA_ "NWM-WakeupAllowed" SG_ 1730 NMH_GE_Eindraht_Fehler 0;
BA_ "NMH-WakeupAllowed" SG_ 1730 NMH_GE_Eindraht_Fehler 0;
BA_ "GenSigAutoGenDsp" SG_ 1729 NMH_MO_Start_1 1;
BA_ "GenSigAutoGenSnd" SG_ 1729 NMH_MO_Start_1 1;
BA_ "GenSigEnvVarType" SG_ 1729 NMH_MO_Start_1 0;
BA_ "GenSigSendType" SG_ 1729 NMH_MO_Start_1 7;
BA_ "GenSigStartValue" SG_ 1729 NMH_MO_Start_1 1;
BA_ "NWM-WakeupAllowed" SG_ 1729 NMH_MO_Start_1 0;
BA_ "NMH-WakeupAllowed" SG_ 1729 NMH_MO_Start_1 0;
BA_ "GenSigTimeoutMsg_Getriebe_AL6000" SG_ 1729 NMH_MO_Start_1 1729;
BA_ "GenSigTimeoutMsg_Getriebe_DL5001" SG_ 1729 NMH_MO_Start_1 1729;
BA_ "GenSigTimeoutMsg_Getriebe_VL3002" SG_ 1729 NMH_MO_Start_1 1729;
BA_ "GenSigAutoGenDsp" SG_ 1729 NMH_MO_Start_2 1;
BA_ "GenSigAutoGenSnd" SG_ 1729 NMH_MO_Start_2 1;
BA_ "GenSigEnvVarType" SG_ 1729 NMH_MO_Start_2 0;
BA_ "GenSigSendType" SG_ 1729 NMH_MO_Start_2 7;
BA_ "NWM-WakeupAllowed" SG_ 1729 NMH_MO_Start_2 0;
BA_ "NMH-WakeupAllowed" SG_ 1729 NMH_MO_Start_2 0;
BA_ "GenSigAutoGenDsp" SG_ 1729 NMH_MO_Normal_Mode_1 1;
BA_ "GenSigAutoGenSnd" SG_ 1729 NMH_MO_Normal_Mode_1 1;
BA_ "GenSigEnvVarType" SG_ 1729 NMH_MO_Normal_Mode_1 0;
BA_ "GenSigSendType" SG_ 1729 NMH_MO_Normal_Mode_1 7;
BA_ "NWM-WakeupAllowed" SG_ 1729 NMH_MO_Normal_Mode_1 0;
BA_ "NMH-WakeupAllowed" SG_ 1729 NMH_MO_Normal_Mode_1 0;
BA_ "GenSigAutoGenDsp" SG_ 1729 NMH_MO_Normal_Mode_2 1;
BA_ "GenSigAutoGenSnd" SG_ 1729 NMH_MO_Normal_Mode_2 1;
BA_ "GenSigEnvVarType" SG_ 1729 NMH_MO_Normal_Mode_2 0;
BA_ "GenSigSendType" SG_ 1729 NMH_MO_Normal_Mode_2 7;
BA_ "NWM-WakeupAllowed" SG_ 1729 NMH_MO_Normal_Mode_2 0;
BA_ "NMH-WakeupAllowed" SG_ 1729 NMH_MO_Normal_Mode_2 0;
BA_ "GenSigAutoGenDsp" SG_ 1729 NMH_MO_Car_WakeUp 1;
BA_ "GenSigAutoGenSnd" SG_ 1729 NMH_MO_Car_WakeUp 1;
BA_ "GenSigEnvVarType" SG_ 1729 NMH_MO_Car_WakeUp 0;
BA_ "GenSigSendType" SG_ 1729 NMH_MO_Car_WakeUp 7;
BA_ "NWM-WakeupAllowed" SG_ 1729 NMH_MO_Car_WakeUp 0;
BA_ "NMH-WakeupAllowed" SG_ 1729 NMH_MO_Car_WakeUp 0;
BA_ "GenSigTimeoutMsg_Gateway_B8" SG_ 1729 NMH_MO_Car_WakeUp 1729;
BA_ "GenSigAutoGenDsp" SG_ 1729 NMH_MO_Per_WakeUp 1;
BA_ "GenSigAutoGenSnd" SG_ 1729 NMH_MO_Per_WakeUp 1;
BA_ "GenSigEnvVarType" SG_ 1729 NMH_MO_Per_WakeUp 0;
BA_ "GenSigSendType" SG_ 1729 NMH_MO_Per_WakeUp 7;
BA_ "NWM-WakeupAllowed" SG_ 1729 NMH_MO_Per_WakeUp 1;
BA_ "NMH-WakeupAllowed" SG_ 1729 NMH_MO_Per_WakeUp 0;
BA_ "GenSigAutoGenDsp" SG_ 1729 NMH_MO_Fkt_WakeUp 1;
BA_ "GenSigAutoGenSnd" SG_ 1729 NMH_MO_Fkt_WakeUp 1;
BA_ "GenSigEnvVarType" SG_ 1729 NMH_MO_Fkt_WakeUp 0;
BA_ "GenSigSendType" SG_ 1729 NMH_MO_Fkt_WakeUp 7;
BA_ "NWM-WakeupAllowed" SG_ 1729 NMH_MO_Fkt_WakeUp 1;
BA_ "NMH-WakeupAllowed" SG_ 1729 NMH_MO_Fkt_WakeUp 0;
BA_ "GenSigAutoGenDsp" SG_ 1729 NMH_MO_NM_aktiv_Klemme_15 1;
BA_ "GenSigAutoGenSnd" SG_ 1729 NMH_MO_NM_aktiv_Klemme_15 1;
BA_ "GenSigEnvVarType" SG_ 1729 NMH_MO_NM_aktiv_Klemme_15 0;
BA_ "GenSigSendType" SG_ 1729 NMH_MO_NM_aktiv_Klemme_15 7;
BA_ "NWM-WakeupAllowed" SG_ 1729 NMH_MO_NM_aktiv_Klemme_15 0;
BA_ "NMH-WakeupAllowed" SG_ 1729 NMH_MO_NM_aktiv_Klemme_15 0;
BA_ "GenSigAutoGenDsp" SG_ 1729 NMH_MO_NM_aktiv_Diagnose 1;
BA_ "GenSigAutoGenSnd" SG_ 1729 NMH_MO_NM_aktiv_Diagnose 1;
BA_ "GenSigEnvVarType" SG_ 1729 NMH_MO_NM_aktiv_Diagnose 0;
BA_ "GenSigSendType" SG_ 1729 NMH_MO_NM_aktiv_Diagnose 7;
BA_ "NWM-WakeupAllowed" SG_ 1729 NMH_MO_NM_aktiv_Diagnose 0;
BA_ "NMH-WakeupAllowed" SG_ 1729 NMH_MO_NM_aktiv_Diagnose 0;
BA_ "GenSigAutoGenDsp" SG_ 1729 NMH_MO_NM_aktiv_Start 1;
BA_ "GenSigAutoGenSnd" SG_ 1729 NMH_MO_NM_aktiv_Start 1;
BA_ "GenSigEnvVarType" SG_ 1729 NMH_MO_NM_aktiv_Start 0;
BA_ "GenSigSendType" SG_ 1729 NMH_MO_NM_aktiv_Start 7;
BA_ "NWM-WakeupAllowed" SG_ 1729 NMH_MO_NM_aktiv_Start 0;
BA_ "NMH-WakeupAllowed" SG_ 1729 NMH_MO_NM_aktiv_Start 0;
BA_ "GenSigAutoGenDsp" SG_ 1729 NMH_MO_NM_aktiv_EKP_Vorlauf 1;
BA_ "GenSigAutoGenSnd" SG_ 1729 NMH_MO_NM_aktiv_EKP_Vorlauf 1;
BA_ "GenSigEnvVarType" SG_ 1729 NMH_MO_NM_aktiv_EKP_Vorlauf 0;
BA_ "GenSigSendType" SG_ 1729 NMH_MO_NM_aktiv_EKP_Vorlauf 7;
BA_ "NWM-WakeupAllowed" SG_ 1729 NMH_MO_NM_aktiv_EKP_Vorlauf 0;
BA_ "NMH-WakeupAllowed" SG_ 1729 NMH_MO_NM_aktiv_EKP_Vorlauf 0;
BA_ "GenSigAutoGenDsp" SG_ 1729 NMH_MO_NM_aktiv_STH_Betrieb 1;
BA_ "GenSigAutoGenSnd" SG_ 1729 NMH_MO_NM_aktiv_STH_Betrieb 1;
BA_ "GenSigEnvVarType" SG_ 1729 NMH_MO_NM_aktiv_STH_Betrieb 0;
BA_ "GenSigSendType" SG_ 1729 NMH_MO_NM_aktiv_STH_Betrieb 7;
BA_ "NWM-WakeupAllowed" SG_ 1729 NMH_MO_NM_aktiv_STH_Betrieb 0;
BA_ "NMH-WakeupAllowed" SG_ 1729 NMH_MO_NM_aktiv_STH_Betrieb 0;
BA_ "GenSigAutoGenDsp" SG_ 1729 NMH_MO_kein_NL 1;
BA_ "GenSigAutoGenSnd" SG_ 1729 NMH_MO_kein_NL 1;
BA_ "GenSigSendType" SG_ 1729 NMH_MO_kein_NL 7;
BA_ "NWM-WakeupAllowed" SG_ 1729 NMH_MO_kein_NL 0;
BA_ "NMH-WakeupAllowed" SG_ 1729 NMH_MO_kein_NL 0;
BA_ "GenSigAutoGenDsp" SG_ 1729 NMH_MO_NL_Kuehlerluefter 1;
BA_ "GenSigAutoGenSnd" SG_ 1729 NMH_MO_NL_Kuehlerluefter 1;
BA_ "GenSigSendType" SG_ 1729 NMH_MO_NL_Kuehlerluefter 7;
BA_ "NWM-WakeupAllowed" SG_ 1729 NMH_MO_NL_Kuehlerluefter 0;
BA_ "NMH-WakeupAllowed" SG_ 1729 NMH_MO_NL_Kuehlerluefter 0;
BA_ "GenSigAutoGenDsp" SG_ 1729 NMH_MO_NL_Diagnose 1;
BA_ "GenSigAutoGenSnd" SG_ 1729 NMH_MO_NL_Diagnose 1;
BA_ "GenSigSendType" SG_ 1729 NMH_MO_NL_Diagnose 7;
BA_ "NWM-WakeupAllowed" SG_ 1729 NMH_MO_NL_Diagnose 0;
BA_ "NMH-WakeupAllowed" SG_ 1729 NMH_MO_NL_Diagnose 0;
BA_ "GenSigAutoGenDsp" SG_ 1729 NMH_MO_NL_WFS 1;
BA_ "GenSigAutoGenSnd" SG_ 1729 NMH_MO_NL_WFS 1;
BA_ "GenSigSendType" SG_ 1729 NMH_MO_NL_WFS 7;
BA_ "NWM-WakeupAllowed" SG_ 1729 NMH_MO_NL_WFS 0;
BA_ "NMH-WakeupAllowed" SG_ 1729 NMH_MO_NL_WFS 0;
BA_ "GenSigAutoGenDsp" SG_ 1729 NMH_MO_NL_EEPROM 1;
BA_ "GenSigAutoGenSnd" SG_ 1729 NMH_MO_NL_EEPROM 1;
BA_ "GenSigSendType" SG_ 1729 NMH_MO_NL_EEPROM 7;
BA_ "NWM-WakeupAllowed" SG_ 1729 NMH_MO_NL_EEPROM 0;
BA_ "NMH-WakeupAllowed" SG_ 1729 NMH_MO_NL_EEPROM 0;
BA_ "GenSigAutoGenDsp" SG_ 1729 NMH_MO_NL_Sonstige 1;
BA_ "GenSigAutoGenSnd" SG_ 1729 NMH_MO_NL_Sonstige 1;
BA_ "GenSigSendType" SG_ 1729 NMH_MO_NL_Sonstige 7;
BA_ "NWM-WakeupAllowed" SG_ 1729 NMH_MO_NL_Sonstige 0;
BA_ "NMH-WakeupAllowed" SG_ 1729 NMH_MO_NL_Sonstige 0;
BA_ "GenSigAutoGenDsp" SG_ 1729 NMH_MO_TimeOut_Fehler 1;
BA_ "GenSigAutoGenSnd" SG_ 1729 NMH_MO_TimeOut_Fehler 1;
BA_ "GenSigEnvVarType" SG_ 1729 NMH_MO_TimeOut_Fehler 0;
BA_ "GenSigSendType" SG_ 1729 NMH_MO_TimeOut_Fehler 7;
BA_ "NWM-WakeupAllowed" SG_ 1729 NMH_MO_TimeOut_Fehler 0;
BA_ "NMH-WakeupAllowed" SG_ 1729 NMH_MO_TimeOut_Fehler 0;
BA_ "GenSigAutoGenDsp" SG_ 1729 NMH_MO_CAN_Diag_deaktiv 1;
BA_ "GenSigAutoGenSnd" SG_ 1729 NMH_MO_CAN_Diag_deaktiv 1;
BA_ "GenSigEnvVarType" SG_ 1729 NMH_MO_CAN_Diag_deaktiv 0;
BA_ "GenSigSendType" SG_ 1729 NMH_MO_CAN_Diag_deaktiv 7;
BA_ "NWM-WakeupAllowed" SG_ 1729 NMH_MO_CAN_Diag_deaktiv 0;
BA_ "NMH-WakeupAllowed" SG_ 1729 NMH_MO_CAN_Diag_deaktiv 0;
BA_ "GenSigAutoGenDsp" SG_ 1729 NMH_MO_KompSchutz 1;
BA_ "GenSigAutoGenSnd" SG_ 1729 NMH_MO_KompSchutz 1;
BA_ "GenSigEnvVarType" SG_ 1729 NMH_MO_KompSchutz 0;
BA_ "GenSigSendType" SG_ 1729 NMH_MO_KompSchutz 7;
BA_ "NWM-WakeupAllowed" SG_ 1729 NMH_MO_KompSchutz 0;
BA_ "NMH-WakeupAllowed" SG_ 1729 NMH_MO_KompSchutz 0;
BA_ "GenSigAutoGenDsp" SG_ 1729 NMH_MO_Mute_Mode 1;
BA_ "GenSigAutoGenSnd" SG_ 1729 NMH_MO_Mute_Mode 1;
BA_ "GenSigEnvVarType" SG_ 1729 NMH_MO_Mute_Mode 0;
BA_ "GenSigSendType" SG_ 1729 NMH_MO_Mute_Mode 7;
BA_ "NWM-WakeupAllowed" SG_ 1729 NMH_MO_Mute_Mode 0;
BA_ "NMH-WakeupAllowed" SG_ 1729 NMH_MO_Mute_Mode 0;
BA_ "GenSigAutoGenDsp" SG_ 1729 NMH_MO_Transport_Mode 1;
BA_ "GenSigAutoGenSnd" SG_ 1729 NMH_MO_Transport_Mode 1;
BA_ "GenSigEnvVarType" SG_ 1729 NMH_MO_Transport_Mode 0;
BA_ "GenSigSendType" SG_ 1729 NMH_MO_Transport_Mode 7;
BA_ "NWM-WakeupAllowed" SG_ 1729 NMH_MO_Transport_Mode 0;
BA_ "NMH-WakeupAllowed" SG_ 1729 NMH_MO_Transport_Mode 0;
BA_ "GenSigAutoGenDsp" SG_ 1729 NMH_MO_Abschaltstufe_aktiv 1;
BA_ "GenSigAutoGenSnd" SG_ 1729 NMH_MO_Abschaltstufe_aktiv 1;
BA_ "GenSigEnvVarType" SG_ 1729 NMH_MO_Abschaltstufe_aktiv 0;
BA_ "GenSigSendType" SG_ 1729 NMH_MO_Abschaltstufe_aktiv 7;
BA_ "NWM-WakeupAllowed" SG_ 1729 NMH_MO_Abschaltstufe_aktiv 0;
BA_ "NMH-WakeupAllowed" SG_ 1729 NMH_MO_Abschaltstufe_aktiv 0;
BA_ "GenSigAutoGenDsp" SG_ 1729 NMH_MO_Eindraht_Fehler 1;
BA_ "GenSigAutoGenSnd" SG_ 1729 NMH_MO_Eindraht_Fehler 1;
BA_ "GenSigEnvVarType" SG_ 1729 NMH_MO_Eindraht_Fehler 0;
BA_ "GenSigSendType" SG_ 1729 NMH_MO_Eindraht_Fehler 7;
BA_ "NWM-WakeupAllowed" SG_ 1729 NMH_MO_Eindraht_Fehler 0;
BA_ "NMH-WakeupAllowed" SG_ 1729 NMH_MO_Eindraht_Fehler 0;
BA_ "GenSigAutoGenDsp" SG_ 913 OBD_Calc_Load_Val 1;
BA_ "GenSigAutoGenSnd" SG_ 913 OBD_Calc_Load_Val 1;
BA_ "GenSigEnvVarType" SG_ 913 OBD_Calc_Load_Val 1;
BA_ "GenSigSendType" SG_ 913 OBD_Calc_Load_Val 7;
BA_ "NWM-WakeupAllowed" SG_ 913 OBD_Calc_Load_Val 0;
BA_ "NMH-WakeupAllowed" SG_ 913 OBD_Calc_Load_Val 0;
BA_ "GenSigTimeoutMsg_Getriebe_AL6000" SG_ 913 OBD_Calc_Load_Val 913;
BA_ "GenSigTimeoutMsg_Getriebe_DL5001" SG_ 913 OBD_Calc_Load_Val 913;
BA_ "GenSigTimeoutMsg_Getriebe_VL3002" SG_ 913 OBD_Calc_Load_Val 913;
BA_ "GenSigAutoGenDsp" SG_ 913 OBD_Eng_Cool_Temp 1;
BA_ "GenSigAutoGenSnd" SG_ 913 OBD_Eng_Cool_Temp 1;
BA_ "GenSigEnvVarType" SG_ 913 OBD_Eng_Cool_Temp 1;
BA_ "GenSigSendType" SG_ 913 OBD_Eng_Cool_Temp 7;
BA_ "NWM-WakeupAllowed" SG_ 913 OBD_Eng_Cool_Temp 0;
BA_ "NMH-WakeupAllowed" SG_ 913 OBD_Eng_Cool_Temp 0;
BA_ "GenSigTimeoutMsg_Getriebe_AL6000" SG_ 913 OBD_Eng_Cool_Temp 913;
BA_ "GenSigTimeoutMsg_Getriebe_DL5001" SG_ 913 OBD_Eng_Cool_Temp 913;
BA_ "GenSigTimeoutMsg_Getriebe_VL3002" SG_ 913 OBD_Eng_Cool_Temp 913;
BA_ "GenSigAutoGenDsp" SG_ 913 OBD_Abs_Throttle_Pos 1;
BA_ "GenSigAutoGenSnd" SG_ 913 OBD_Abs_Throttle_Pos 1;
BA_ "GenSigEnvVarType" SG_ 913 OBD_Abs_Throttle_Pos 0;
BA_ "GenSigSendType" SG_ 913 OBD_Abs_Throttle_Pos 7;
BA_ "NWM-WakeupAllowed" SG_ 913 OBD_Abs_Throttle_Pos 0;
BA_ "NMH-WakeupAllowed" SG_ 913 OBD_Abs_Throttle_Pos 0;
BA_ "GenSigTimeoutMsg_Getriebe_AL6000" SG_ 913 OBD_Abs_Throttle_Pos 913;
BA_ "GenSigTimeoutMsg_Getriebe_DL5001" SG_ 913 OBD_Abs_Throttle_Pos 913;
BA_ "GenSigTimeoutMsg_Getriebe_VL3002" SG_ 913 OBD_Abs_Throttle_Pos 913;
BA_ "GenSigAutoGenDsp" SG_ 913 OBD_Abs_Load_Val 1;
BA_ "GenSigAutoGenSnd" SG_ 913 OBD_Abs_Load_Val 1;
BA_ "GenSigEnvVarType" SG_ 913 OBD_Abs_Load_Val 0;
BA_ "GenSigSendType" SG_ 913 OBD_Abs_Load_Val 7;
BA_ "NWM-WakeupAllowed" SG_ 913 OBD_Abs_Load_Val 0;
BA_ "NMH-WakeupAllowed" SG_ 913 OBD_Abs_Load_Val 0;
BA_ "GenSigTimeoutMsg_Getriebe_AL6000" SG_ 913 OBD_Abs_Load_Val 913;
BA_ "GenSigTimeoutMsg_Getriebe_DL5001" SG_ 913 OBD_Abs_Load_Val 913;
BA_ "GenSigTimeoutMsg_Getriebe_VL3002" SG_ 913 OBD_Abs_Load_Val 913;
BA_ "GenSigAutoGenDsp" SG_ 913 OBD_Abs_Pedal_Pos 1;
BA_ "GenSigAutoGenSnd" SG_ 913 OBD_Abs_Pedal_Pos 1;
BA_ "GenSigEnvVarType" SG_ 913 OBD_Abs_Pedal_Pos 0;
BA_ "GenSigSendType" SG_ 913 OBD_Abs_Pedal_Pos 7;
BA_ "NWM-WakeupAllowed" SG_ 913 OBD_Abs_Pedal_Pos 0;
BA_ "NMH-WakeupAllowed" SG_ 913 OBD_Abs_Pedal_Pos 0;
BA_ "GenSigTimeoutMsg_Getriebe_AL6000" SG_ 913 OBD_Abs_Pedal_Pos 913;
BA_ "GenSigTimeoutMsg_Getriebe_DL5001" SG_ 913 OBD_Abs_Pedal_Pos 913;
BA_ "GenSigTimeoutMsg_Getriebe_VL3002" SG_ 913 OBD_Abs_Pedal_Pos 913;
BA_ "GenSigAutoGenDsp" SG_ 913 OBD_Driving_Cycle 1;
BA_ "GenSigAutoGenSnd" SG_ 913 OBD_Driving_Cycle 1;
BA_ "GenSigEnvVarType" SG_ 913 OBD_Driving_Cycle 0;
BA_ "GenSigSendType" SG_ 913 OBD_Driving_Cycle 7;
BA_ "NWM-WakeupAllowed" SG_ 913 OBD_Driving_Cycle 0;
BA_ "NMH-WakeupAllowed" SG_ 913 OBD_Driving_Cycle 0;
BA_ "GenSigTimeoutMsg_Getriebe_AL6000" SG_ 913 OBD_Driving_Cycle 913;
BA_ "GenSigTimeoutMsg_Getriebe_DL5001" SG_ 913 OBD_Driving_Cycle 913;
BA_ "GenSigTimeoutMsg_Getriebe_VL3002" SG_ 913 OBD_Driving_Cycle 913;
BA_ "GenSigAutoGenDsp" SG_ 913 OBD_Warm_Up_Cycle 1;
BA_ "GenSigAutoGenSnd" SG_ 913 OBD_Warm_Up_Cycle 1;
BA_ "GenSigEnvVarType" SG_ 913 OBD_Warm_Up_Cycle 0;
BA_ "GenSigSendType" SG_ 913 OBD_Warm_Up_Cycle 7;
BA_ "NWM-WakeupAllowed" SG_ 913 OBD_Warm_Up_Cycle 0;
BA_ "NMH-WakeupAllowed" SG_ 913 OBD_Warm_Up_Cycle 0;
BA_ "GenSigTimeoutMsg_Gateway_B8" SG_ 913 OBD_Warm_Up_Cycle 913;
BA_ "GenSigTimeoutMsg_Getriebe_AL6000" SG_ 913 OBD_Warm_Up_Cycle 913;
BA_ "GenSigTimeoutMsg_Getriebe_DL5001" SG_ 913 OBD_Warm_Up_Cycle 913;
BA_ "GenSigTimeoutMsg_Getriebe_VL3002" SG_ 913 OBD_Warm_Up_Cycle 913;
BA_ "GenSigAutoGenDsp" SG_ 913 OBD_Normed_Trip 1;
BA_ "GenSigAutoGenSnd" SG_ 913 OBD_Normed_Trip 1;
BA_ "GenSigEnvVarType" SG_ 913 OBD_Normed_Trip 0;
BA_ "GenSigSendType" SG_ 913 OBD_Normed_Trip 7;
BA_ "NWM-WakeupAllowed" SG_ 913 OBD_Normed_Trip 0;
BA_ "NMH-WakeupAllowed" SG_ 913 OBD_Normed_Trip 0;
BA_ "GenSigTimeoutMsg_Getriebe_AL6000" SG_ 913 OBD_Normed_Trip 913;
BA_ "GenSigTimeoutMsg_Getriebe_DL5001" SG_ 913 OBD_Normed_Trip 913;
BA_ "GenSigTimeoutMsg_Getriebe_VL3002" SG_ 913 OBD_Normed_Trip 913;
BA_ "GenSigAutoGenDsp" SG_ 1630 OBD_TG_F_Status_1 1;
BA_ "GenSigAutoGenSnd" SG_ 1630 OBD_TG_F_Status_1 1;
BA_ "GenSigSendType" SG_ 1630 OBD_TG_F_Status_1 7;
BA_ "NWM-WakeupAllowed" SG_ 1630 OBD_TG_F_Status_1 0;
BA_ "NMH-WakeupAllowed" SG_ 1630 OBD_TG_F_Status_1 0;
BA_ "GenSigTimeoutMsg_Motor_EDC17_003" SG_ 1630 OBD_TG_F_Status_1 1630;
BA_ "GenSigTimeoutMsg_Motor_EDC17_004" SG_ 1630 OBD_TG_F_Status_1 1630;
BA_ "GenSigTimeoutMsg_Motor_MED17_B8" SG_ 1630 OBD_TG_F_Status_1 1630;
BA_ "GenSigTimeoutMsg_Motor_MED9_B8" SG_ 1630 OBD_TG_F_Status_1 1630;
BA_ "GenSigTimeoutMsg_Motor_SIMOS8_B8" SG_ 1630 OBD_TG_F_Status_1 1630;
BA_ "GenSigAutoGenDsp" SG_ 1630 OBD_TG_F_Status_2 1;
BA_ "GenSigAutoGenSnd" SG_ 1630 OBD_TG_F_Status_2 1;
BA_ "GenSigSendType" SG_ 1630 OBD_TG_F_Status_2 7;
BA_ "NWM-WakeupAllowed" SG_ 1630 OBD_TG_F_Status_2 0;
BA_ "NMH-WakeupAllowed" SG_ 1630 OBD_TG_F_Status_2 0;
BA_ "GenSigTimeoutMsg_Motor_EDC17_003" SG_ 1630 OBD_TG_F_Status_2 1630;
BA_ "GenSigTimeoutMsg_Motor_EDC17_004" SG_ 1630 OBD_TG_F_Status_2 1630;
BA_ "GenSigTimeoutMsg_Motor_MED17_B8" SG_ 1630 OBD_TG_F_Status_2 1630;
BA_ "GenSigTimeoutMsg_Motor_MED9_B8" SG_ 1630 OBD_TG_F_Status_2 1630;
BA_ "GenSigTimeoutMsg_Motor_SIMOS8_B8" SG_ 1630 OBD_TG_F_Status_2 1630;
BA_ "GenSigAutoGenDsp" SG_ 1630 OBD_TG_F_Status_3 1;
BA_ "GenSigAutoGenSnd" SG_ 1630 OBD_TG_F_Status_3 1;
BA_ "GenSigSendType" SG_ 1630 OBD_TG_F_Status_3 7;
BA_ "NWM-WakeupAllowed" SG_ 1630 OBD_TG_F_Status_3 0;
BA_ "NMH-WakeupAllowed" SG_ 1630 OBD_TG_F_Status_3 0;
BA_ "GenSigTimeoutMsg_Motor_EDC17_003" SG_ 1630 OBD_TG_F_Status_3 1630;
BA_ "GenSigTimeoutMsg_Motor_EDC17_004" SG_ 1630 OBD_TG_F_Status_3 1630;
BA_ "GenSigTimeoutMsg_Motor_MED17_B8" SG_ 1630 OBD_TG_F_Status_3 1630;
BA_ "GenSigTimeoutMsg_Motor_MED9_B8" SG_ 1630 OBD_TG_F_Status_3 1630;
BA_ "GenSigTimeoutMsg_Motor_SIMOS8_B8" SG_ 1630 OBD_TG_F_Status_3 1630;
BA_ "GenSigAutoGenDsp" SG_ 1630 OBD_TG_F_Status_4 1;
BA_ "GenSigAutoGenSnd" SG_ 1630 OBD_TG_F_Status_4 1;
BA_ "GenSigSendType" SG_ 1630 OBD_TG_F_Status_4 7;
BA_ "NWM-WakeupAllowed" SG_ 1630 OBD_TG_F_Status_4 0;
BA_ "NMH-WakeupAllowed" SG_ 1630 OBD_TG_F_Status_4 0;
BA_ "GenSigTimeoutMsg_Motor_EDC17_003" SG_ 1630 OBD_TG_F_Status_4 1630;
BA_ "GenSigTimeoutMsg_Motor_EDC17_004" SG_ 1630 OBD_TG_F_Status_4 1630;
BA_ "GenSigTimeoutMsg_Motor_MED17_B8" SG_ 1630 OBD_TG_F_Status_4 1630;
BA_ "GenSigTimeoutMsg_Motor_MED9_B8" SG_ 1630 OBD_TG_F_Status_4 1630;
BA_ "GenSigTimeoutMsg_Motor_SIMOS8_B8" SG_ 1630 OBD_TG_F_Status_4 1630;
BA_ "GenSigAutoGenDsp" SG_ 1630 OBD_TG_Sens_Rohwert_1 1;
BA_ "GenSigAutoGenSnd" SG_ 1630 OBD_TG_Sens_Rohwert_1 1;
BA_ "GenSigSendType" SG_ 1630 OBD_TG_Sens_Rohwert_1 7;
BA_ "NWM-WakeupAllowed" SG_ 1630 OBD_TG_Sens_Rohwert_1 0;
BA_ "NMH-WakeupAllowed" SG_ 1630 OBD_TG_Sens_Rohwert_1 0;
BA_ "GenSigTimeoutMsg_Motor_EDC17_003" SG_ 1630 OBD_TG_Sens_Rohwert_1 1630;
BA_ "GenSigTimeoutMsg_Motor_EDC17_004" SG_ 1630 OBD_TG_Sens_Rohwert_1 1630;
BA_ "GenSigTimeoutMsg_Motor_MED17_B8" SG_ 1630 OBD_TG_Sens_Rohwert_1 1630;
BA_ "GenSigTimeoutMsg_Motor_MED9_B8" SG_ 1630 OBD_TG_Sens_Rohwert_1 1630;
BA_ "GenSigTimeoutMsg_Motor_SIMOS8_B8" SG_ 1630 OBD_TG_Sens_Rohwert_1 1630;
BA_ "GenSigAutoGenDsp" SG_ 1630 OBD_TG_Sens_Rohwert_2 1;
BA_ "GenSigAutoGenSnd" SG_ 1630 OBD_TG_Sens_Rohwert_2 1;
BA_ "GenSigSendType" SG_ 1630 OBD_TG_Sens_Rohwert_2 7;
BA_ "NWM-WakeupAllowed" SG_ 1630 OBD_TG_Sens_Rohwert_2 0;
BA_ "NMH-WakeupAllowed" SG_ 1630 OBD_TG_Sens_Rohwert_2 0;
BA_ "GenSigTimeoutMsg_Motor_EDC17_003" SG_ 1630 OBD_TG_Sens_Rohwert_2 1630;
BA_ "GenSigTimeoutMsg_Motor_EDC17_004" SG_ 1630 OBD_TG_Sens_Rohwert_2 1630;
BA_ "GenSigTimeoutMsg_Motor_MED17_B8" SG_ 1630 OBD_TG_Sens_Rohwert_2 1630;
BA_ "GenSigTimeoutMsg_Motor_MED9_B8" SG_ 1630 OBD_TG_Sens_Rohwert_2 1630;
BA_ "GenSigTimeoutMsg_Motor_SIMOS8_B8" SG_ 1630 OBD_TG_Sens_Rohwert_2 1630;
BA_ "GenSigAutoGenDsp" SG_ 1630 OBD_TG_Sens_Rohwert_3 1;
BA_ "GenSigAutoGenSnd" SG_ 1630 OBD_TG_Sens_Rohwert_3 1;
BA_ "GenSigSendType" SG_ 1630 OBD_TG_Sens_Rohwert_3 7;
BA_ "NWM-WakeupAllowed" SG_ 1630 OBD_TG_Sens_Rohwert_3 0;
BA_ "NMH-WakeupAllowed" SG_ 1630 OBD_TG_Sens_Rohwert_3 0;
BA_ "GenSigTimeoutMsg_Motor_EDC17_003" SG_ 1630 OBD_TG_Sens_Rohwert_3 1630;
BA_ "GenSigTimeoutMsg_Motor_EDC17_004" SG_ 1630 OBD_TG_Sens_Rohwert_3 1630;
BA_ "GenSigTimeoutMsg_Motor_MED17_B8" SG_ 1630 OBD_TG_Sens_Rohwert_3 1630;
BA_ "GenSigTimeoutMsg_Motor_MED9_B8" SG_ 1630 OBD_TG_Sens_Rohwert_3 1630;
BA_ "GenSigTimeoutMsg_Motor_SIMOS8_B8" SG_ 1630 OBD_TG_Sens_Rohwert_3 1630;
BA_ "GenSigAutoGenDsp" SG_ 1630 OBD_TG_Sens_Rohwert_4 1;
BA_ "GenSigAutoGenSnd" SG_ 1630 OBD_TG_Sens_Rohwert_4 1;
BA_ "GenSigSendType" SG_ 1630 OBD_TG_Sens_Rohwert_4 7;
BA_ "NWM-WakeupAllowed" SG_ 1630 OBD_TG_Sens_Rohwert_4 0;
BA_ "NMH-WakeupAllowed" SG_ 1630 OBD_TG_Sens_Rohwert_4 0;
BA_ "GenSigTimeoutMsg_Motor_EDC17_003" SG_ 1630 OBD_TG_Sens_Rohwert_4 1630;
BA_ "GenSigTimeoutMsg_Motor_EDC17_004" SG_ 1630 OBD_TG_Sens_Rohwert_4 1630;
BA_ "GenSigTimeoutMsg_Motor_MED17_B8" SG_ 1630 OBD_TG_Sens_Rohwert_4 1630;
BA_ "GenSigTimeoutMsg_Motor_MED9_B8" SG_ 1630 OBD_TG_Sens_Rohwert_4 1630;
BA_ "GenSigTimeoutMsg_Motor_SIMOS8_B8" SG_ 1630 OBD_TG_Sens_Rohwert_4 1630;
BA_ "SystemSignalLongSymbol" SG_ 1526 SCR_Steuergeraet_Codierung_Statu "SCR_Steuergeraet_Codierung_Status";
BA_ "SystemSignalLongSymbol" SG_ 1526 SCR_Steuergeraet_Datensatz_Statu "SCR_Steuergeraet_Datensatz_Status";
BA_ "GenSigAutoGenDsp" SG_ 133 SCU_01_CHK 1;
BA_ "GenSigAutoGenSnd" SG_ 133 SCU_01_CHK 1;
BA_ "GenSigEnvVarType" SG_ 133 SCU_01_CHK 0;
BA_ "GenSigSendType" SG_ 133 SCU_01_CHK 7;
BA_ "NWM-WakeupAllowed" SG_ 133 SCU_01_CHK 0;
BA_ "NMH-WakeupAllowed" SG_ 133 SCU_01_CHK 0;
BA_ "GenSigTimeoutMsg_Daempfer_B8" SG_ 133 SCU_01_CHK 133;
BA_ "GenSigTimeoutMsg_Motor_EDC17_003" SG_ 133 SCU_01_CHK 133;
BA_ "GenSigTimeoutMsg_Motor_EDC17_004" SG_ 133 SCU_01_CHK 133;
BA_ "GenSigTimeoutMsg_Motor_MED17_B8" SG_ 133 SCU_01_CHK 133;
BA_ "GenSigTimeoutMsg_Motor_MED9_B8" SG_ 133 SCU_01_CHK 133;
BA_ "GenSigTimeoutMsg_Motor_SIMOS8_B8" SG_ 133 SCU_01_CHK 133;
BA_ "GenSigAutoGenDsp" SG_ 133 SCU_01_BZ 1;
BA_ "GenSigAutoGenSnd" SG_ 133 SCU_01_BZ 1;
BA_ "GenSigEnvVarType" SG_ 133 SCU_01_BZ 0;
BA_ "GenSigSendType" SG_ 133 SCU_01_BZ 7;
BA_ "NWM-WakeupAllowed" SG_ 133 SCU_01_BZ 0;
BA_ "NMH-WakeupAllowed" SG_ 133 SCU_01_BZ 0;
BA_ "GenSigTimeoutMsg_Daempfer_B8" SG_ 133 SCU_01_BZ 133;
BA_ "GenSigTimeoutMsg_Motor_EDC17_003" SG_ 133 SCU_01_BZ 133;
BA_ "GenSigTimeoutMsg_Motor_EDC17_004" SG_ 133 SCU_01_BZ 133;
BA_ "GenSigTimeoutMsg_Motor_MED17_B8" SG_ 133 SCU_01_BZ 133;
BA_ "GenSigTimeoutMsg_Motor_MED9_B8" SG_ 133 SCU_01_BZ 133;
BA_ "GenSigTimeoutMsg_Motor_SIMOS8_B8" SG_ 133 SCU_01_BZ 133;
BA_ "GenSigAutoGenDsp" SG_ 133 SCU_Ue_Winkel_ADS 1;
BA_ "GenSigAutoGenSnd" SG_ 133 SCU_Ue_Winkel_ADS 1;
BA_ "GenSigEnvVarType" SG_ 133 SCU_Ue_Winkel_ADS 1;
BA_ "GenSigSendType" SG_ 133 SCU_Ue_Winkel_ADS 7;
BA_ "GenSigStartValue" SG_ 133 SCU_Ue_Winkel_ADS 4094;
BA_ "NWM-WakeupAllowed" SG_ 133 SCU_Ue_Winkel_ADS 0;
BA_ "NMH-WakeupAllowed" SG_ 133 SCU_Ue_Winkel_ADS 0;
BA_ "GenSigTimeoutMsg_AFS_B8" SG_ 133 SCU_Ue_Winkel_ADS 133;
BA_ "GenSigTimeoutMsg_Daempfer_B8" SG_ 133 SCU_Ue_Winkel_ADS 133;
BA_ "GenSigTimeoutMsg_Motor_EDC17_003" SG_ 133 SCU_Ue_Winkel_ADS 133;
BA_ "GenSigTimeoutMsg_Motor_EDC17_004" SG_ 133 SCU_Ue_Winkel_ADS 133;
BA_ "GenSigTimeoutMsg_Motor_MED17_B8" SG_ 133 SCU_Ue_Winkel_ADS 133;
BA_ "GenSigTimeoutMsg_Motor_MED9_B8" SG_ 133 SCU_Ue_Winkel_ADS 133;
BA_ "GenSigTimeoutMsg_Motor_SIMOS8_B8" SG_ 133 SCU_Ue_Winkel_ADS 133;
BA_ "GenSigAutoGenDsp" SG_ 133 SCU_VZ_Ue_Winkel_ADS 1;
BA_ "GenSigAutoGenSnd" SG_ 133 SCU_VZ_Ue_Winkel_ADS 1;
BA_ "GenSigEnvVarType" SG_ 133 SCU_VZ_Ue_Winkel_ADS 0;
BA_ "GenSigSendType" SG_ 133 SCU_VZ_Ue_Winkel_ADS 7;
BA_ "NWM-WakeupAllowed" SG_ 133 SCU_VZ_Ue_Winkel_ADS 0;
BA_ "NMH-WakeupAllowed" SG_ 133 SCU_VZ_Ue_Winkel_ADS 0;
BA_ "GenSigTimeoutMsg_AFS_B8" SG_ 133 SCU_VZ_Ue_Winkel_ADS 133;
BA_ "GenSigTimeoutMsg_Daempfer_B8" SG_ 133 SCU_VZ_Ue_Winkel_ADS 133;
BA_ "GenSigTimeoutMsg_Motor_EDC17_003" SG_ 133 SCU_VZ_Ue_Winkel_ADS 133;
BA_ "GenSigTimeoutMsg_Motor_EDC17_004" SG_ 133 SCU_VZ_Ue_Winkel_ADS 133;
BA_ "GenSigTimeoutMsg_Motor_MED17_B8" SG_ 133 SCU_VZ_Ue_Winkel_ADS 133;
BA_ "GenSigTimeoutMsg_Motor_MED9_B8" SG_ 133 SCU_VZ_Ue_Winkel_ADS 133;
BA_ "GenSigTimeoutMsg_Motor_SIMOS8_B8" SG_ 133 SCU_VZ_Ue_Winkel_ADS 133;
BA_ "GenSigAutoGenDsp" SG_ 133 SCU_Soll_Ue_Winkel 1;
BA_ "GenSigAutoGenSnd" SG_ 133 SCU_Soll_Ue_Winkel 1;
BA_ "GenSigEnvVarType" SG_ 133 SCU_Soll_Ue_Winkel 1;
BA_ "GenSigSendType" SG_ 133 SCU_Soll_Ue_Winkel 7;
BA_ "GenSigStartValue" SG_ 133 SCU_Soll_Ue_Winkel 2046;
BA_ "NWM-WakeupAllowed" SG_ 133 SCU_Soll_Ue_Winkel 0;
BA_ "NMH-WakeupAllowed" SG_ 133 SCU_Soll_Ue_Winkel 0;
BA_ "GenSigTimeoutMsg_AFS_B8" SG_ 133 SCU_Soll_Ue_Winkel 133;
BA_ "GenSigAutoGenDsp" SG_ 133 SCU_max_Gradient 1;
BA_ "GenSigAutoGenSnd" SG_ 133 SCU_max_Gradient 1;
BA_ "GenSigEnvVarType" SG_ 133 SCU_max_Gradient 0;
BA_ "GenSigSendType" SG_ 133 SCU_max_Gradient 7;
BA_ "NWM-WakeupAllowed" SG_ 133 SCU_max_Gradient 0;
BA_ "NMH-WakeupAllowed" SG_ 133 SCU_max_Gradient 0;
BA_ "GenSigAutoGenDsp" SG_ 133 SCU_VZ_Soll_Ue_Winkel 1;
BA_ "GenSigAutoGenSnd" SG_ 133 SCU_VZ_Soll_Ue_Winkel 1;
BA_ "GenSigEnvVarType" SG_ 133 SCU_VZ_Soll_Ue_Winkel 0;
BA_ "GenSigSendType" SG_ 133 SCU_VZ_Soll_Ue_Winkel 7;
BA_ "NWM-WakeupAllowed" SG_ 133 SCU_VZ_Soll_Ue_Winkel 0;
BA_ "NMH-WakeupAllowed" SG_ 133 SCU_VZ_Soll_Ue_Winkel 0;
BA_ "GenSigTimeoutMsg_AFS_B8" SG_ 133 SCU_VZ_Soll_Ue_Winkel 133;
BA_ "GenSigAutoGenDsp" SG_ 133 SCU_Status 1;
BA_ "GenSigAutoGenSnd" SG_ 133 SCU_Status 1;
BA_ "GenSigEnvVarType" SG_ 133 SCU_Status 0;
BA_ "GenSigSendType" SG_ 133 SCU_Status 7;
BA_ "GenSigStartValue" SG_ 133 SCU_Status 1;
BA_ "NWM-WakeupAllowed" SG_ 133 SCU_Status 0;
BA_ "NMH-WakeupAllowed" SG_ 133 SCU_Status 0;
BA_ "GenSigTimeoutMsg_AFS_B8" SG_ 133 SCU_Status 133;
BA_ "GenSigTimeoutMsg_Daempfer_B8" SG_ 133 SCU_Status 133;
BA_ "GenSigTimeoutMsg_Motor_EDC17_003" SG_ 133 SCU_Status 133;
BA_ "GenSigTimeoutMsg_Motor_EDC17_004" SG_ 133 SCU_Status 133;
BA_ "GenSigTimeoutMsg_Motor_MED17_B8" SG_ 133 SCU_Status 133;
BA_ "GenSigTimeoutMsg_Motor_MED9_B8" SG_ 133 SCU_Status 133;
BA_ "GenSigTimeoutMsg_Motor_SIMOS8_B8" SG_ 133 SCU_Status 133;
BA_ "GenSigAutoGenDsp" SG_ 133 SCU_KD_Fehler 1;
BA_ "GenSigAutoGenSnd" SG_ 133 SCU_KD_Fehler 1;
BA_ "GenSigEnvVarType" SG_ 133 SCU_KD_Fehler 0;
BA_ "GenSigSendType" SG_ 133 SCU_KD_Fehler 7;
BA_ "NWM-WakeupAllowed" SG_ 133 SCU_KD_Fehler 0;
BA_ "NMH-WakeupAllowed" SG_ 133 SCU_KD_Fehler 0;
BA_ "GenSigAutoGenDsp" SG_ 133 SCU_01_CRC 1;
BA_ "GenSigAutoGenSnd" SG_ 133 SCU_01_CRC 1;
BA_ "GenSigSendType" SG_ 133 SCU_01_CRC 7;
BA_ "NWM-WakeupAllowed" SG_ 133 SCU_01_CRC 0;
BA_ "NMH-WakeupAllowed" SG_ 133 SCU_01_CRC 0;
BA_ "GenSigAutoGenDsp" SG_ 1313 STH_Funk_ein 1;
BA_ "GenSigAutoGenSnd" SG_ 1313 STH_Funk_ein 1;
BA_ "GenSigEnvVarType" SG_ 1313 STH_Funk_ein 0;
BA_ "GenSigSendType" SG_ 1313 STH_Funk_ein 7;
BA_ "NWM-WakeupAllowed" SG_ 1313 STH_Funk_ein 0;
BA_ "NMH-WakeupAllowed" SG_ 1313 STH_Funk_ein 0;
BA_ "GenSigAutoGenDsp" SG_ 1313 STH_Funk_aus 1;
BA_ "GenSigAutoGenSnd" SG_ 1313 STH_Funk_aus 1;
BA_ "GenSigEnvVarType" SG_ 1313 STH_Funk_aus 0;
BA_ "GenSigSendType" SG_ 1313 STH_Funk_aus 7;
BA_ "NWM-WakeupAllowed" SG_ 1313 STH_Funk_aus 0;
BA_ "NMH-WakeupAllowed" SG_ 1313 STH_Funk_aus 0;
BA_ "GenSigAutoGenDsp" SG_ 1313 STH_Zusatzheizung 1;
BA_ "GenSigAutoGenSnd" SG_ 1313 STH_Zusatzheizung 1;
BA_ "GenSigEnvVarType" SG_ 1313 STH_Zusatzheizung 0;
BA_ "GenSigSendType" SG_ 1313 STH_Zusatzheizung 7;
BA_ "NWM-WakeupAllowed" SG_ 1313 STH_Zusatzheizung 0;
BA_ "NMH-WakeupAllowed" SG_ 1313 STH_Zusatzheizung 0;
BA_ "GenSigAutoGenDsp" SG_ 1313 STH_LED 1;
BA_ "GenSigAutoGenSnd" SG_ 1313 STH_LED 1;
BA_ "GenSigEnvVarType" SG_ 1313 STH_LED 0;
BA_ "GenSigSendType" SG_ 1313 STH_LED 7;
BA_ "NWM-WakeupAllowed" SG_ 1313 STH_LED 0;
BA_ "NMH-WakeupAllowed" SG_ 1313 STH_LED 0;
BA_ "GenSigAutoGenDsp" SG_ 1313 STH_Pumpe_ein 1;
BA_ "GenSigAutoGenSnd" SG_ 1313 STH_Pumpe_ein 1;
BA_ "GenSigEnvVarType" SG_ 1313 STH_Pumpe_ein 0;
BA_ "GenSigSendType" SG_ 1313 STH_Pumpe_ein 7;
BA_ "NWM-WakeupAllowed" SG_ 1313 STH_Pumpe_ein 0;
BA_ "NMH-WakeupAllowed" SG_ 1313 STH_Pumpe_ein 0;
BA_ "GenSigAutoGenDsp" SG_ 1313 STH_Geblaese 1;
BA_ "GenSigAutoGenSnd" SG_ 1313 STH_Geblaese 1;
BA_ "GenSigEnvVarType" SG_ 1313 STH_Geblaese 0;
BA_ "GenSigSendType" SG_ 1313 STH_Geblaese 7;
BA_ "NWM-WakeupAllowed" SG_ 1313 STH_Geblaese 0;
BA_ "NMH-WakeupAllowed" SG_ 1313 STH_Geblaese 0;
BA_ "GenSigAutoGenDsp" SG_ 1313 STH_EKP_Anst 1;
BA_ "GenSigAutoGenSnd" SG_ 1313 STH_EKP_Anst 1;
BA_ "GenSigEnvVarType" SG_ 1313 STH_EKP_Anst 0;
BA_ "GenSigSendType" SG_ 1313 STH_EKP_Anst 7;
BA_ "NWM-WakeupAllowed" SG_ 1313 STH_EKP_Anst 0;
BA_ "NMH-WakeupAllowed" SG_ 1313 STH_EKP_Anst 0;
BA_ "GenSigTimeoutMsg_Motor_EDC17_003" SG_ 1313 STH_EKP_Anst 1313;
BA_ "GenSigTimeoutMsg_Motor_EDC17_004" SG_ 1313 STH_EKP_Anst 1313;
BA_ "GenSigTimeoutMsg_Motor_MED17_B8" SG_ 1313 STH_EKP_Anst 1313;
BA_ "GenSigTimeoutMsg_Motor_SIMOS8_B8" SG_ 1313 STH_EKP_Anst 1313;
BA_ "GenSigAutoGenDsp" SG_ 1313 STH_Ventiloeffnungszeit 1;
BA_ "GenSigAutoGenSnd" SG_ 1313 STH_Ventiloeffnungszeit 1;
BA_ "GenSigSendType" SG_ 1313 STH_Ventiloeffnungszeit 7;
BA_ "NWM-WakeupAllowed" SG_ 1313 STH_Ventiloeffnungszeit 0;
BA_ "NMH-WakeupAllowed" SG_ 1313 STH_Ventiloeffnungszeit 0;
BA_ "GenSigTimeoutMsg_Motor_EDC17_003" SG_ 1313 STH_Ventiloeffnungszeit 1313;
BA_ "GenSigTimeoutMsg_Motor_EDC17_004" SG_ 1313 STH_Ventiloeffnungszeit 1313;
BA_ "GenSigTimeoutMsg_Motor_MED17_B8" SG_ 1313 STH_Ventiloeffnungszeit 1313;
BA_ "GenSigTimeoutMsg_Motor_SIMOS8_B8" SG_ 1313 STH_Ventiloeffnungszeit 1313;
BA_ "GenSigAutoGenDsp" SG_ 1313 STH_Waermeeintrag 1;
BA_ "GenSigAutoGenSnd" SG_ 1313 STH_Waermeeintrag 1;
BA_ "GenSigEnvVarType" SG_ 1313 STH_Waermeeintrag 1;
BA_ "GenSigSendType" SG_ 1313 STH_Waermeeintrag 7;
BA_ "NWM-WakeupAllowed" SG_ 1313 STH_Waermeeintrag 0;
BA_ "NMH-WakeupAllowed" SG_ 1313 STH_Waermeeintrag 0;
BA_ "GenSigTimeoutMsg_Motor_EDC17_003" SG_ 1313 STH_Waermeeintrag 1313;
BA_ "GenSigTimeoutMsg_Motor_EDC17_004" SG_ 1313 STH_Waermeeintrag 1313;
BA_ "GenSigTimeoutMsg_Motor_MED17_B8" SG_ 1313 STH_Waermeeintrag 1313;
BA_ "GenSigTimeoutMsg_Motor_SIMOS8_B8" SG_ 1313 STH_Waermeeintrag 1313;
BA_ "GenSigAutoGenDsp" SG_ 1313 STH_KVS 1;
BA_ "GenSigAutoGenSnd" SG_ 1313 STH_KVS 1;
BA_ "GenSigEnvVarType" SG_ 1313 STH_KVS 1;
BA_ "GenSigSendType" SG_ 1313 STH_KVS 7;
BA_ "NWM-WakeupAllowed" SG_ 1313 STH_KVS 0;
BA_ "NMH-WakeupAllowed" SG_ 1313 STH_KVS 0;
BA_ "GenSigAutoGenDsp" SG_ 1313 STH_Fehlerstatus 1;
BA_ "GenSigAutoGenSnd" SG_ 1313 STH_Fehlerstatus 1;
BA_ "GenSigEnvVarType" SG_ 1313 STH_Fehlerstatus 0;
BA_ "GenSigSendType" SG_ 1313 STH_Fehlerstatus 7;
BA_ "NWM-WakeupAllowed" SG_ 1313 STH_Fehlerstatus 0;
BA_ "NMH-WakeupAllowed" SG_ 1313 STH_Fehlerstatus 0;
BA_ "GenSigAutoGenDsp" SG_ 1313 STH_Heizleistung 1;
BA_ "GenSigAutoGenSnd" SG_ 1313 STH_Heizleistung 1;
BA_ "GenSigEnvVarType" SG_ 1313 STH_Heizleistung 1;
BA_ "GenSigSendType" SG_ 1313 STH_Heizleistung 7;
BA_ "NWM-WakeupAllowed" SG_ 1313 STH_Heizleistung 0;
BA_ "NMH-WakeupAllowed" SG_ 1313 STH_Heizleistung 0;
BA_ "GenSigAutoGenDsp" SG_ 1313 STH_Wassertemp 1;
BA_ "GenSigAutoGenSnd" SG_ 1313 STH_Wassertemp 1;
BA_ "GenSigEnvVarType" SG_ 1313 STH_Wassertemp 1;
BA_ "GenSigSendType" SG_ 1313 STH_Wassertemp 7;
BA_ "GenSigStartValue" SG_ 1313 STH_Wassertemp 254;
BA_ "NWM-WakeupAllowed" SG_ 1313 STH_Wassertemp 0;
BA_ "NMH-WakeupAllowed" SG_ 1313 STH_Wassertemp 0;
BA_ "GenSigAutoGenDsp" SG_ 1313 STH_Motorvorwaermung 1;
BA_ "GenSigAutoGenSnd" SG_ 1313 STH_Motorvorwaermung 1;
BA_ "GenSigSendType" SG_ 1313 STH_Motorvorwaermung 7;
BA_ "NWM-WakeupAllowed" SG_ 1313 STH_Motorvorwaermung 0;
BA_ "NMH-WakeupAllowed" SG_ 1313 STH_Motorvorwaermung 0;
BA_ "GenSigTimeoutMsg_Motor_EDC17_003" SG_ 1313 STH_Motorvorwaermung 1313;
BA_ "GenSigTimeoutMsg_Motor_EDC17_004" SG_ 1313 STH_Motorvorwaermung 1313;
BA_ "GenSigTimeoutMsg_Motor_MED17_B8" SG_ 1313 STH_Motorvorwaermung 1313;
BA_ "GenSigTimeoutMsg_Motor_SIMOS8_B8" SG_ 1313 STH_Motorvorwaermung 1313;
BA_ "GenSigAutoGenDsp" SG_ 1313 STH_Servicemode 1;
BA_ "GenSigAutoGenSnd" SG_ 1313 STH_Servicemode 1;
BA_ "GenSigEnvVarType" SG_ 1313 STH_Servicemode 0;
BA_ "GenSigSendType" SG_ 1313 STH_Servicemode 7;
BA_ "NWM-WakeupAllowed" SG_ 1313 STH_Servicemode 0;
BA_ "NMH-WakeupAllowed" SG_ 1313 STH_Servicemode 0;
BA_ "GenSigAutoGenDsp" SG_ 1313 STH_war_aktiv 1;
BA_ "GenSigAutoGenSnd" SG_ 1313 STH_war_aktiv 1;
BA_ "GenSigEnvVarType" SG_ 1313 STH_war_aktiv 0;
BA_ "GenSigSendType" SG_ 1313 STH_war_aktiv 7;
BA_ "NWM-WakeupAllowed" SG_ 1313 STH_war_aktiv 0;
BA_ "NMH-WakeupAllowed" SG_ 1313 STH_war_aktiv 0;
BA_ "GenSigTimeoutMsg_Motor_EDC17_003" SG_ 1313 STH_war_aktiv 1313;
BA_ "GenSigTimeoutMsg_Motor_EDC17_004" SG_ 1313 STH_war_aktiv 1313;
BA_ "GenSigTimeoutMsg_Motor_MED17_B8" SG_ 1313 STH_war_aktiv 1313;
BA_ "GenSigTimeoutMsg_Motor_SIMOS8_B8" SG_ 1313 STH_war_aktiv 1313;
BA_ "GenSigAutoGenDsp" SG_ 1313 STH_KVS_Ueberlauf 1;
BA_ "GenSigAutoGenSnd" SG_ 1313 STH_KVS_Ueberlauf 1;
BA_ "GenSigEnvVarType" SG_ 1313 STH_KVS_Ueberlauf 0;
BA_ "GenSigSendType" SG_ 1313 STH_KVS_Ueberlauf 7;
BA_ "NWM-WakeupAllowed" SG_ 1313 STH_KVS_Ueberlauf 0;
BA_ "NMH-WakeupAllowed" SG_ 1313 STH_KVS_Ueberlauf 0;
BA_ "GenSigAutoGenDsp" SG_ 1313 STH_KD_Fehler 1;
BA_ "GenSigAutoGenSnd" SG_ 1313 STH_KD_Fehler 1;
BA_ "GenSigEnvVarType" SG_ 1313 STH_KD_Fehler 0;
BA_ "GenSigSendType" SG_ 1313 STH_KD_Fehler 7;
BA_ "NWM-WakeupAllowed" SG_ 1313 STH_KD_Fehler 0;
BA_ "NMH-WakeupAllowed" SG_ 1313 STH_KD_Fehler 0;
BA_ "GenSigAutoGenDsp" SG_ 1413 SI_Int_CAN_gespiegelt 1;
BA_ "GenSigAutoGenSnd" SG_ 1413 SI_Int_CAN_gespiegelt 1;
BA_ "GenSigSendType" SG_ 1413 SI_Int_CAN_gespiegelt 7;
BA_ "NWM-WakeupAllowed" SG_ 1413 SI_Int_CAN_gespiegelt 0;
BA_ "NMH-WakeupAllowed" SG_ 1413 SI_Int_CAN_gespiegelt 0;
BA_ "GenSigAutoGenDsp" SG_ 1413 SI_CAN_Antrieb_Sleep 1;
BA_ "GenSigAutoGenSnd" SG_ 1413 SI_CAN_Antrieb_Sleep 1;
BA_ "GenSigSendType" SG_ 1413 SI_CAN_Antrieb_Sleep 3;
BA_ "GenSigStartValue" SG_ 1413 SI_CAN_Antrieb_Sleep 1;
BA_ "NWM-WakeupAllowed" SG_ 1413 SI_CAN_Antrieb_Sleep 0;
BA_ "NMH-WakeupAllowed" SG_ 1413 SI_CAN_Antrieb_Sleep 0;
BA_ "GenSigAutoGenDsp" SG_ 1300 TPD_Airbag_Data_2 1;
BA_ "GenSigAutoGenSnd" SG_ 1300 TPD_Airbag_Data_2 1;
BA_ "GenSigSendType" SG_ 1300 TPD_Airbag_Data_2 7;
BA_ "NWM-WakeupAllowed" SG_ 1300 TPD_Airbag_Data_2 0;
BA_ "NMH-WakeupAllowed" SG_ 1300 TPD_Airbag_Data_2 0;
BA_ "GenSigTimeoutMsg_Airbag_B8" SG_ 1300 TPD_Airbag_Data_2 1300;
BA_ "GenSigAutoGenDsp" SG_ 1196 TPD_Daempfer_Data_1 1;
BA_ "GenSigAutoGenSnd" SG_ 1196 TPD_Daempfer_Data_1 1;
BA_ "GenSigSendType" SG_ 1196 TPD_Daempfer_Data_1 7;
BA_ "NWM-WakeupAllowed" SG_ 1196 TPD_Daempfer_Data_1 0;
BA_ "NMH-WakeupAllowed" SG_ 1196 TPD_Daempfer_Data_1 0;
BA_ "GenSigTimeoutMsg_Daempfer_B8" SG_ 1196 TPD_Daempfer_Data_1 1196;
BA_ "GenSigAutoGenDsp" SG_ 1215 TPD_Gateway_Data_1 0;
BA_ "GenSigAutoGenSnd" SG_ 1215 TPD_Gateway_Data_1 0;
BA_ "GenSigSendType" SG_ 1215 TPD_Gateway_Data_1 7;
BA_ "NWM-WakeupAllowed" SG_ 1215 TPD_Gateway_Data_1 0;
BA_ "NMH-WakeupAllowed" SG_ 1215 TPD_Gateway_Data_1 0;
BA_ "GenSigTimeoutMsg_Gateway_B8" SG_ 1215 TPD_Gateway_Data_1 1215;
BA_ "GenSigAutoGenDsp" SG_ 1303 TPD_Gateway_Data_2 0;
BA_ "GenSigAutoGenSnd" SG_ 1303 TPD_Gateway_Data_2 0;
BA_ "GenSigSendType" SG_ 1303 TPD_Gateway_Data_2 7;
BA_ "NWM-WakeupAllowed" SG_ 1303 TPD_Gateway_Data_2 0;
BA_ "NMH-WakeupAllowed" SG_ 1303 TPD_Gateway_Data_2 0;
BA_ "GenSigTimeoutMsg_Gateway_B8" SG_ 1303 TPD_Gateway_Data_2 1303;
BA_ "GenSigAutoGenDsp" SG_ 1186 TPD_Getriebe_Data_1 1;
BA_ "GenSigAutoGenSnd" SG_ 1186 TPD_Getriebe_Data_1 1;
BA_ "GenSigSendType" SG_ 1186 TPD_Getriebe_Data_1 7;
BA_ "NWM-WakeupAllowed" SG_ 1186 TPD_Getriebe_Data_1 0;
BA_ "NMH-WakeupAllowed" SG_ 1186 TPD_Getriebe_Data_1 0;
BA_ "GenSigTimeoutMsg_Getriebe_AL6000" SG_ 1186 TPD_Getriebe_Data_1 1186;
BA_ "GenSigTimeoutMsg_Getriebe_DL5001" SG_ 1186 TPD_Getriebe_Data_1 1186;
BA_ "GenSigTimeoutMsg_Getriebe_VL3002" SG_ 1186 TPD_Getriebe_Data_1 1186;
BA_ "GenSigAutoGenDsp" SG_ 1190 TPD_LWR_AFS_Data_1 1;
BA_ "GenSigAutoGenSnd" SG_ 1190 TPD_LWR_AFS_Data_1 1;
BA_ "GenSigSendType" SG_ 1190 TPD_LWR_AFS_Data_1 7;
BA_ "NWM-WakeupAllowed" SG_ 1190 TPD_LWR_AFS_Data_1 0;
BA_ "NMH-WakeupAllowed" SG_ 1190 TPD_LWR_AFS_Data_1 0;
BA_ "GenSigTimeoutMsg_AFS_B8" SG_ 1190 TPD_LWR_AFS_Data_1 1190;
BA_ "GenSigTimeoutMsg_LWR_B8" SG_ 1190 TPD_LWR_AFS_Data_1 1190;
BA_ "GenSigAutoGenDsp" SG_ 1185 TPD_Motor_Data_1 1;
BA_ "GenSigAutoGenSnd" SG_ 1185 TPD_Motor_Data_1 1;
BA_ "GenSigSendType" SG_ 1185 TPD_Motor_Data_1 7;
BA_ "NWM-WakeupAllowed" SG_ 1185 TPD_Motor_Data_1 0;
BA_ "NMH-WakeupAllowed" SG_ 1185 TPD_Motor_Data_1 0;
BA_ "GenSigTimeoutMsg_Motor_EDC17_003" SG_ 1185 TPD_Motor_Data_1 1185;
BA_ "GenSigTimeoutMsg_Motor_EDC17_004" SG_ 1185 TPD_Motor_Data_1 1185;
BA_ "GenSigTimeoutMsg_Motor_MED17_B8" SG_ 1185 TPD_Motor_Data_1 1185;
BA_ "GenSigTimeoutMsg_Motor_MED9_B8" SG_ 1185 TPD_Motor_Data_1 1185;
BA_ "GenSigTimeoutMsg_Motor_SIMOS8_B8" SG_ 1185 TPD_Motor_Data_1 1185;
BA_ "GenSigAutoGenDsp" SG_ 1205 TPD_MotorS_Data_1 1;
BA_ "GenSigAutoGenSnd" SG_ 1205 TPD_MotorS_Data_1 1;
BA_ "GenSigSendType" SG_ 1205 TPD_MotorS_Data_1 7;
BA_ "NWM-WakeupAllowed" SG_ 1205 TPD_MotorS_Data_1 0;
BA_ "NMH-WakeupAllowed" SG_ 1205 TPD_MotorS_Data_1 0;
BA_ "GenSigTimeoutMsg_Motor_Slave_B8" SG_ 1205 TPD_MotorS_Data_1 1205;
BA_ "GenSigAutoGenDsp" SG_ 768 TPD_Tester_Data_1 0;
BA_ "GenSigAutoGenSnd" SG_ 768 TPD_Tester_Data_1 0;
BA_ "GenSigSendType" SG_ 768 TPD_Tester_Data_1 7;
BA_ "NWM-WakeupAllowed" SG_ 768 TPD_Tester_Data_1 0;
BA_ "NMH-WakeupAllowed" SG_ 768 TPD_Tester_Data_1 0;
BA_ "GenSigTimeoutMsg_Gateway_B8" SG_ 768 TPD_Tester_Data_1 768;
BA_ "GenSigAutoGenDsp" SG_ 769 TPD_Tester_Data_2 0;
BA_ "GenSigAutoGenSnd" SG_ 769 TPD_Tester_Data_2 0;
BA_ "GenSigSendType" SG_ 769 TPD_Tester_Data_2 7;
BA_ "NWM-WakeupAllowed" SG_ 769 TPD_Tester_Data_2 0;
BA_ "NMH-WakeupAllowed" SG_ 769 TPD_Tester_Data_2 0;
BA_ "GenSigTimeoutMsg_Gateway_B8" SG_ 769 TPD_Tester_Data_2 769;
BA_ "GenSigAutoGenDsp" SG_ 770 TPD_Tester_Data_3 0;
BA_ "GenSigAutoGenSnd" SG_ 770 TPD_Tester_Data_3 0;
BA_ "GenSigSendType" SG_ 770 TPD_Tester_Data_3 7;
BA_ "NWM-WakeupAllowed" SG_ 770 TPD_Tester_Data_3 0;
BA_ "NMH-WakeupAllowed" SG_ 770 TPD_Tester_Data_3 0;
BA_ "GenSigTimeoutMsg_Gateway_B8" SG_ 770 TPD_Tester_Data_3 770;
BA_ "GenSigAutoGenDsp" SG_ 771 TPD_Tester_Data_4 0;
BA_ "GenSigAutoGenSnd" SG_ 771 TPD_Tester_Data_4 0;
BA_ "GenSigSendType" SG_ 771 TPD_Tester_Data_4 7;
BA_ "NWM-WakeupAllowed" SG_ 771 TPD_Tester_Data_4 0;
BA_ "NMH-WakeupAllowed" SG_ 771 TPD_Tester_Data_4 0;
BA_ "GenSigTimeoutMsg_Gateway_B8" SG_ 771 TPD_Tester_Data_4 771;
BA_ "GenSigAutoGenDsp" SG_ 772 TPD_Tester_Data_5 0;
BA_ "GenSigAutoGenSnd" SG_ 772 TPD_Tester_Data_5 0;
BA_ "GenSigSendType" SG_ 772 TPD_Tester_Data_5 7;
BA_ "NWM-WakeupAllowed" SG_ 772 TPD_Tester_Data_5 0;
BA_ "NMH-WakeupAllowed" SG_ 772 TPD_Tester_Data_5 0;
BA_ "GenSigTimeoutMsg_Gateway_B8" SG_ 772 TPD_Tester_Data_5 772;
BA_ "GenSigAutoGenDsp" SG_ 773 TPD_Tester_Data_6 0;
BA_ "GenSigAutoGenSnd" SG_ 773 TPD_Tester_Data_6 0;
BA_ "GenSigSendType" SG_ 773 TPD_Tester_Data_6 7;
BA_ "NWM-WakeupAllowed" SG_ 773 TPD_Tester_Data_6 0;
BA_ "NMH-WakeupAllowed" SG_ 773 TPD_Tester_Data_6 0;
BA_ "GenSigTimeoutMsg_Gateway_B8" SG_ 773 TPD_Tester_Data_6 773;
BA_ "GenSigAutoGenDsp" SG_ 774 TPD_Tester_Data_7 0;
BA_ "GenSigAutoGenSnd" SG_ 774 TPD_Tester_Data_7 0;
BA_ "GenSigSendType" SG_ 774 TPD_Tester_Data_7 7;
BA_ "NWM-WakeupAllowed" SG_ 774 TPD_Tester_Data_7 0;
BA_ "NMH-WakeupAllowed" SG_ 774 TPD_Tester_Data_7 0;
BA_ "GenSigTimeoutMsg_Gateway_B8" SG_ 774 TPD_Tester_Data_7 774;
BA_ "GenSigAutoGenDsp" SG_ 775 TPD_Tester_Data_8 0;
BA_ "GenSigAutoGenSnd" SG_ 775 TPD_Tester_Data_8 0;
BA_ "GenSigSendType" SG_ 775 TPD_Tester_Data_8 7;
BA_ "NWM-WakeupAllowed" SG_ 775 TPD_Tester_Data_8 0;
BA_ "NMH-WakeupAllowed" SG_ 775 TPD_Tester_Data_8 0;
BA_ "GenSigTimeoutMsg_Gateway_B8" SG_ 775 TPD_Tester_Data_8 775;
BA_ "GenSigAutoGenDsp" SG_ 517 TPS_Airbag_Data 1;
BA_ "GenSigAutoGenSnd" SG_ 517 TPS_Airbag_Data 1;
BA_ "GenSigSendType" SG_ 517 TPS_Airbag_Data 7;
BA_ "NWM-WakeupAllowed" SG_ 517 TPS_Airbag_Data 0;
BA_ "NMH-WakeupAllowed" SG_ 517 TPS_Airbag_Data 0;
BA_ "GenSigTimeoutMsg_Gateway_B8" SG_ 517 TPS_Airbag_Data 517;
BA_ "GenSigAutoGenDsp" SG_ 524 TPS_Daempfer_Data 1;
BA_ "GenSigAutoGenSnd" SG_ 524 TPS_Daempfer_Data 1;
BA_ "GenSigSendType" SG_ 524 TPS_Daempfer_Data 7;
BA_ "NWM-WakeupAllowed" SG_ 524 TPS_Daempfer_Data 0;
BA_ "NMH-WakeupAllowed" SG_ 524 TPS_Daempfer_Data 0;
BA_ "GenSigTimeoutMsg_Gateway_B8" SG_ 524 TPS_Daempfer_Data 524;
BA_ "GenSigAutoGenDsp" SG_ 543 TPS_Gateway_Data 0;
BA_ "GenSigAutoGenSnd" SG_ 543 TPS_Gateway_Data 0;
BA_ "GenSigSendType" SG_ 543 TPS_Gateway_Data 7;
BA_ "NWM-WakeupAllowed" SG_ 543 TPS_Gateway_Data 0;
BA_ "NMH-WakeupAllowed" SG_ 543 TPS_Gateway_Data 0;
BA_ "GenSigTimeoutMsg_Airbag_B8" SG_ 543 TPS_Gateway_Data 543;
BA_ "GenSigAutoGenDsp" SG_ 514 TPS_Getriebe_Data 1;
BA_ "GenSigAutoGenSnd" SG_ 514 TPS_Getriebe_Data 1;
BA_ "GenSigSendType" SG_ 514 TPS_Getriebe_Data 7;
BA_ "NWM-WakeupAllowed" SG_ 514 TPS_Getriebe_Data 0;
BA_ "NMH-WakeupAllowed" SG_ 514 TPS_Getriebe_Data 0;
BA_ "GenSigTimeoutMsg_Gateway_B8" SG_ 514 TPS_Getriebe_Data 514;
BA_ "GenSigAutoGenDsp" SG_ 518 TPS_LWR_AFS_Data 1;
BA_ "GenSigAutoGenSnd" SG_ 518 TPS_LWR_AFS_Data 1;
BA_ "GenSigSendType" SG_ 518 TPS_LWR_AFS_Data 7;
BA_ "NWM-WakeupAllowed" SG_ 518 TPS_LWR_AFS_Data 0;
BA_ "NMH-WakeupAllowed" SG_ 518 TPS_LWR_AFS_Data 0;
BA_ "GenSigTimeoutMsg_Gateway_B8" SG_ 518 TPS_LWR_AFS_Data 518;
BA_ "GenSigAutoGenDsp" SG_ 513 TPS_Motor_Data 1;
BA_ "GenSigAutoGenSnd" SG_ 513 TPS_Motor_Data 1;
BA_ "GenSigSendType" SG_ 513 TPS_Motor_Data 7;
BA_ "NWM-WakeupAllowed" SG_ 513 TPS_Motor_Data 0;
BA_ "NMH-WakeupAllowed" SG_ 513 TPS_Motor_Data 0;
BA_ "GenSigTimeoutMsg_Gateway_B8" SG_ 513 TPS_Motor_Data 513;
BA_ "GenSigAutoGenDsp" SG_ 533 TPS_MotorS_Data 1;
BA_ "GenSigAutoGenSnd" SG_ 533 TPS_MotorS_Data 1;
BA_ "GenSigSendType" SG_ 533 TPS_MotorS_Data 7;
BA_ "NWM-WakeupAllowed" SG_ 533 TPS_MotorS_Data 0;
BA_ "NMH-WakeupAllowed" SG_ 533 TPS_MotorS_Data 0;
BA_ "GenSigTimeoutMsg_Gateway_B8" SG_ 533 TPS_MotorS_Data 533;
BA_ "GenSigAutoGenDsp" SG_ 512 TPS_Tester_Data 1;
BA_ "GenSigAutoGenSnd" SG_ 512 TPS_Tester_Data 1;
BA_ "GenSigSendType" SG_ 512 TPS_Tester_Data 7;
BA_ "NWM-WakeupAllowed" SG_ 512 TPS_Tester_Data 0;
BA_ "NMH-WakeupAllowed" SG_ 512 TPS_Tester_Data 0;
BA_ "GenSigTimeoutMsg_AFS_B8" SG_ 512 TPS_Tester_Data 512;
BA_ "GenSigTimeoutMsg_Airbag_B8" SG_ 512 TPS_Tester_Data 512;
BA_ "GenSigTimeoutMsg_Daempfer_B8" SG_ 512 TPS_Tester_Data 512;
BA_ "GenSigTimeoutMsg_Getriebe_AL6000" SG_ 512 TPS_Tester_Data 512;
BA_ "GenSigTimeoutMsg_Getriebe_DL5001" SG_ 512 TPS_Tester_Data 512;
BA_ "GenSigTimeoutMsg_Getriebe_VL3002" SG_ 512 TPS_Tester_Data 512;
BA_ "GenSigTimeoutMsg_LWR_B8" SG_ 512 TPS_Tester_Data 512;
BA_ "GenSigTimeoutMsg_Motor_EDC17_003" SG_ 512 TPS_Tester_Data 512;
BA_ "GenSigTimeoutMsg_Motor_EDC17_004" SG_ 512 TPS_Tester_Data 512;
BA_ "GenSigTimeoutMsg_Motor_MED17_B8" SG_ 512 TPS_Tester_Data 512;
BA_ "GenSigTimeoutMsg_Motor_MED9_B8" SG_ 512 TPS_Tester_Data 512;
BA_ "GenSigTimeoutMsg_Motor_SIMOS8_B8" SG_ 512 TPS_Tester_Data 512;
BA_ "GenSigTimeoutMsg_Motor_Slave_B8" SG_ 512 TPS_Tester_Data 512;
BA_ "GenSigAutoGenDsp" SG_ 266 TSK_01_CHK 1;
BA_ "GenSigAutoGenSnd" SG_ 266 TSK_01_CHK 1;
BA_ "GenSigSendType" SG_ 266 TSK_01_CHK 7;
BA_ "NWM-WakeupAllowed" SG_ 266 TSK_01_CHK 0;
BA_ "NMH-WakeupAllowed" SG_ 266 TSK_01_CHK 0;
BA_ "GenSigTimeoutMsg_Gateway_B8" SG_ 266 TSK_01_CHK 266;
BA_ "GenSigTimeoutMsg_Getriebe_AL6000" SG_ 266 TSK_01_CHK 266;
BA_ "GenSigTimeoutMsg_Getriebe_DL5001" SG_ 266 TSK_01_CHK 266;
BA_ "GenSigTimeoutMsg_Getriebe_VL3002" SG_ 266 TSK_01_CHK 266;
BA_ "GenSigAutoGenDsp" SG_ 266 TSK_01_BZ 1;
BA_ "GenSigAutoGenSnd" SG_ 266 TSK_01_BZ 1;
BA_ "GenSigSendType" SG_ 266 TSK_01_BZ 7;
BA_ "NWM-WakeupAllowed" SG_ 266 TSK_01_BZ 0;
BA_ "NMH-WakeupAllowed" SG_ 266 TSK_01_BZ 0;
BA_ "GenSigTimeoutMsg_Gateway_B8" SG_ 266 TSK_01_BZ 266;
BA_ "GenSigTimeoutMsg_Getriebe_AL6000" SG_ 266 TSK_01_BZ 266;
BA_ "GenSigTimeoutMsg_Getriebe_DL5001" SG_ 266 TSK_01_BZ 266;
BA_ "GenSigTimeoutMsg_Getriebe_VL3002" SG_ 266 TSK_01_BZ 266;
BA_ "GenSigAutoGenDsp" SG_ 266 TSK_QBit_Steigung 1;
BA_ "GenSigAutoGenSnd" SG_ 266 TSK_QBit_Steigung 1;
BA_ "GenSigSendType" SG_ 266 TSK_QBit_Steigung 7;
BA_ "GenSigStartValue" SG_ 266 TSK_QBit_Steigung 1;
BA_ "NWM-WakeupAllowed" SG_ 266 TSK_QBit_Steigung 0;
BA_ "NMH-WakeupAllowed" SG_ 266 TSK_QBit_Steigung 0;
BA_ "GenSigTimeoutMsg_Gateway_B8" SG_ 266 TSK_QBit_Steigung 266;
BA_ "GenSigTimeoutMsg_Getriebe_AL6000" SG_ 266 TSK_QBit_Steigung 266;
BA_ "GenSigTimeoutMsg_Getriebe_DL5001" SG_ 266 TSK_QBit_Steigung 266;
BA_ "GenSigTimeoutMsg_Getriebe_VL3002" SG_ 266 TSK_QBit_Steigung 266;
BA_ "GenSigAutoGenDsp" SG_ 266 TSK_Status_AB 1;
BA_ "GenSigAutoGenSnd" SG_ 266 TSK_Status_AB 1;
BA_ "GenSigSendType" SG_ 266 TSK_Status_AB 7;
BA_ "NWM-WakeupAllowed" SG_ 266 TSK_Status_AB 0;
BA_ "NMH-WakeupAllowed" SG_ 266 TSK_Status_AB 0;
BA_ "GenSigTimeoutMsg_Gateway_B8" SG_ 266 TSK_Status_AB 266;
BA_ "GenSigAutoGenDsp" SG_ 266 TSK_Steigung 1;
BA_ "GenSigAutoGenSnd" SG_ 266 TSK_Steigung 1;
BA_ "GenSigSendType" SG_ 266 TSK_Steigung 7;
BA_ "NWM-WakeupAllowed" SG_ 266 TSK_Steigung 0;
BA_ "NMH-WakeupAllowed" SG_ 266 TSK_Steigung 0;
BA_ "GenSigTimeoutMsg_Gateway_B8" SG_ 266 TSK_Steigung 266;
BA_ "GenSigTimeoutMsg_Getriebe_AL6000" SG_ 266 TSK_Steigung 266;
BA_ "GenSigTimeoutMsg_Getriebe_DL5001" SG_ 266 TSK_Steigung 266;
BA_ "GenSigTimeoutMsg_Getriebe_VL3002" SG_ 266 TSK_Steigung 266;
BA_ "GenSigAutoGenDsp" SG_ 266 TSK_amax_moeglich 1;
BA_ "GenSigAutoGenSnd" SG_ 266 TSK_amax_moeglich 1;
BA_ "GenSigSendType" SG_ 266 TSK_amax_moeglich 7;
BA_ "GenSigStartValue" SG_ 266 TSK_amax_moeglich 84;
BA_ "NWM-WakeupAllowed" SG_ 266 TSK_amax_moeglich 0;
BA_ "NMH-WakeupAllowed" SG_ 266 TSK_amax_moeglich 0;
BA_ "GenSigTimeoutMsg_Gateway_B8" SG_ 266 TSK_amax_moeglich 266;
BA_ "GenSigAutoGenDsp" SG_ 266 TSK_Getriebeinfo 1;
BA_ "GenSigAutoGenSnd" SG_ 266 TSK_Getriebeinfo 1;
BA_ "GenSigSendType" SG_ 266 TSK_Getriebeinfo 7;
BA_ "NWM-WakeupAllowed" SG_ 266 TSK_Getriebeinfo 0;
BA_ "NMH-WakeupAllowed" SG_ 266 TSK_Getriebeinfo 0;
BA_ "GenSigTimeoutMsg_Gateway_B8" SG_ 266 TSK_Getriebeinfo 266;
BA_ "GenSigAutoGenDsp" SG_ 268 TSK_02_CHK 1;
BA_ "GenSigAutoGenSnd" SG_ 268 TSK_02_CHK 1;
BA_ "GenSigSendType" SG_ 268 TSK_02_CHK 7;
BA_ "NWM-WakeupAllowed" SG_ 268 TSK_02_CHK 0;
BA_ "NMH-WakeupAllowed" SG_ 268 TSK_02_CHK 0;
BA_ "GenSigTimeoutMsg_Daempfer_B8" SG_ 268 TSK_02_CHK 268;
BA_ "GenSigTimeoutMsg_Gateway_B8" SG_ 268 TSK_02_CHK 268;
BA_ "GenSigTimeoutMsg_Getriebe_AL6000" SG_ 268 TSK_02_CHK 268;
BA_ "GenSigTimeoutMsg_Getriebe_DL5001" SG_ 268 TSK_02_CHK 268;
BA_ "GenSigTimeoutMsg_Getriebe_VL3002" SG_ 268 TSK_02_CHK 268;
BA_ "GenSigAutoGenDsp" SG_ 268 TSK_02_BZ 1;
BA_ "GenSigAutoGenSnd" SG_ 268 TSK_02_BZ 1;
BA_ "GenSigSendType" SG_ 268 TSK_02_BZ 7;
BA_ "NWM-WakeupAllowed" SG_ 268 TSK_02_BZ 0;
BA_ "NMH-WakeupAllowed" SG_ 268 TSK_02_BZ 0;
BA_ "GenSigTimeoutMsg_Daempfer_B8" SG_ 268 TSK_02_BZ 268;
BA_ "GenSigTimeoutMsg_Gateway_B8" SG_ 268 TSK_02_BZ 268;
BA_ "GenSigTimeoutMsg_Getriebe_AL6000" SG_ 268 TSK_02_BZ 268;
BA_ "GenSigTimeoutMsg_Getriebe_DL5001" SG_ 268 TSK_02_BZ 268;
BA_ "GenSigTimeoutMsg_Getriebe_VL3002" SG_ 268 TSK_02_BZ 268;
BA_ "GenSigAutoGenDsp" SG_ 268 TSK_Anhalten 1;
BA_ "GenSigAutoGenSnd" SG_ 268 TSK_Anhalten 1;
BA_ "GenSigSendType" SG_ 268 TSK_Anhalten 7;
BA_ "NWM-WakeupAllowed" SG_ 268 TSK_Anhalten 0;
BA_ "NMH-WakeupAllowed" SG_ 268 TSK_Anhalten 0;
BA_ "GenSigTimeoutMsg_Gateway_B8" SG_ 268 TSK_Anhalten 268;
BA_ "GenSigAutoGenDsp" SG_ 268 TSK_Status_GRA_ACC_01 1;
BA_ "GenSigAutoGenSnd" SG_ 268 TSK_Status_GRA_ACC_01 1;
BA_ "GenSigEnvVarType" SG_ 268 TSK_Status_GRA_ACC_01 0;
BA_ "GenSigSendType" SG_ 268 TSK_Status_GRA_ACC_01 7;
BA_ "NWM-WakeupAllowed" SG_ 268 TSK_Status_GRA_ACC_01 0;
BA_ "NMH-WakeupAllowed" SG_ 268 TSK_Status_GRA_ACC_01 0;
BA_ "GenSigTimeoutMsg_Gateway_B8" SG_ 268 TSK_Status_GRA_ACC_01 268;
BA_ "GenSigAutoGenDsp" SG_ 268 TSK_Fahrzeugmasse 1;
BA_ "GenSigAutoGenSnd" SG_ 268 TSK_Fahrzeugmasse 1;
BA_ "GenSigSendType" SG_ 268 TSK_Fahrzeugmasse 7;
BA_ "NWM-WakeupAllowed" SG_ 268 TSK_Fahrzeugmasse 0;
BA_ "NMH-WakeupAllowed" SG_ 268 TSK_Fahrzeugmasse 0;
BA_ "GenSigTimeoutMsg_Gateway_B8" SG_ 268 TSK_Fahrzeugmasse 268;
BA_ "GenSigTimeoutMsg_Getriebe_AL6000" SG_ 268 TSK_Fahrzeugmasse 268;
BA_ "GenSigTimeoutMsg_Getriebe_DL5001" SG_ 268 TSK_Fahrzeugmasse 268;
BA_ "GenSigTimeoutMsg_Getriebe_VL3002" SG_ 268 TSK_Fahrzeugmasse 268;
BA_ "GenSigAutoGenDsp" SG_ 268 TSK_QBit_Fahrzeugmasse 1;
BA_ "GenSigAutoGenSnd" SG_ 268 TSK_QBit_Fahrzeugmasse 1;
BA_ "GenSigSendType" SG_ 268 TSK_QBit_Fahrzeugmasse 7;
BA_ "GenSigStartValue" SG_ 268 TSK_QBit_Fahrzeugmasse 1;
BA_ "NWM-WakeupAllowed" SG_ 268 TSK_QBit_Fahrzeugmasse 0;
BA_ "NMH-WakeupAllowed" SG_ 268 TSK_QBit_Fahrzeugmasse 0;
BA_ "GenSigTimeoutMsg_Gateway_B8" SG_ 268 TSK_QBit_Fahrzeugmasse 268;
BA_ "GenSigTimeoutMsg_Getriebe_AL6000" SG_ 268 TSK_QBit_Fahrzeugmasse 268;
BA_ "GenSigTimeoutMsg_Getriebe_DL5001" SG_ 268 TSK_QBit_Fahrzeugmasse 268;
BA_ "GenSigTimeoutMsg_Getriebe_VL3002" SG_ 268 TSK_QBit_Fahrzeugmasse 268;
BA_ "GenSigAutoGenDsp" SG_ 268 TSK_Radbremsmom 1;
BA_ "GenSigAutoGenSnd" SG_ 268 TSK_Radbremsmom 1;
BA_ "GenSigSendType" SG_ 268 TSK_Radbremsmom 7;
BA_ "NWM-WakeupAllowed" SG_ 268 TSK_Radbremsmom 0;
BA_ "NMH-WakeupAllowed" SG_ 268 TSK_Radbremsmom 0;
BA_ "GenSigTimeoutMsg_Gateway_B8" SG_ 268 TSK_Radbremsmom 268;
BA_ "GenSigAutoGenDsp" SG_ 268 TSK_Standby_Anf_ESP 1;
BA_ "GenSigAutoGenSnd" SG_ 268 TSK_Standby_Anf_ESP 1;
BA_ "GenSigSendType" SG_ 268 TSK_Standby_Anf_ESP 7;
BA_ "NWM-WakeupAllowed" SG_ 268 TSK_Standby_Anf_ESP 0;
BA_ "NMH-WakeupAllowed" SG_ 268 TSK_Standby_Anf_ESP 0;
BA_ "GenSigTimeoutMsg_Gateway_B8" SG_ 268 TSK_Standby_Anf_ESP 268;
BA_ "GenSigAutoGenDsp" SG_ 268 TSK_Codierung_ACC 1;
BA_ "GenSigAutoGenSnd" SG_ 268 TSK_Codierung_ACC 1;
BA_ "GenSigSendType" SG_ 268 TSK_Codierung_ACC 7;
BA_ "NWM-WakeupAllowed" SG_ 268 TSK_Codierung_ACC 0;
BA_ "NMH-WakeupAllowed" SG_ 268 TSK_Codierung_ACC 0;
BA_ "GenSigTimeoutMsg_Gateway_B8" SG_ 268 TSK_Codierung_ACC 268;
BA_ "GenSigAutoGenDsp" SG_ 268 TSK_Zwangszusch_ESP 1;
BA_ "GenSigAutoGenSnd" SG_ 268 TSK_Zwangszusch_ESP 1;
BA_ "GenSigSendType" SG_ 268 TSK_Zwangszusch_ESP 7;
BA_ "NWM-WakeupAllowed" SG_ 268 TSK_Zwangszusch_ESP 0;
BA_ "NMH-WakeupAllowed" SG_ 268 TSK_Zwangszusch_ESP 0;
BA_ "GenSigTimeoutMsg_Gateway_B8" SG_ 268 TSK_Zwangszusch_ESP 268;
BA_ "GenSigAutoGenDsp" SG_ 268 TSK_Freig_Verzoeg_Anf 0;
BA_ "GenSigAutoGenSnd" SG_ 268 TSK_Freig_Verzoeg_Anf 0;
BA_ "GenSigSendType" SG_ 268 TSK_Freig_Verzoeg_Anf 7;
BA_ "NWM-WakeupAllowed" SG_ 268 TSK_Freig_Verzoeg_Anf 0;
BA_ "NMH-WakeupAllowed" SG_ 268 TSK_Freig_Verzoeg_Anf 0;
BA_ "GenSigTimeoutMsg_Daempfer_B8" SG_ 268 TSK_Freig_Verzoeg_Anf 268;
BA_ "GenSigTimeoutMsg_Gateway_B8" SG_ 268 TSK_Freig_Verzoeg_Anf 268;
BA_ "GenSigTimeoutMsg_Getriebe_VL3002" SG_ 268 TSK_Freig_Verzoeg_Anf 268;
BA_ "GenSigAutoGenDsp" SG_ 268 TSK_Verzoeg_Anf 1;
BA_ "GenSigAutoGenSnd" SG_ 268 TSK_Verzoeg_Anf 1;
BA_ "GenSigEnvVarType" SG_ 268 TSK_Verzoeg_Anf 1;
BA_ "GenSigSendType" SG_ 268 TSK_Verzoeg_Anf 7;
BA_ "GenSigStartValue" SG_ 268 TSK_Verzoeg_Anf 166;
BA_ "NWM-WakeupAllowed" SG_ 268 TSK_Verzoeg_Anf 0;
BA_ "NMH-WakeupAllowed" SG_ 268 TSK_Verzoeg_Anf 0;
BA_ "GenSigTimeoutMsg_Daempfer_B8" SG_ 268 TSK_Verzoeg_Anf 268;
BA_ "GenSigTimeoutMsg_Gateway_B8" SG_ 268 TSK_Verzoeg_Anf 268;
BA_ "GenSigAutoGenDsp" SG_ 786 TSK_03_CHK 1;
BA_ "GenSigAutoGenSnd" SG_ 786 TSK_03_CHK 1;
BA_ "GenSigSendType" SG_ 786 TSK_03_CHK 7;
BA_ "NWM-WakeupAllowed" SG_ 786 TSK_03_CHK 0;
BA_ "NMH-WakeupAllowed" SG_ 786 TSK_03_CHK 0;
BA_ "GenSigTimeoutMsg_Gateway_B8" SG_ 786 TSK_03_CHK 786;
BA_ "GenSigAutoGenDsp" SG_ 786 TSK_03_BZ 1;
BA_ "GenSigAutoGenSnd" SG_ 786 TSK_03_BZ 1;
BA_ "GenSigSendType" SG_ 786 TSK_03_BZ 7;
BA_ "NWM-WakeupAllowed" SG_ 786 TSK_03_BZ 0;
BA_ "NMH-WakeupAllowed" SG_ 786 TSK_03_BZ 0;
BA_ "GenSigTimeoutMsg_Gateway_B8" SG_ 786 TSK_03_BZ 786;
BA_ "GenSigAutoGenDsp" SG_ 786 FAS_Wunschgeschw 1;
BA_ "GenSigAutoGenSnd" SG_ 786 FAS_Wunschgeschw 1;
BA_ "GenSigSendType" SG_ 786 FAS_Wunschgeschw 7;
BA_ "NWM-WakeupAllowed" SG_ 786 FAS_Wunschgeschw 0;
BA_ "NMH-WakeupAllowed" SG_ 786 FAS_Wunschgeschw 0;
BA_ "GenSigTimeoutMsg_Gateway_B8" SG_ 786 FAS_Wunschgeschw 786;
BA_ "GenSigAutoGenDsp" SG_ 786 FAS_Status_Prim_Anz 1;
BA_ "GenSigAutoGenSnd" SG_ 786 FAS_Status_Prim_Anz 1;
BA_ "GenSigSendType" SG_ 786 FAS_Status_Prim_Anz 7;
BA_ "NWM-WakeupAllowed" SG_ 786 FAS_Status_Prim_Anz 0;
BA_ "NMH-WakeupAllowed" SG_ 786 FAS_Status_Prim_Anz 0;
BA_ "GenSigTimeoutMsg_Gateway_B8" SG_ 786 FAS_Status_Prim_Anz 786;
BA_ "GenSigAutoGenDsp" SG_ 786 FAS_Texte_Primaeranz 1;
BA_ "GenSigAutoGenSnd" SG_ 786 FAS_Texte_Primaeranz 1;
BA_ "GenSigSendType" SG_ 786 FAS_Texte_Primaeranz 7;
BA_ "NWM-WakeupAllowed" SG_ 786 FAS_Texte_Primaeranz 0;
BA_ "NMH-WakeupAllowed" SG_ 786 FAS_Texte_Primaeranz 0;
BA_ "GenSigTimeoutMsg_Gateway_B8" SG_ 786 FAS_Texte_Primaeranz 786;
BA_ "GenSigAutoGenDsp" SG_ 786 FAS_Status_Anzeige 0;
BA_ "GenSigAutoGenSnd" SG_ 786 FAS_Status_Anzeige 0;
BA_ "GenSigSendType" SG_ 786 FAS_Status_Anzeige 7;
BA_ "NWM-WakeupAllowed" SG_ 786 FAS_Status_Anzeige 0;
BA_ "NMH-WakeupAllowed" SG_ 786 FAS_Status_Anzeige 0;
BA_ "GenSigTimeoutMsg_Gateway_B8" SG_ 786 FAS_Status_Anzeige 786;
BA_ "GenSigAutoGenDsp" SG_ 270 TSK_04_CHK 1;
BA_ "GenSigAutoGenSnd" SG_ 270 TSK_04_CHK 1;
BA_ "GenSigSendType" SG_ 270 TSK_04_CHK 7;
BA_ "NWM-WakeupAllowed" SG_ 270 TSK_04_CHK 0;
BA_ "NMH-WakeupAllowed" SG_ 270 TSK_04_CHK 0;
BA_ "GenSigTimeoutMsg_Getriebe_AL6000" SG_ 270 TSK_04_CHK 270;
BA_ "GenSigTimeoutMsg_Getriebe_DL5001" SG_ 270 TSK_04_CHK 270;
BA_ "GenSigTimeoutMsg_Getriebe_VL3002" SG_ 270 TSK_04_CHK 270;
BA_ "GenSigAutoGenDsp" SG_ 270 TSK_04_BZ 1;
BA_ "GenSigAutoGenSnd" SG_ 270 TSK_04_BZ 1;
BA_ "GenSigSendType" SG_ 270 TSK_04_BZ 7;
BA_ "NWM-WakeupAllowed" SG_ 270 TSK_04_BZ 0;
BA_ "NMH-WakeupAllowed" SG_ 270 TSK_04_BZ 0;
BA_ "GenSigTimeoutMsg_Getriebe_AL6000" SG_ 270 TSK_04_BZ 270;
BA_ "GenSigTimeoutMsg_Getriebe_DL5001" SG_ 270 TSK_04_BZ 270;
BA_ "GenSigTimeoutMsg_Getriebe_VL3002" SG_ 270 TSK_04_BZ 270;
BA_ "GenSigAutoGenDsp" SG_ 270 TSK_zul_Regelabw 1;
BA_ "GenSigAutoGenSnd" SG_ 270 TSK_zul_Regelabw 1;
BA_ "GenSigSendType" SG_ 270 TSK_zul_Regelabw 7;
BA_ "NWM-WakeupAllowed" SG_ 270 TSK_zul_Regelabw 0;
BA_ "NMH-WakeupAllowed" SG_ 270 TSK_zul_Regelabw 0;
BA_ "GenSigTimeoutMsg_Getriebe_AL6000" SG_ 270 TSK_zul_Regelabw 270;
BA_ "GenSigTimeoutMsg_Getriebe_DL5001" SG_ 270 TSK_zul_Regelabw 270;
BA_ "GenSigTimeoutMsg_Getriebe_VL3002" SG_ 270 TSK_zul_Regelabw 270;
BA_ "GenSigAutoGenDsp" SG_ 270 TSK_ax_Getriebe 1;
BA_ "GenSigAutoGenSnd" SG_ 270 TSK_ax_Getriebe 1;
BA_ "GenSigSendType" SG_ 270 TSK_ax_Getriebe 7;
BA_ "GenSigStartValue" SG_ 270 TSK_ax_Getriebe 84;
BA_ "NWM-WakeupAllowed" SG_ 270 TSK_ax_Getriebe 0;
BA_ "NMH-WakeupAllowed" SG_ 270 TSK_ax_Getriebe 0;
BA_ "GenSigTimeoutMsg_Getriebe_AL6000" SG_ 270 TSK_ax_Getriebe 270;
BA_ "GenSigTimeoutMsg_Getriebe_DL5001" SG_ 270 TSK_ax_Getriebe 270;
BA_ "GenSigTimeoutMsg_Getriebe_VL3002" SG_ 270 TSK_ax_Getriebe 270;
BA_ "GenSigAutoGenDsp" SG_ 270 TSK_Wunsch_Uebersetz 1;
BA_ "GenSigAutoGenSnd" SG_ 270 TSK_Wunsch_Uebersetz 1;
BA_ "GenSigSendType" SG_ 270 TSK_Wunsch_Uebersetz 7;
BA_ "NWM-WakeupAllowed" SG_ 270 TSK_Wunsch_Uebersetz 0;
BA_ "NMH-WakeupAllowed" SG_ 270 TSK_Wunsch_Uebersetz 0;
BA_ "GenSigTimeoutMsg_Getriebe_AL6000" SG_ 270 TSK_Wunsch_Uebersetz 270;
BA_ "GenSigTimeoutMsg_Getriebe_DL5001" SG_ 270 TSK_Wunsch_Uebersetz 270;
BA_ "GenSigTimeoutMsg_Getriebe_VL3002" SG_ 270 TSK_Wunsch_Uebersetz 270;
BA_ "GenSigAutoGenDsp" SG_ 270 TSK_Freig_WU 1;
BA_ "GenSigAutoGenSnd" SG_ 270 TSK_Freig_WU 1;
BA_ "GenSigSendType" SG_ 270 TSK_Freig_WU 7;
BA_ "NWM-WakeupAllowed" SG_ 270 TSK_Freig_WU 0;
BA_ "NMH-WakeupAllowed" SG_ 270 TSK_Freig_WU 0;
BA_ "GenSigTimeoutMsg_Getriebe_AL6000" SG_ 270 TSK_Freig_WU 270;
BA_ "GenSigTimeoutMsg_Getriebe_DL5001" SG_ 270 TSK_Freig_WU 270;
BA_ "GenSigTimeoutMsg_Getriebe_VL3002" SG_ 270 TSK_Freig_WU 270;
BA_ "GenSigAutoGenDsp" SG_ 270 TSK_Limiter_aktiv 1;
BA_ "GenSigAutoGenSnd" SG_ 270 TSK_Limiter_aktiv 1;
BA_ "GenSigSendType" SG_ 270 TSK_Limiter_aktiv 7;
BA_ "NWM-WakeupAllowed" SG_ 270 TSK_Limiter_aktiv 0;
BA_ "NMH-WakeupAllowed" SG_ 270 TSK_Limiter_aktiv 0;
BA_ "GenSigTimeoutMsg_Getriebe_AL6000" SG_ 270 TSK_Limiter_aktiv 270;
BA_ "GenSigTimeoutMsg_Getriebe_DL5001" SG_ 270 TSK_Limiter_aktiv 270;
BA_ "GenSigTimeoutMsg_Getriebe_VL3002" SG_ 270 TSK_Limiter_aktiv 270;
BA_ "GenSigAutoGenDsp" SG_ 270 TSK_Status_GRA_ACC_02 1;
BA_ "GenSigAutoGenSnd" SG_ 270 TSK_Status_GRA_ACC_02 1;
BA_ "GenSigEnvVarType" SG_ 270 TSK_Status_GRA_ACC_02 0;
BA_ "GenSigSendType" SG_ 270 TSK_Status_GRA_ACC_02 7;
BA_ "NWM-WakeupAllowed" SG_ 270 TSK_Status_GRA_ACC_02 0;
BA_ "NMH-WakeupAllowed" SG_ 270 TSK_Status_GRA_ACC_02 0;
BA_ "GenSigTimeoutMsg_Getriebe_AL6000" SG_ 270 TSK_Status_GRA_ACC_02 270;
BA_ "GenSigTimeoutMsg_Getriebe_DL5001" SG_ 270 TSK_Status_GRA_ACC_02 270;
BA_ "GenSigTimeoutMsg_Getriebe_VL3002" SG_ 270 TSK_Status_GRA_ACC_02 270;
BA_ "GenSigAutoGenDsp" SG_ 1716 VIN_01_MUX 1;
BA_ "GenSigAutoGenSnd" SG_ 1716 VIN_01_MUX 1;
BA_ "GenSigEnvVarType" SG_ 1716 VIN_01_MUX 0;
BA_ "GenSigSendType" SG_ 1716 VIN_01_MUX 7;
BA_ "NWM-WakeupAllowed" SG_ 1716 VIN_01_MUX 0;
BA_ "NMH-WakeupAllowed" SG_ 1716 VIN_01_MUX 0;
BA_ "GenSigTimeoutMsg_Airbag_B8" SG_ 1716 VIN_01_MUX 1716;
BA_ "GenSigTimeoutMsg_Daempfer_B8" SG_ 1716 VIN_01_MUX 1716;
BA_ "GenSigAutoGenDsp" SG_ 1716 KS_Geheimnis_1 1;
BA_ "GenSigAutoGenSnd" SG_ 1716 KS_Geheimnis_1 1;
BA_ "GenSigEnvVarType" SG_ 1716 KS_Geheimnis_1 0;
BA_ "GenSigSendType" SG_ 1716 KS_Geheimnis_1 7;
BA_ "NWM-WakeupAllowed" SG_ 1716 KS_Geheimnis_1 0;
BA_ "NMH-WakeupAllowed" SG_ 1716 KS_Geheimnis_1 0;
BA_ "GenSigTimeoutMsg_Airbag_B8" SG_ 1716 KS_Geheimnis_1 1716;
BA_ "GenSigAutoGenDsp" SG_ 1716 VIN_4 1;
BA_ "GenSigAutoGenSnd" SG_ 1716 VIN_4 1;
BA_ "GenSigEnvVarType" SG_ 1716 VIN_4 0;
BA_ "GenSigSendType" SG_ 1716 VIN_4 7;
BA_ "NWM-WakeupAllowed" SG_ 1716 VIN_4 0;
BA_ "NMH-WakeupAllowed" SG_ 1716 VIN_4 0;
BA_ "GenSigTimeoutMsg_Airbag_B8" SG_ 1716 VIN_4 1716;
BA_ "GenSigTimeoutMsg_Daempfer_B8" SG_ 1716 VIN_4 1716;
BA_ "GenSigAutoGenDsp" SG_ 1716 VIN_11 1;
BA_ "GenSigAutoGenSnd" SG_ 1716 VIN_11 1;
BA_ "GenSigEnvVarType" SG_ 1716 VIN_11 0;
BA_ "GenSigSendType" SG_ 1716 VIN_11 7;
BA_ "NWM-WakeupAllowed" SG_ 1716 VIN_11 0;
BA_ "NMH-WakeupAllowed" SG_ 1716 VIN_11 0;
BA_ "GenSigTimeoutMsg_Airbag_B8" SG_ 1716 VIN_11 1716;
BA_ "GenSigTimeoutMsg_Daempfer_B8" SG_ 1716 VIN_11 1716;
BA_ "GenSigAutoGenDsp" SG_ 1716 KS_Geheimnis_2 1;
BA_ "GenSigAutoGenSnd" SG_ 1716 KS_Geheimnis_2 1;
BA_ "GenSigEnvVarType" SG_ 1716 KS_Geheimnis_2 0;
BA_ "GenSigSendType" SG_ 1716 KS_Geheimnis_2 7;
BA_ "NWM-WakeupAllowed" SG_ 1716 KS_Geheimnis_2 0;
BA_ "NMH-WakeupAllowed" SG_ 1716 KS_Geheimnis_2 0;
BA_ "GenSigTimeoutMsg_Airbag_B8" SG_ 1716 KS_Geheimnis_2 1716;
BA_ "GenSigAutoGenDsp" SG_ 1716 VIN_5 1;
BA_ "GenSigAutoGenSnd" SG_ 1716 VIN_5 1;
BA_ "GenSigEnvVarType" SG_ 1716 VIN_5 0;
BA_ "GenSigSendType" SG_ 1716 VIN_5 7;
BA_ "NWM-WakeupAllowed" SG_ 1716 VIN_5 0;
BA_ "NMH-WakeupAllowed" SG_ 1716 VIN_5 0;
BA_ "GenSigTimeoutMsg_Airbag_B8" SG_ 1716 VIN_5 1716;
BA_ "GenSigTimeoutMsg_Daempfer_B8" SG_ 1716 VIN_5 1716;
BA_ "GenSigAutoGenDsp" SG_ 1716 VIN_12 1;
BA_ "GenSigAutoGenSnd" SG_ 1716 VIN_12 1;
BA_ "GenSigEnvVarType" SG_ 1716 VIN_12 0;
BA_ "GenSigSendType" SG_ 1716 VIN_12 7;
BA_ "NWM-WakeupAllowed" SG_ 1716 VIN_12 0;
BA_ "NMH-WakeupAllowed" SG_ 1716 VIN_12 0;
BA_ "GenSigTimeoutMsg_Airbag_B8" SG_ 1716 VIN_12 1716;
BA_ "GenSigTimeoutMsg_Daempfer_B8" SG_ 1716 VIN_12 1716;
BA_ "GenSigAutoGenDsp" SG_ 1716 KS_Geheimnis_3 1;
BA_ "GenSigAutoGenSnd" SG_ 1716 KS_Geheimnis_3 1;
BA_ "GenSigEnvVarType" SG_ 1716 KS_Geheimnis_3 0;
BA_ "GenSigSendType" SG_ 1716 KS_Geheimnis_3 7;
BA_ "NWM-WakeupAllowed" SG_ 1716 KS_Geheimnis_3 0;
BA_ "NMH-WakeupAllowed" SG_ 1716 KS_Geheimnis_3 0;
BA_ "GenSigTimeoutMsg_Airbag_B8" SG_ 1716 KS_Geheimnis_3 1716;
BA_ "GenSigAutoGenDsp" SG_ 1716 VIN_6 1;
BA_ "GenSigAutoGenSnd" SG_ 1716 VIN_6 1;
BA_ "GenSigEnvVarType" SG_ 1716 VIN_6 0;
BA_ "GenSigSendType" SG_ 1716 VIN_6 7;
BA_ "NWM-WakeupAllowed" SG_ 1716 VIN_6 0;
BA_ "NMH-WakeupAllowed" SG_ 1716 VIN_6 0;
BA_ "GenSigTimeoutMsg_Airbag_B8" SG_ 1716 VIN_6 1716;
BA_ "GenSigTimeoutMsg_Daempfer_B8" SG_ 1716 VIN_6 1716;
BA_ "GenSigAutoGenDsp" SG_ 1716 VIN_13 1;
BA_ "GenSigAutoGenSnd" SG_ 1716 VIN_13 1;
BA_ "GenSigEnvVarType" SG_ 1716 VIN_13 0;
BA_ "GenSigSendType" SG_ 1716 VIN_13 7;
BA_ "NWM-WakeupAllowed" SG_ 1716 VIN_13 0;
BA_ "NMH-WakeupAllowed" SG_ 1716 VIN_13 0;
BA_ "GenSigTimeoutMsg_Airbag_B8" SG_ 1716 VIN_13 1716;
BA_ "GenSigTimeoutMsg_Daempfer_B8" SG_ 1716 VIN_13 1716;
BA_ "GenSigAutoGenDsp" SG_ 1716 KS_Geheimnis_4 1;
BA_ "GenSigAutoGenSnd" SG_ 1716 KS_Geheimnis_4 1;
BA_ "GenSigEnvVarType" SG_ 1716 KS_Geheimnis_4 0;
BA_ "GenSigSendType" SG_ 1716 KS_Geheimnis_4 7;
BA_ "NWM-WakeupAllowed" SG_ 1716 KS_Geheimnis_4 0;
BA_ "NMH-WakeupAllowed" SG_ 1716 KS_Geheimnis_4 0;
BA_ "GenSigTimeoutMsg_Airbag_B8" SG_ 1716 KS_Geheimnis_4 1716;
BA_ "GenSigAutoGenDsp" SG_ 1716 VIN_7 1;
BA_ "GenSigAutoGenSnd" SG_ 1716 VIN_7 1;
BA_ "GenSigEnvVarType" SG_ 1716 VIN_7 0;
BA_ "GenSigSendType" SG_ 1716 VIN_7 7;
BA_ "NWM-WakeupAllowed" SG_ 1716 VIN_7 0;
BA_ "NMH-WakeupAllowed" SG_ 1716 VIN_7 0;
BA_ "GenSigTimeoutMsg_Airbag_B8" SG_ 1716 VIN_7 1716;
BA_ "GenSigTimeoutMsg_Daempfer_B8" SG_ 1716 VIN_7 1716;
BA_ "GenSigAutoGenDsp" SG_ 1716 VIN_14 1;
BA_ "GenSigAutoGenSnd" SG_ 1716 VIN_14 1;
BA_ "GenSigEnvVarType" SG_ 1716 VIN_14 0;
BA_ "GenSigSendType" SG_ 1716 VIN_14 7;
BA_ "NWM-WakeupAllowed" SG_ 1716 VIN_14 0;
BA_ "NMH-WakeupAllowed" SG_ 1716 VIN_14 0;
BA_ "GenSigTimeoutMsg_Airbag_B8" SG_ 1716 VIN_14 1716;
BA_ "GenSigTimeoutMsg_Daempfer_B8" SG_ 1716 VIN_14 1716;
BA_ "GenSigAutoGenDsp" SG_ 1716 VIN_1 1;
BA_ "GenSigAutoGenSnd" SG_ 1716 VIN_1 1;
BA_ "GenSigEnvVarType" SG_ 1716 VIN_1 0;
BA_ "GenSigSendType" SG_ 1716 VIN_1 7;
BA_ "NWM-WakeupAllowed" SG_ 1716 VIN_1 0;
BA_ "NMH-WakeupAllowed" SG_ 1716 VIN_1 0;
BA_ "GenSigTimeoutMsg_Airbag_B8" SG_ 1716 VIN_1 1716;
BA_ "GenSigTimeoutMsg_Daempfer_B8" SG_ 1716 VIN_1 1716;
BA_ "GenSigAutoGenDsp" SG_ 1716 VIN_8 1;
BA_ "GenSigAutoGenSnd" SG_ 1716 VIN_8 1;
BA_ "GenSigEnvVarType" SG_ 1716 VIN_8 0;
BA_ "GenSigSendType" SG_ 1716 VIN_8 7;
BA_ "NWM-WakeupAllowed" SG_ 1716 VIN_8 0;
BA_ "NMH-WakeupAllowed" SG_ 1716 VIN_8 0;
BA_ "GenSigTimeoutMsg_Airbag_B8" SG_ 1716 VIN_8 1716;
BA_ "GenSigTimeoutMsg_Daempfer_B8" SG_ 1716 VIN_8 1716;
BA_ "GenSigAutoGenDsp" SG_ 1716 VIN_15 1;
BA_ "GenSigAutoGenSnd" SG_ 1716 VIN_15 1;
BA_ "GenSigEnvVarType" SG_ 1716 VIN_15 0;
BA_ "GenSigSendType" SG_ 1716 VIN_15 7;
BA_ "NWM-WakeupAllowed" SG_ 1716 VIN_15 0;
BA_ "NMH-WakeupAllowed" SG_ 1716 VIN_15 0;
BA_ "GenSigTimeoutMsg_Airbag_B8" SG_ 1716 VIN_15 1716;
BA_ "GenSigTimeoutMsg_Daempfer_B8" SG_ 1716 VIN_15 1716;
BA_ "GenSigAutoGenDsp" SG_ 1716 VIN_2 1;
BA_ "GenSigAutoGenSnd" SG_ 1716 VIN_2 1;
BA_ "GenSigEnvVarType" SG_ 1716 VIN_2 0;
BA_ "GenSigSendType" SG_ 1716 VIN_2 7;
BA_ "NWM-WakeupAllowed" SG_ 1716 VIN_2 0;
BA_ "NMH-WakeupAllowed" SG_ 1716 VIN_2 0;
BA_ "GenSigTimeoutMsg_Airbag_B8" SG_ 1716 VIN_2 1716;
BA_ "GenSigTimeoutMsg_Daempfer_B8" SG_ 1716 VIN_2 1716;
BA_ "GenSigAutoGenDsp" SG_ 1716 VIN_9 1;
BA_ "GenSigAutoGenSnd" SG_ 1716 VIN_9 1;
BA_ "GenSigEnvVarType" SG_ 1716 VIN_9 0;
BA_ "GenSigSendType" SG_ 1716 VIN_9 7;
BA_ "NWM-WakeupAllowed" SG_ 1716 VIN_9 0;
BA_ "NMH-WakeupAllowed" SG_ 1716 VIN_9 0;
BA_ "GenSigTimeoutMsg_Airbag_B8" SG_ 1716 VIN_9 1716;
BA_ "GenSigTimeoutMsg_Daempfer_B8" SG_ 1716 VIN_9 1716;
BA_ "GenSigAutoGenDsp" SG_ 1716 VIN_16 1;
BA_ "GenSigAutoGenSnd" SG_ 1716 VIN_16 1;
BA_ "GenSigEnvVarType" SG_ 1716 VIN_16 0;
BA_ "GenSigSendType" SG_ 1716 VIN_16 7;
BA_ "NWM-WakeupAllowed" SG_ 1716 VIN_16 0;
BA_ "NMH-WakeupAllowed" SG_ 1716 VIN_16 0;
BA_ "GenSigTimeoutMsg_Airbag_B8" SG_ 1716 VIN_16 1716;
BA_ "GenSigTimeoutMsg_Daempfer_B8" SG_ 1716 VIN_16 1716;
BA_ "GenSigAutoGenDsp" SG_ 1716 VIN_3 1;
BA_ "GenSigAutoGenSnd" SG_ 1716 VIN_3 1;
BA_ "GenSigEnvVarType" SG_ 1716 VIN_3 0;
BA_ "GenSigSendType" SG_ 1716 VIN_3 7;
BA_ "NWM-WakeupAllowed" SG_ 1716 VIN_3 0;
BA_ "NMH-WakeupAllowed" SG_ 1716 VIN_3 0;
BA_ "GenSigTimeoutMsg_Airbag_B8" SG_ 1716 VIN_3 1716;
BA_ "GenSigTimeoutMsg_Daempfer_B8" SG_ 1716 VIN_3 1716;
BA_ "GenSigAutoGenDsp" SG_ 1716 VIN_10 1;
BA_ "GenSigAutoGenSnd" SG_ 1716 VIN_10 1;
BA_ "GenSigEnvVarType" SG_ 1716 VIN_10 0;
BA_ "GenSigSendType" SG_ 1716 VIN_10 7;
BA_ "NWM-WakeupAllowed" SG_ 1716 VIN_10 0;
BA_ "NMH-WakeupAllowed" SG_ 1716 VIN_10 0;
BA_ "GenSigTimeoutMsg_Airbag_B8" SG_ 1716 VIN_10 1716;
BA_ "GenSigTimeoutMsg_Daempfer_B8" SG_ 1716 VIN_10 1716;
BA_ "GenSigAutoGenDsp" SG_ 1716 VIN_17 1;
BA_ "GenSigAutoGenSnd" SG_ 1716 VIN_17 1;
BA_ "GenSigEnvVarType" SG_ 1716 VIN_17 0;
BA_ "GenSigSendType" SG_ 1716 VIN_17 7;
BA_ "NWM-WakeupAllowed" SG_ 1716 VIN_17 0;
BA_ "NMH-WakeupAllowed" SG_ 1716 VIN_17 0;
BA_ "GenSigTimeoutMsg_Airbag_B8" SG_ 1716 VIN_17 1716;
BA_ "GenSigTimeoutMsg_Daempfer_B8" SG_ 1716 VIN_17 1716;
BA_ "GenSigAutoGenDsp" SG_ 912 WBA_Senderkennung 1;
BA_ "GenSigAutoGenSnd" SG_ 912 WBA_Senderkennung 1;
BA_ "GenSigEnvVarType" SG_ 912 WBA_Senderkennung 0;
BA_ "GenSigSendType" SG_ 912 WBA_Senderkennung 7;
BA_ "NWM-WakeupAllowed" SG_ 912 WBA_Senderkennung 0;
BA_ "NMH-WakeupAllowed" SG_ 912 WBA_Senderkennung 0;
BA_ "GenSigTimeoutMsg_Gateway_B8" SG_ 912 WBA_Senderkennung 912;
BA_ "GenSigAutoGenDsp" SG_ 912 WBA_Getriebevariante 1;
BA_ "GenSigAutoGenSnd" SG_ 912 WBA_Getriebevariante 1;
BA_ "GenSigEnvVarType" SG_ 912 WBA_Getriebevariante 0;
BA_ "GenSigSendType" SG_ 912 WBA_Getriebevariante 7;
BA_ "NWM-WakeupAllowed" SG_ 912 WBA_Getriebevariante 0;
BA_ "NMH-WakeupAllowed" SG_ 912 WBA_Getriebevariante 0;
BA_ "GenSigTimeoutMsg_Gateway_B8" SG_ 912 WBA_Getriebevariante 912;
BA_ "GenSigAutoGenDsp" SG_ 912 WBA_Fahrstufe 1;
BA_ "GenSigAutoGenSnd" SG_ 912 WBA_Fahrstufe 1;
BA_ "GenSigEnvVarType" SG_ 912 WBA_Fahrstufe 0;
BA_ "GenSigSendType" SG_ 912 WBA_Fahrstufe 7;
BA_ "NWM-WakeupAllowed" SG_ 912 WBA_Fahrstufe 0;
BA_ "NMH-WakeupAllowed" SG_ 912 WBA_Fahrstufe 0;
BA_ "GenSigTimeoutMsg_Gateway_B8" SG_ 912 WBA_Fahrstufe 912;
BA_ "GenSigAutoGenDsp" SG_ 912 WBA_Istgang 1;
BA_ "GenSigAutoGenSnd" SG_ 912 WBA_Istgang 1;
BA_ "GenSigSendType" SG_ 912 WBA_Istgang 7;
BA_ "NWM-WakeupAllowed" SG_ 912 WBA_Istgang 0;
BA_ "NMH-WakeupAllowed" SG_ 912 WBA_Istgang 0;
BA_ "GenSigTimeoutMsg_Gateway_B8" SG_ 912 WBA_Istgang 912;
BA_ "GenSigAutoGenDsp" SG_ 912 WBA_eing_Gang 1;
BA_ "GenSigAutoGenSnd" SG_ 912 WBA_eing_Gang 1;
BA_ "GenSigEnvVarType" SG_ 912 WBA_eing_Gang 0;
BA_ "GenSigSendType" SG_ 912 WBA_eing_Gang 7;
BA_ "GenSigStartValue" SG_ 912 WBA_eing_Gang 1;
BA_ "NWM-WakeupAllowed" SG_ 912 WBA_eing_Gang 0;
BA_ "NMH-WakeupAllowed" SG_ 912 WBA_eing_Gang 0;
BA_ "GenSigTimeoutMsg_Gateway_B8" SG_ 912 WBA_eing_Gang 912;
BA_ "GenSigAutoGenDsp" SG_ 912 WBA_Sollgang 1;
BA_ "GenSigAutoGenSnd" SG_ 912 WBA_Sollgang 1;
BA_ "GenSigSendType" SG_ 912 WBA_Sollgang 7;
BA_ "NWM-WakeupAllowed" SG_ 912 WBA_Sollgang 0;
BA_ "NMH-WakeupAllowed" SG_ 912 WBA_Sollgang 0;
BA_ "GenSigTimeoutMsg_Gateway_B8" SG_ 912 WBA_Sollgang 912;
BA_ "GenSigAutoGenDsp" SG_ 912 WBA_Blinken 1;
BA_ "GenSigAutoGenSnd" SG_ 912 WBA_Blinken 1;
BA_ "GenSigEnvVarType" SG_ 912 WBA_Blinken 0;
BA_ "GenSigSendType" SG_ 912 WBA_Blinken 7;
BA_ "NWM-WakeupAllowed" SG_ 912 WBA_Blinken 0;
BA_ "NMH-WakeupAllowed" SG_ 912 WBA_Blinken 0;
BA_ "GenSigTimeoutMsg_Gateway_B8" SG_ 912 WBA_Blinken 912;
BA_ "GenSigAutoGenDsp" SG_ 912 WBA_Lampe_Shift_Lock 1;
BA_ "GenSigAutoGenSnd" SG_ 912 WBA_Lampe_Shift_Lock 1;
BA_ "GenSigEnvVarType" SG_ 912 WBA_Lampe_Shift_Lock 0;
BA_ "GenSigSendType" SG_ 912 WBA_Lampe_Shift_Lock 7;
BA_ "NWM-WakeupAllowed" SG_ 912 WBA_Lampe_Shift_Lock 0;
BA_ "NMH-WakeupAllowed" SG_ 912 WBA_Lampe_Shift_Lock 0;
BA_ "GenSigTimeoutMsg_Gateway_B8" SG_ 912 WBA_Lampe_Shift_Lock 912;
BA_ "GenSigAutoGenDsp" SG_ 912 WBA_Schaltempf_verfbar 1;
BA_ "GenSigAutoGenSnd" SG_ 912 WBA_Schaltempf_verfbar 1;
BA_ "GenSigSendType" SG_ 912 WBA_Schaltempf_verfbar 7;
BA_ "NWM-WakeupAllowed" SG_ 912 WBA_Schaltempf_verfbar 0;
BA_ "NMH-WakeupAllowed" SG_ 912 WBA_Schaltempf_verfbar 0;
BA_ "GenSigTimeoutMsg_Gateway_B8" SG_ 912 WBA_Schaltempf_verfbar 912;
BA_ "GenSigAutoGenDsp" SG_ 1602 WIV_Verschleissindex 1;
BA_ "GenSigAutoGenSnd" SG_ 1602 WIV_Verschleissindex 1;
BA_ "GenSigEnvVarType" SG_ 1602 WIV_Verschleissindex 0;
BA_ "GenSigSendType" SG_ 1602 WIV_Verschleissindex 7;
BA_ "NWM-WakeupAllowed" SG_ 1602 WIV_Verschleissindex 0;
BA_ "NMH-WakeupAllowed" SG_ 1602 WIV_Verschleissindex 0;
BA_ "GenSigTimeoutMsg_Gateway_B8" SG_ 1602 WIV_Verschleissindex 1602;
BA_ "GenSigAutoGenDsp" SG_ 1602 WIV_Russindex 1;
BA_ "GenSigAutoGenSnd" SG_ 1602 WIV_Russindex 1;
BA_ "GenSigEnvVarType" SG_ 1602 WIV_Russindex 1;
BA_ "GenSigSendType" SG_ 1602 WIV_Russindex 7;
BA_ "NWM-WakeupAllowed" SG_ 1602 WIV_Russindex 0;
BA_ "NMH-WakeupAllowed" SG_ 1602 WIV_Russindex 0;
BA_ "GenSigTimeoutMsg_Gateway_B8" SG_ 1602 WIV_Russindex 1602;
BA_ "GenSigAutoGenDsp" SG_ 1602 WIV_t_min 1;
BA_ "GenSigAutoGenSnd" SG_ 1602 WIV_t_min 1;
BA_ "GenSigEnvVarType" SG_ 1602 WIV_t_min 1;
BA_ "GenSigSendType" SG_ 1602 WIV_t_min 7;
BA_ "GenSigStartValue" SG_ 1602 WIV_t_min 12;
BA_ "NWM-WakeupAllowed" SG_ 1602 WIV_t_min 0;
BA_ "NMH-WakeupAllowed" SG_ 1602 WIV_t_min 0;
BA_ "GenSigTimeoutMsg_Gateway_B8" SG_ 1602 WIV_t_min 1602;
BA_ "GenSigAutoGenDsp" SG_ 1602 WIV_t_max 1;
BA_ "GenSigAutoGenSnd" SG_ 1602 WIV_t_max 1;
BA_ "GenSigEnvVarType" SG_ 1602 WIV_t_max 1;
BA_ "GenSigSendType" SG_ 1602 WIV_t_max 7;
BA_ "GenSigStartValue" SG_ 1602 WIV_t_max 24;
BA_ "NWM-WakeupAllowed" SG_ 1602 WIV_t_max 0;
BA_ "NMH-WakeupAllowed" SG_ 1602 WIV_t_max 0;
BA_ "GenSigTimeoutMsg_Gateway_B8" SG_ 1602 WIV_t_max 1602;
BA_ "GenSigAutoGenDsp" SG_ 1602 WIV_W_min 1;
BA_ "GenSigAutoGenSnd" SG_ 1602 WIV_W_min 1;
BA_ "GenSigEnvVarType" SG_ 1602 WIV_W_min 1;
BA_ "GenSigSendType" SG_ 1602 WIV_W_min 7;
BA_ "GenSigStartValue" SG_ 1602 WIV_W_min 17;
BA_ "NWM-WakeupAllowed" SG_ 1602 WIV_W_min 0;
BA_ "NMH-WakeupAllowed" SG_ 1602 WIV_W_min 0;
BA_ "GenSigTimeoutMsg_Gateway_B8" SG_ 1602 WIV_W_min 1602;
BA_ "GenSigAutoGenDsp" SG_ 1602 WIV_W_max 1;
BA_ "GenSigAutoGenSnd" SG_ 1602 WIV_W_max 1;
BA_ "GenSigEnvVarType" SG_ 1602 WIV_W_max 1;
BA_ "GenSigSendType" SG_ 1602 WIV_W_max 7;
BA_ "GenSigStartValue" SG_ 1602 WIV_W_max 31;
BA_ "NWM-WakeupAllowed" SG_ 1602 WIV_W_max 0;
BA_ "NMH-WakeupAllowed" SG_ 1602 WIV_W_max 0;
BA_ "GenSigTimeoutMsg_Gateway_B8" SG_ 1602 WIV_W_max 1602;
BA_ "GenSigAutoGenDsp" SG_ 2617009149 XCP_Daempfer_CRO_01_Data 1;
BA_ "GenSigAutoGenSnd" SG_ 2617009149 XCP_Daempfer_CRO_01_Data 1;
BA_ "GenSigSendType" SG_ 2617009149 XCP_Daempfer_CRO_01_Data 7;
BA_ "NWM-WakeupAllowed" SG_ 2617009149 XCP_Daempfer_CRO_01_Data 0;
BA_ "NMH-WakeupAllowed" SG_ 2617009149 XCP_Daempfer_CRO_01_Data 0;
BA_ "GenSigTimeoutMsg_Daempfer_B8" SG_ 2617009149 XCP_Daempfer_CRO_01_Data 469525501;
BA_ "GenSigAutoGenDsp" SG_ 2617009150 XCP_Daempfer_DTO_01_Data 1;
BA_ "GenSigAutoGenSnd" SG_ 2617009150 XCP_Daempfer_DTO_01_Data 1;
BA_ "GenSigSendType" SG_ 2617009150 XCP_Daempfer_DTO_01_Data 7;
BA_ "NWM-WakeupAllowed" SG_ 2617009150 XCP_Daempfer_DTO_01_Data 0;
BA_ "NMH-WakeupAllowed" SG_ 2617009150 XCP_Daempfer_DTO_01_Data 0;
VAL_ 1601 MO_Faktor_Momente 1 "Faktor: x 0,5Nm" 2 "Faktor: x 1,0Nm" 3 "Faktor: x 2,0Nm" 0 "nicht belegt" ;
VAL_ 1601 MO_Getriebe_Code 4 "VL381" 2 "DL501" 15 "Handschalter (konventionell)" 10 "AL651" ;
VAL_ 1601 MO_Kraftstoffart 1 "Benzin" 0 "Diesel" 3 "Erdgas" 2 "CNG" 4 "Wasserstoff" ;
VAL_ 1601 MO_Ansaugsystem 0 "Turbo" 1 "Sauger" ;
VAL_ 1601 MO_Abgastyp 2 "kein EOBD und OBD (US-Norm)" 1 "EOBD und kein OBD (US-Norm)" 3 "EOBD und OBD (US-Norm)" 0 "kein EOBD und kein OBD (US-Norm)" ;
VAL_ 1601 MO_Einspritzart 0 "MPI" 1 " FSI / TDI" ;
VAL_ 1090 MOS_KD_Fehler 1 "eingetragen" 0 "nicht eingetragen" ;
VAL_ 1728 NMH_GW_Per_WakeUp 4 "MOST Wakeup" 5 "LIN Wakeup" 0 "Wenn Funktions-Wakeup" 1 "CAN-Wakeup (Wurde das GW aus einem anderen weckfähigen CAN Segment geweckt, so ist dieses in Byte 7 - Weckendes Bussegment - festgehalten)" 3 "Klemme 15 HW (falls vorhanden)" ;
VAL_ 1728 NMH_GW_Fkt_WakeUp 2 "Car Wakeup empfangen" 0 "Wenn Peripherie-Wakeup" 1 "Funktionswakeup BDM BEM" ;
VAL_ 1728 NMH_GW_NM_aktiv_Klemme_15 1 "Klemme 15 EIN" ;
VAL_ 1728 NMH_GW_NM_aktiv_Diagnose 1 "Diagnose bei Kl 15 aus" ;
VAL_ 1728 NMH_GW_NM_aktiv_Start 1 "Zustand 'START' (NM-high)" ;
VAL_ 1728 NMH_GW_NM_aktiv_BDM 1 "BDM-Kommunikation" ;
VAL_ 1728 NMH_GW_NM_aktiv_Warnblinken 1 "Warnblinken aktiv" ;
VAL_ 1728 NMH_GW_NM_aktiv_ESP 1 "ESP aktiv (Wakeup/Sleep-Konzept)" ;
VAL_ 1728 NMH_GW_Abschaltstufe_3 1 "BEM aufgrund Abschaltstufe 3 aktiv" ;
VAL_ 1728 NMH_GW_SG_Fehlerdauer 1 "BEM aufgrund Steuergeraetefehlerdauer aktiv" ;
VAL_ 1728 NMH_GW_STH_Wakeup 1 "BEM aktiv aufgrund Standheizungswakeup" ;
VAL_ 1728 NMH_GW_TimeOut_Fehler 1 "Aktiver Timeout Fehlerspeichereintrag  " ;
VAL_ 1728 NMH_GW_CAN_Diag_deaktiv 1 "CAN Bus bezogene Eigendiagnose deaktiv" ;
VAL_ 1728 NMH_GW_KompSchutz 1 "KS aktiv" ;
VAL_ 1728 NMH_GW_Mute_Mode 1 "MuteMode aktiv" ;
VAL_ 1728 NMH_GW_Transport_Mode 1 "Transportmodus aktiv" ;
VAL_ 1728 NMH_GW_Abschaltstufe_aktiv 1 "Abschaltstufe aktiv" ;
VAL_ 1728 NMH_GW_Eindraht_Fehler 1 "Eindrahtbetrieb erkannt" ;
VAL_ 1728 NMH_GW_ACAN 1 "ACAN aktiv (Wakeup/Sleep-Konzept)" ;
VAL_ 1728 NMH_GW_KombiCAN 1 "KombiCAN aktiv (Wakeup/Sleep-Konzept)" ;
VAL_ 1728 NMH_GW_KomfortCAN 1 "KomfortCAN aktiv (Wakeup/Sleep-Konzept)" ;
VAL_ 1728 NMH_GW_Infotainment 1 "Infotainment aktiv (CAN oder MOST), Wakeup/Sleep-Konzept" ;
VAL_ 1728 NMH_GW_WakeUp_CAN_Bus 2 "Kombi-CAN" 0 "Nicht zutreffend (kein CAN-Wakeup bzw. CarWakeup)" 1 "Antriebs-CAN" 3 "Komfort-CAN" 4 "Infotainment-CAN (wenn verfuegbar)" ;
VAL_ 1730 NMH_GE_Per_WakeUp 0 "wenn Funktionswakeup" 3 "KL 15 HW (falls vorhanden)" 2 "P-Wakeup, Ursache nicht bekannt" 1 "CAN" ;
VAL_ 1730 NMH_GE_Fkt_WakeUp 0 "wenn Peripheriewakeup" ;
VAL_ 1730 NMH_GE_NM_aktiv_Klemme_15 1 "Klemme 15 ein" ;
VAL_ 1730 NMH_GE_NM_aktiv_Diagnose 1 "Diagnose bei Kl 15 aus" ;
VAL_ 1730 NMH_GE_NM_aktiv_Start 1 "Zustand 'START' (NM-high)" ;
VAL_ 1730 NMH_GE_kein_NL 1 "kein lokaler Nachlauf" ;
VAL_ 1730 NMH_GE_NL_Daten_EEPROM 1 "EEPROM Datenspeicherung" ;
VAL_ 1730 NMH_GE_TimeOut_Fehler 1 "Aktiver Timeout Fehlerspeichereintrag  " ;
VAL_ 1730 NMH_GE_CAN_Diag_deaktiv 1 "CAN-Diagnose deaktiv" ;
VAL_ 1730 NMH_GE_KompSchutz 1 "KS aktiv" ;
VAL_ 1730 NMH_GE_Mute_Mode 1 "MuteMode aktiv" ;
VAL_ 1730 NMH_GE_Transport_Mode 1 "Transportmodus aktiv" ;
VAL_ 1730 NMH_GE_Abschaltstufe_aktiv 1 "Abschaltstufe aktiv" ;
VAL_ 1730 NMH_GE_Eindraht_Fehler 1 "Eindrahtbetrieb erkannt" ;
VAL_ 1729 NMH_MO_Per_WakeUp 0 "Wenn Funktions-Wakeup" 1 "CAN-Wakeup" 2 "Peripherie-Wakeup Ursache nicht bekannt" 3 "Klemme 15 HW (falls vorhanden)" 4 "analog (Standheizung/Tuerkontakt)(nur MED9)" ;
VAL_ 1729 NMH_MO_Fkt_WakeUp 0 "Wenn Peripherie-Wakeup" ;
VAL_ 1729 NMH_MO_NM_aktiv_Klemme_15 1 "Klemme 15 EIN" ;
VAL_ 1729 NMH_MO_NM_aktiv_Diagnose 1 "Diagnose bei Kl 15 aus " ;
VAL_ 1729 NMH_MO_NM_aktiv_Start 1 "Zustand 'START' (NM-high)" ;
VAL_ 1729 NMH_MO_NM_aktiv_EKP_Vorlauf 1 "EKP-Vorlauf" ;
VAL_ 1729 NMH_MO_NM_aktiv_STH_Betrieb 1 "STH-Betrieb" ;
VAL_ 1729 NMH_MO_NM_aktiv_HV_Abschaltung 0 "kein_Nachlauf" 1 "Abschaltung_aktiv" ;
VAL_ 1729 NMH_MO_kein_NL 1 "kein lokaler Nachlauf" ;
VAL_ 1729 NMH_MO_NL_Kuehlerluefter 1 "Kühlerlüfter Steuerung / Zusatzwasserpumpe aktiv" ;
VAL_ 1729 NMH_MO_NL_Diagnose 1 "Diagnosefunktionen aktiv" ;
VAL_ 1729 NMH_MO_NL_WFS 1 "WFS aktiv" ;
VAL_ 1729 NMH_MO_NL_EEPROM 1 "EEPROM Zugriffe RAM/ROM Tests" ;
VAL_ 1729 NMH_MO_NL_Sonstige 1 "Sonstige Nachläufe aktiv" ;
VAL_ 1729 NMH_MO_TimeOut_Fehler 1 "Aktiver Timeout Fehlerspeichereintrag  " ;
VAL_ 1729 NMH_MO_CAN_Diag_deaktiv 1 "CAN-Diagnose deaktiv" ;
VAL_ 1729 NMH_MO_KompSchutz 1 "KS aktiv" ;
VAL_ 1729 NMH_MO_Mute_Mode 1 "MuteMode aktiv" ;
VAL_ 1729 NMH_MO_Transport_Mode 1 "Transportmodus aktiv" ;
VAL_ 1729 NMH_MO_Abschaltstufe_aktiv 1 "Abschaltstufe aktiv" ;
VAL_ 1729 NMH_MO_Eindraht_Fehler 1 "Eindrahtbetrieb erkannt" ;
VAL_ 913 OBD_Calc_Load_Val 255 "Fehler" ;
VAL_ 913 OBD_Eng_Cool_Temp 255 "Fehler" ;
VAL_ 913 OBD_Abs_Throttle_Pos 255 "Fehler" ;
VAL_ 913 OBD_Abs_Load_Val 65535 "Fehler" ;
VAL_ 913 OBD_Abs_Pedal_Pos 255 "Fehler" ;
VAL_ 913 OBD_Driving_Cycle 1 "DC erkannt" 0 "kein Driving Cycle erkannt" ;
VAL_ 913 OBD_Warm_Up_Cycle 0 "kein Warm Up Cycle erkannt" 1 "Warm Up Cycle erkannt" ;
VAL_ 913 OBD_Normed_Trip 1 "Normed Trip erfüllt" 0 "kein Normed Trip" ;
VAL_ 1630 OBD_TG_F_Status_1 0 "kein Fehler / Init / nicht verbaut" 7 "RC- (Signal unplausibel niedrig) (B8: nicht bedient)" 15 "frei" 4 "OOR+ (out of range high) (B8: nicht bedient)" 14 "frei" 2 "KS+ (B8: nicht bedient)" 3 "OC (Leitungsunterbrechung) (B8: nicht bedient)" 12 "frei" 10 "KS-/KS+ (B8: nicht bedient)" 11 "KS-/KS+/OC (allgemeiner Fehler)" 1 "KS-" 6 "RC+ (Signal unplausibel hoch) (B8: nicht bedient)" 5 "OOR- (out of range low) (B8: nicht bedient)" 8 "KS+/OC" 9 "KS-/OC (B8: nicht bedient)" 13 "frei" ;
VAL_ 1630 OBD_TG_F_Status_2 0 "kein Fehler / Init / nicht verbaut" 7 "RC- (Signal unplausibel niedrig) (B8: nicht bedient)" 15 "frei" 4 "OOR+ (out of range high) (B8: nicht bedient)" 14 "frei" 2 "KS+ (B8: nicht bedient)" 3 "OC (Leitungsunterbrechung) (B8: nicht bedient)" 12 "frei" 10 "KS-/KS+ (B8: nicht bedient)" 11 "KS-/KS+/OC (allgemeiner Fehler)" 1 "KS-" 6 "RC+ (Signal unplausibel hoch) (B8: nicht bedient)" 5 "OOR- (out of range low) (B8: nicht bedient)" 8 "KS+/OC" 9 "KS-/OC (B8: nicht bedient)" 13 "frei" ;
VAL_ 1630 OBD_TG_F_Status_3 0 "kein Fehler / Init / nicht verbaut" 7 "RC- (Signal unplausibel niedrig) (B8: nicht bedient)" 15 "frei" 4 "OOR+ (out of range high) (B8: nicht bedient)" 14 "frei" 2 "KS+ (B8: nicht bedient)" 3 "OC (Leitungsunterbrechung) (B8: nicht bedient)" 12 "frei" 10 "KS-/KS+ (B8: nicht bedient)" 11 "KS-/KS+/OC (allgemeiner Fehler)" 1 "KS-" 6 "RC+ (Signal unplausibel hoch) (B8: nicht bedient)" 5 "OOR- (out of range low) (B8: nicht bedient)" 8 "KS+/OC" 9 "KS-/OC (B8: nicht bedient)" 13 "frei" ;
VAL_ 1630 OBD_TG_F_Status_4 0 "kein Fehler / Init / nicht verbaut" 7 "RC- (Signal unplausibel niedrig) (B8: nicht bedient)" 15 "frei" 4 "OOR+ (out of range high) (B8: nicht bedient)" 14 "frei" 2 "KS+ (B8: nicht bedient)" 3 "OC (Leitungsunterbrechung) (B8: nicht bedient)" 12 "frei" 10 "KS-/KS+ (B8: nicht bedient)" 11 "KS-/KS+/OC (allgemeiner Fehler)" 1 "KS-" 6 "RC+ (Signal unplausibel hoch) (B8: nicht bedient)" 5 "OOR- (out of range low) (B8: nicht bedient)" 8 "KS+/OC" 9 "KS-/OC (B8: nicht bedient)" 13 "frei" ;
VAL_ 133 SCU_Ue_Winkel_ADS 4094 "Init" 4095 "Fehler" ;
VAL_ 133 SCU_VZ_Ue_Winkel_ADS 1 "negativ" 0 "positiv" ;
VAL_ 133 SCU_Soll_Ue_Winkel 2046 "Init" 2047 "Fehler" ;
VAL_ 133 SCU_max_Gradient 511 "Fehler" ;
VAL_ 133 SCU_VZ_Soll_Ue_Winkel 1 "negativ" 0 "positiv" ;
VAL_ 133 SCU_Status 1 "Init" 0 "betriebsbereit" 3 "Motorsperre verriegelt" 2 "sichere Übersetzung" 4 "Synchronisierung läuft" ;
VAL_ 133 SCU_KD_Fehler 1 "eingetragen" 0 "nicht eingetragen" ;
VAL_ 1313 STH_Funk_ein 0 "kein Funkbefehl zum Einschalten" 1 "Funkbefehl zum Einschalten erhalten" ;
VAL_ 1313 STH_Funk_aus 1 "Funkbefehl zum Ausschalten erhalten" 0 "kein Funkbefehl" ;
VAL_ 1313 STH_Zusatzheizung 0 "Zuheizer aus" 1 "Zuheizer ein" ;
VAL_ 1313 STH_LED 1 "Rueckmeldung Standheizung in Betrieb" 0 "keine Rückmeldung" ;
VAL_ 1313 STH_Geblaese 0 "kein Einschaltbefehl an die Klimaanlage, Gebläse" 1 "Einschaltbefehl an die Klimaanlage, Gebläse" ;
VAL_ 1313 STH_EKP_Anst 1 "EKP ansteuern" 0 "EKP nicht ansteuern" ;
VAL_ 1313 STH_Fehlerstatus 2 "Fuel Low" 0 "kein Fehler" 1 "Batterie Low" 3 "Hardware defekt" 4 "Heizgeraet verriegelt" ;
VAL_ 1313 STH_Wassertemp 254 "Init" 255 "Fehler" ;
VAL_ 1313 STH_Motorvorwaermung 0 "keine Motorvorwärmung erfolgt" 1 "Aufheizung mit Motorvorwärmung erfolgt" ;
VAL_ 1313 STH_war_aktiv 0 "war inaktiv" 1 "Standheizung war letzte halbe Stunde aktiv" ;
VAL_ 1313 STH_KVS_Ueberlauf 0 "kein Überlauf" 1 "Kraftstoffverbrauchssignal, mindestens ein Überlauf hat stattgefunden" ;
VAL_ 1313 STH_KD_Fehler 1 "eingetragen" 0 "nicht eingetragen" ;
VAL_ 1413 SI_Int_CAN_gespiegelt 1 "interner CAN gespiegelt" 0 "interner CAN getrennt" ;
VAL_ 1413 SI_CAN_Antrieb_Sleep 0 "keine Busruhe" 1 "Busruhe" ;
VAL_ 266 TSK_QBit_Steigung 0 "gültiger Wert" 1 "Ersatz-, Init- oder Fehlerwert" ;
VAL_ 266 TSK_Steigung 255 "Fehler" ;
VAL_ 266 TSK_amax_moeglich 511 "nicht definiert" ;
VAL_ 266 TSK_Getriebeinfo 2 "DL/DQ Getriebe" 1 "AL/AQ Getriebe" 0 "Handschalter" 3 "CVT Getriebe" ;
VAL_ 268 TSK_Anhalten 0 "kein Anhalten gewünscht" 1 "Anhalten gewünscht" ;
VAL_ 268 TSK_Status_GRA_ACC_01 2 "GRA / ACC vom Fahrer übersteuert" 1 "GRA / ACC aktiv " 3 "Fehler, GRA/ACC nicht möglich" 0 "nicht verbaut / kein ACC zulässig" ;
VAL_ 268 TSK_Fahrzeugmasse 31 "Fehler" ;
VAL_ 268 TSK_QBit_Fahrzeugmasse 0 "gültiger Wert" 1 "Ersatz-, Init- oder Fehlerwert" ;
VAL_ 268 TSK_Radbremsmom 4095 "nicht definiert" ;
VAL_ 268 TSK_Standby_Anf_ESP 0 "keine Standby-Anforderung" 1 "Standby-Anforderung" ;
VAL_ 268 TSK_Codierung_ACC 0 "TSK korrekt auf ¿kein ACC` codiert / Triebstrangskoordinator falsch codiert" 1 "TSK korrekt auf ¿ACC` codiert" ;
VAL_ 268 TSK_Zwangszusch_ESP 0 "keine ESP/ASR Beeinflussung" 1 "ESP/ASR Beeinflussung" ;
VAL_ 268 TSK_Freig_Verzoeg_Anf 0 "Verzögerungsanforderung nicht freigegeben" 1 "Verzögerungsanforderung freigegeben" ;
VAL_ 268 TSK_Verzoeg_Anf 255 "nicht definiert" ;
VAL_ 786 FAS_Wunschgeschw 1022 "keine Anzeige" 1023 "nicht definiert" ;
VAL_ 786 FAS_Status_Prim_Anz 2 "Farbe 2 (typisch 'rot')" 0 "Symbol nicht beleuchtet" 1 "Farbe 1 (typisch 'grün')" 3 "Farbe 3 (typisch 'gelb')" ;
VAL_ 786 FAS_Texte_Primaeranz 32 "Im Stand nicht moeglich" 50 "Stehendes Objekt voraus" 33 "Ungueltiger Anfahrbefehl" 52 "SET / 'GRA Symbol' xxx km/h / mph" 20 "Waehlhebelposition !" 51 "SET / 'GRA Symbol'___xxx km/h / mph" 3 "Auto_ _Auto_ _" 54 "ACC startet" 1 "ACC nicht verfuegbar !" 11 "keine Abstandsregelung" 46 "braking guard aus " 63 "LIM FEHLER" 7 "Auto_ _Auto_ _ Gong (durchgestrichen)" 9 "Auto_ _ _ _Auto Gong (durchgestrichen)" 29 "Lenkradwinkel" 55 "ACC reinigen" 65 "Bremse haelt !" 49 "Steigung zu gross" 21 "VDA ACC-Symbol YYY km/h / mph" 14 "o  o  o" 8 "Auto_ _ _Auto_ Gong (durchgestrichen)" 23 "Kurve XXX km/h / mph" 37 "Drehzahl !" 36 "Schalthebelposition !" 22 "Tempolimit XXX km/h / mph" 43 "Tempolimit Ende XXX km/h / mph" 62 "LIM PASSIV" 19 "Geschwindigkeitsgrenze" 53 "ACC aus" 57 "ACC haelt an !" 15 "Hochschalten" 44 "HDC aktiv" 26 "!" 64 "Bremse ueberhitzt !" 13 "ACC nicht verfuegbar" 6 "Auto_Auto_ _ _ Gong (durchgestrichen)" 59 "Kupplung betaetigt" 34 "Tuer offen !" 0 "keine Anzeige " 48 "Uebernehmen !" 4 "Auto_ _ _Auto_" 18 "Parkbremse !" 39 "Tempolimit aus" 5 "Auto_ _ _ _Auto" 58 "Bremse betaetigen !" 47 "braking guard aus" 25 "Symbol 'Eieruhr'" 66 "ESP PASSIV !" 17 "Herunterschalten" 12 "ACC Sensor Sicht !" 28 "XXX km/h / mph (Schriftart 2)" 30 "Anfahren bestaetigen" 27 "--- km/h / mph" 61 "LIM AKTIV " 56 "ACC Fehler" 31 "Fahrzeug verloren" 60 "LIM AUS" 10 "ACC bereit" 38 "Kurvenassistent aus" 35 "Fahrer Gurtschloss offen !" 45 "braking guard Bremsruck" 24 "ACC Abschaltung" 2 "Auto_Auto_ _ _" 42 "Ortsende XXX km/h / mph" 16 "ESP Eingriff" 40 "Abbiegeassistent" 41 "Ortsanfang XXX km/h / mph" ;
VAL_ 786 FAS_Status_Anzeige 2 "ACC/GRA passiv" 0 "ACC/GRA Hauptschalter aus" 3 "ACCGRA aktiv" 1 "ACC in Init (nicht bei GRA)" 4 "ACC/GRA im Hintergrund (übertreten)" 7 "ACC/GRA irreversibel aus" 6 "ACC reversibel aus (nicht bei GRA)" 5 "frei" ;
VAL_ 270 TSK_ax_Getriebe 511 "nicht definiert" ;
VAL_ 270 TSK_Wunsch_Uebersetz 1023 "nicht definiert" ;
VAL_ 270 TSK_Freig_WU 1 "TSK_Uebersetzungswunsch freigegeben" 0 "TSK_Uebersetzungswunsch nicht freigegeben" ;
VAL_ 270 TSK_Limiter_aktiv 1 "Speed Limiter aktiv und regelt" 0 "Speed Limiter ist nicht aktiv" ;
VAL_ 270 TSK_Status_GRA_ACC_02 3 "Fehler, GRA/ACC nicht möglich " 1 "GRA / ACC aktiv " 2 "GRA / ACC vom Fahrer übersteuert" 0 "nicht verbaut / kein ACC zulässig" ;
VAL_ 912 WBA_Senderkennung 1 "Motor" 0 "Getriebe" ;
VAL_ 912 WBA_Getriebevariante 6 "Automat PRNDS" 15 "9 Gang Automat Tiptronic" 1 "Automat PRND" 4 "Vorhalt für ASG (Selespeed)" 14 "8 Gang Automat Tiptronic" 11 "5 Gang Automat Tiptronic" 12 "6 Gang Automat Tiptronic" 13 "7 Gang Automat Tiptronic" 2 "tbd." 8 "tbd." 3 "tbd." 10 "tbd." 9 "tbd." 5 "tbd." 0 "tbd." 7 "tbd." ;
VAL_ 912 WBA_Istgang 4 "4.Gang" 5 "5.Gang" 1 "1.Gang" 2 "2.Gang" 3 "3.Gang" 6 "6.Gang" 0 "kein Gang eingelegt" ;
VAL_ 912 WBA_eing_Gang 0 "kein Gang eingelegt / kein Gang empfohlen" 8 "7.Gang" 10 "9.Gang" 9 "8.Gang" 3 "2.Gang" 2 "1.Gang" 7 "6.Gang" 5 "4.Gang" 6 "5.Gang" 4 "3.Gang" 1 "Init" ;
VAL_ 912 WBA_Sollgang 3 "3.Gang" 0 "keine Empfehlung" 1 "1.Gang" 5 "5.Gang" 6 "6.Gang" 4 "4.Gang" 2 "2.Gang" ;
VAL_ 912 WBA_Blinken 0 "kein_WBA_Blinken" 1 "WBA_Blinken" ;
VAL_ 912 WBA_Lampe_Shift_Lock 1 "SL_Lampe_ein" 0 "SL_Lampe_aus" ;
VAL_ 912 WBA_Schaltempf_verfbar 1 "verfügbar" 0 "nicht verfügbar" ;
VAL_ 1602 WIV_Verschleissindex 65535 "Fehler" ;
VAL_ 1602 WIV_Russindex 65535 "Fehler" ;
